BU_:  Airbag BAP_Tester ICAS1_Gateway ICAS1_KommunikationsServer LE1 LE2 Motor_BEV Schaltbetaetigung

BU_:  Airbag BAP_Tester ICAS1_Gateway ICAS1_KommunikationsServer LE1 LE2 Motor_BEV Schaltbetaetigung

BO_ 190 Motor_56: 48 Motor_BEV
 SG_ Motor_56_CRC  : 0|8@1+ (1.000000,0.000000) [0.000000|255.000000] "" ICAS1_Gateway LE1 LE2
 SG_ Motor_56_BZ  : 8|4@1+ (1.000000,0.000000) [0.000000|15.000000] "" ICAS1_Gateway LE1 LE2
 SG_ MO_EM1_MinDrehzahl  : 12|14@1+ (2.000000,-10000.000000) [-10000.000000|22764.000000] "Unit_MinutInver" ICAS1_Gateway LE1
 SG_ MO_EM1_MaxDrehzahl  : 26|14@1+ (2.000000,-10000.000000) [-10000.000000|22764.000000] "Unit_MinutInver" ICAS1_Gateway LE1
 SG_ MO_EM1_DynLimit_AR  : 40|8@1+ (1.000000,0.000000) [0.000000|254.000000] "Unit_NewtoMeter" ICAS1_Gateway LE1
 SG_ MO_EM1_Periode_AR  : 48|8@1+ (0.001953,0.000000) [0.000000|0.496094] "Unit_Secon" ICAS1_Gateway LE1
 SG_ MO_EM1_SollMoment  : 56|12@1+ (0.500000,-1023.000000) [-1023.000000|1023.500000] "Unit_NewtoMeter" ICAS1_Gateway LE1
 SG_ MO_EM1_Sollmodus  : 68|4@1+ (1.000000,0.000000) [0.000000|15.000000] "" ICAS1_Gateway LE1
 SG_ MO_EM1_Min_Leistung  : 72|14@1+ (100.000000,-819000.000000) [-819000.000000|819100.000000] "Unit_Watt" ICAS1_Gateway LE1
 SG_ MO_EM1_Max_Leistung  : 86|14@1+ (100.000000,-819000.000000) [-819000.000000|819100.000000] "Unit_Watt" ICAS1_Gateway LE1
 SG_ MO_EM1_Min_Strom_Lim  : 100|13@1+ (0.500000,-2047.000000) [-2047.000000|2047.500000] "Unit_Amper" ICAS1_Gateway LE1
 SG_ MO_EM1_Max_Strom_Lim  : 113|13@1+ (0.500000,-2047.000000) [-2047.000000|2047.500000] "Unit_Amper" ICAS1_Gateway LE1
 SG_ MO_EM1_AR_Anf  : 126|3@1+ (1.000000,0.000000) [0.000000|7.000000] "" ICAS1_Gateway LE1
 SG_ MO_EM1_Kp_AR  : 129|9@1+ (0.003906,0.000000) [0.000000|1.992188] "Unit_NewtoMeterPerRPM" ICAS1_Gateway LE1
 SG_ MO_EM1_SollSpannung  : 138|12@1+ (0.500000,0.000000) [0.000000|2047.000000] "Unit_Volt" ICAS1_Gateway LE1
 SG_ MO_EM2_MinDrehzahl  : 156|14@1+ (2.000000,-10000.000000) [-10000.000000|22764.000000] "Unit_MinutInver" ICAS1_Gateway LE2
 SG_ MO_EM2_MaxDrehzahl  : 170|14@1+ (2.000000,-10000.000000) [-10000.000000|22764.000000] "Unit_MinutInver" ICAS1_Gateway LE2
 SG_ MO_EM2_DynLimit_AR  : 184|8@1+ (1.000000,0.000000) [0.000000|254.000000] "Unit_NewtoMeter" ICAS1_Gateway LE2
 SG_ MO_EM2_Periode_AR  : 192|8@1+ (0.001953,0.000000) [0.000000|0.496094] "Unit_Secon" ICAS1_Gateway LE2
 SG_ MO_EM2_SollMoment  : 200|12@1+ (0.500000,-1023.000000) [-1023.000000|1023.500000] "Unit_NewtoMeter" ICAS1_Gateway LE2
 SG_ MO_EM2_Sollmodus  : 212|4@1+ (1.000000,0.000000) [0.000000|15.000000] "" ICAS1_Gateway LE2
 SG_ MO_EM2_Min_Leistung  : 216|14@1+ (100.000000,-819000.000000) [-819000.000000|819100.000000] "Unit_Watt" ICAS1_Gateway LE2
 SG_ MO_EM2_Max_Leistung  : 230|14@1+ (100.000000,-819000.000000) [-819000.000000|819100.000000] "Unit_Watt" ICAS1_Gateway LE2
 SG_ MO_EM2_Min_Strom_Lim  : 244|13@1+ (0.500000,-2047.000000) [-2047.000000|2047.500000] "Unit_Amper" ICAS1_Gateway LE2
 SG_ MO_EM2_Max_Strom_Lim  : 257|13@1+ (0.500000,-2047.000000) [-2047.000000|2047.500000] "Unit_Amper" ICAS1_Gateway LE2
 SG_ MO_EM2_AR_Anf  : 270|3@1+ (1.000000,0.000000) [0.000000|7.000000] "" ICAS1_Gateway LE2
 SG_ MO_EM2_SollSpannung  : 282|12@1+ (0.500000,0.000000) [0.000000|2047.000000] "Unit_Volt" ICAS1_Gateway LE2
 SG_ MO_DC_Max_Strom_HV  : 296|8@1+ (0.200000,0.000000) [0.000000|50.800000] "Unit_Amper" ICAS1_Gateway
 SG_ MO_DC_SollSpannung_HV  : 304|8@1+ (2.000000,0.000000) [0.000000|508.000000] "Unit_Volt" ICAS1_Gateway
 SG_ MO_EM1_Max_Moment  : 312|12@1+ (0.500000,-1023.000000) [-1023.000000|1023.500000] "Unit_NewtoMeter" ICAS1_Gateway LE1
 SG_ MO_EM1_Min_Moment  : 324|12@1+ (0.500000,-1023.000000) [-1023.000000|1023.500000] "Unit_NewtoMeter" ICAS1_Gateway LE1
 SG_ MO_EM2_Max_Moment  : 336|12@1+ (0.500000,-1023.000000) [-1023.000000|1023.500000] "Unit_NewtoMeter" ICAS1_Gateway LE2
 SG_ MO_EM2_Min_Moment  : 348|12@1+ (0.500000,-1023.000000) [-1023.000000|1023.500000] "Unit_NewtoMeter" ICAS1_Gateway LE2

BO_ 2463978666 Motor_57: 32 Motor_BEV
 SG_ MO_EM1_Min_Spannung_Lim  : 12|10@1+ (1.000000,0.000000) [0.000000|1021.000000] "Unit_Volt" ICAS1_Gateway LE1
 SG_ MO_EM1_Max_Spannung_Lim  : 22|10@1+ (1.000000,0.000000) [0.000000|1021.000000] "Unit_Volt" ICAS1_Gateway LE1
 SG_ MO_EM1_Min_Leistung_Gesamt  : 32|13@1+ (200.000000,-819000.000000) [-819000.000000|818800.000000] "Unit_Watt" ICAS1_Gateway LE1
 SG_ MO_EM1_Max_Leistung_Gesamt  : 45|13@1+ (200.000000,-819000.000000) [-819000.000000|818800.000000] "Unit_Watt" ICAS1_Gateway LE1
 SG_ MO_EM2_Min_Leistung_Gesamt  : 58|13@1+ (200.000000,-819000.000000) [-819000.000000|818800.000000] "Unit_Watt" ICAS1_Gateway LE2
 SG_ MO_EM2_Max_Leistung_Gesamt  : 71|13@1+ (200.000000,-819000.000000) [-819000.000000|818800.000000] "Unit_Watt" ICAS1_Gateway LE2
 SG_ MO_EM2_Min_Spannung_Lim  : 84|10@1+ (1.000000,0.000000) [0.000000|1021.000000] "Unit_Volt" ICAS1_Gateway LE2
 SG_ MO_EM2_Max_Spannung_Lim  : 94|10@1+ (1.000000,0.000000) [0.000000|1021.000000] "Unit_Volt" ICAS1_Gateway LE2
 SG_ MO_EM1_Generator_Leistung  : 104|8@1+ (100.000000,0.000000) [0.000000|25300.000000] "Unit_Watt" ICAS1_Gateway LE1
 SG_ MO_Verbrauch_EM_Ges  : 120|15@1+ (10.000000,0.000000) [0.000000|327670.000000] "Unit_WattSecond" ICAS1_Gateway ICAS1_KommunikationsServer
 SG_ MO_Verbrauch_EM_Ges_Ueberlauf  : 135|1@1+ (1.000000,0.000000) [0.000000|1.000000] "" ICAS1_Gateway ICAS1_KommunikationsServer
 SG_ MO_Rekuperation_Ges_EM  : 136|15@1+ (10.000000,0.000000) [0.000000|327670.000000] "Unit_WattSecond" ICAS1_Gateway ICAS1_KommunikationsServer
 SG_ MO_Rekuperation_EM_Ges_Ueberlauf  : 151|1@1+ (1.000000,0.000000) [0.000000|1.000000] "" ICAS1_Gateway ICAS1_KommunikationsServer
 SG_ MO_Drehzahl_EM  : 152|13@1+ (8.000000,-32768.000000) [-32768.000000|32744.000000] "Unit_RevPerMinute" ICAS1_Gateway
 SG_ MO_Uebersetzung_EM  : 165|10@1+ (0.031250,0.000000) [0.031250|31.906250] "" ICAS1_Gateway
 SG_ MO_Drehzahl_EM_sek  : 175|13@1+ (8.000000,-32768.000000) [-32768.000000|32744.000000] "Unit_RevPerMinute" ICAS1_Gateway
 SG_ MO_Uebersetzung_EM_sek  : 188|10@1+ (0.031250,0.000000) [0.031250|31.906250] "" ICAS1_Gateway

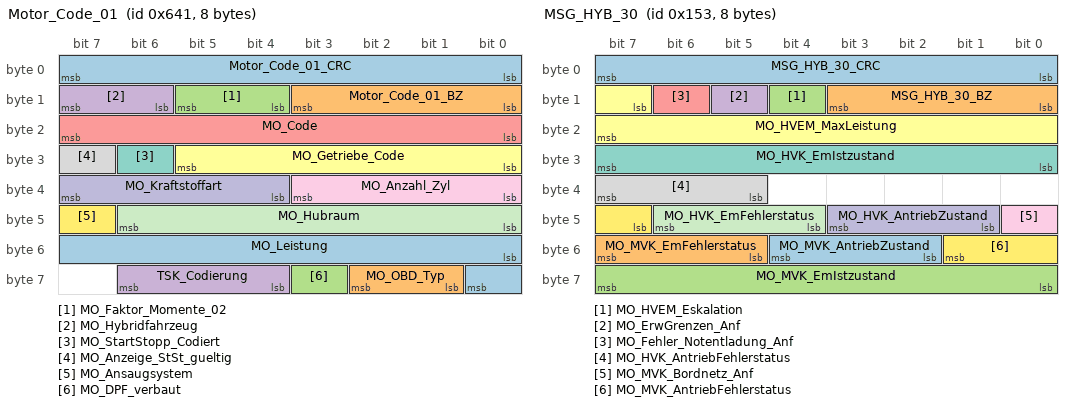
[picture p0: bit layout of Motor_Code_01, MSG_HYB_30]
BO_ 1601 Motor_Code_01: 8 Motor_BEV
 SG_ Motor_Code_01_CRC  : 0|8@1+ (1.000000,0.000000) [0.000000|255.000000] "" ICAS1_Gateway
 SG_ Motor_Code_01_BZ  : 8|4@1+ (1.000000,0.000000) [0.000000|15.000000] "" ICAS1_Gateway
 SG_ MO_Faktor_Momente_02  : 12|2@1+ (1.000000,0.000000) [1.000000|3.000000] "Unit_NewtoMeter" ICAS1_Gateway
 SG_ MO_Hybridfahrzeug  : 14|2@1+ (1.000000,0.000000) [0.000000|3.000000] "" ICAS1_Gateway
 SG_ MO_Code  : 16|8@1+ (1.000000,0.000000) [0.000000|255.000000] "" ICAS1_Gateway
 SG_ MO_Getriebe_Code  : 24|6@1+ (1.000000,0.000000) [0.000000|63.000000] "" ICAS1_Gateway
 SG_ MO_StartStopp_Codiert  : 30|1@1+ (1.000000,0.000000) [0.000000|1.000000] "" ICAS1_Gateway
 SG_ MO_Anzeige_StSt_gueltig  : 31|1@1+ (1.000000,0.000000) [0.000000|1.000000] "" ICAS1_Gateway
 SG_ MO_Anzahl_Zyl  : 32|4@1+ (1.000000,0.000000) [0.000000|15.000000] "" ICAS1_Gateway
 SG_ MO_Kraftstoffart  : 36|4@1+ (1.000000,0.000000) [0.000000|15.000000] "" ICAS1_Gateway ICAS1_KommunikationsServer
 SG_ MO_Hubraum  : 40|7@1+ (0.100000,0.000000) [0.000000|12.700000] "Unit_Liter" ICAS1_Gateway
 SG_ MO_Ansaugsystem  : 47|1@1+ (1.000000,0.000000) [0.000000|1.000000] "" ICAS1_Gateway
 SG_ MO_Leistung  : 48|9@1+ (1.000000,0.000000) [0.000000|511.000000] "Unit_KiloWatt" ICAS1_Gateway
 SG_ MO_OBD_Typ  : 57|2@1+ (1.000000,0.000000) [0.000000|3.000000] "" ICAS1_Gateway
 SG_ MO_DPF_verbaut  : 59|1@1+ (1.000000,0.000000) [0.000000|1.000000] "" ICAS1_Gateway
 SG_ TSK_Codierung  : 60|3@1+ (1.000000,0.000000) [0.000000|7.000000] "" ICAS1_Gateway

BO_ 1155 Motor_Hybrid_06: 8 Motor_BEV
 SG_ Mo_Powermeter_Grenze  : 0|12@1+ (1.000000,0.000000) [0.000000|4092.000000] "" ICAS1_KommunikationsServer
 SG_ MO_Text_Aktivierung_Antrieb  : 12|4@1+ (1.000000,0.000000) [0.000000|15.000000] "" ICAS1_KommunikationsServer
 SG_ MO_Powermeter_Inszenierung_aktiv  : 17|1@1+ (1.000000,0.000000) [0.000000|1.000000] "" Vector__XXX
 SG_ MO_Powermeter_Charge_Grenze  : 18|10@1+ (1.000000,0.000000) [0.000000|1021.000000] "Unit_None" ICAS1_KommunikationsServer
 SG_ MO_Powermeter_Grenze_strategisch  : 28|12@1+ (1.000000,0.000000) [0.000000|4093.000000] "Unit_None" ICAS1_KommunikationsServer
 SG_ MO_Powermeter_untere_E_Grenze  : 40|12@1+ (1.000000,0.000000) [0.000000|4093.000000] "Unit_None" Vector__XXX
 SG_ MO_Powermeter_obere_E_Grenze  : 52|12@1+ (1.000000,0.000000) [0.000000|4093.000000] "Unit_None" Vector__XXX

BO_ 2527679686 MRR_ASM_01: 8 ICAS1_Gateway
 SG_ MRR_HR_ASM_Ereignis  : 0|8@1+ (1.000000,0.000000) [1.000000|254.000000] "" Airbag
 SG_ MRR_HR_ASM_Zeitstempel  : 8|8@1+ (0.080000,0.000000) [0.000000|20.320000] "Unit_Secon" Airbag
 SG_ MRR_HR_ASM_Data_1  : 16|8@1+ (1.000000,0.000000) [0.000000|255.000000] "" Airbag
 SG_ MRR_HR_ASM_Data_2  : 24|8@1+ (1.000000,0.000000) [0.000000|255.000000] "" Airbag
 SG_ MRR_HR_ASM_Data_3  : 32|8@1+ (1.000000,0.000000) [0.000000|255.000000] "" Airbag
 SG_ MRR_HR_ASM_Data_4  : 40|8@1+ (1.000000,0.000000) [0.000000|255.000000] "" Airbag
 SG_ MRR_HR_ASM_Data_5  : 48|8@1+ (1.000000,0.000000) [0.000000|255.000000] "" Airbag
 SG_ MRR_HR_ASM_Data_6  : 56|8@1+ (1.000000,0.000000) [0.000000|255.000000] "" Airbag

BO_ 22 MSG3_WFS_Anfrage: 8 LE2
 SG_ WFS_MSG3_RND  : 0|32@1+ (1.000000,0.000000) [0.000000|4294967295.000000] "" ICAS1_Gateway
 SG_ WFS_MSG3_CRC  : 32|32@1+ (1.000000,0.000000) [0.000000|4294967295.000000] "" ICAS1_Gateway

BO_ 24 MSG4_WFS_Anfrage: 8 LE1
 SG_ WFS_MSG4_RND  : 0|32@1+ (1.000000,0.000000) [0.000000|4294967295.000000] "" ICAS1_Gateway
 SG_ WFS_MSG4_CRC  : 32|32@1+ (1.000000,0.000000) [0.000000|4294967295.000000] "" ICAS1_Gateway

BO_ 339 MSG_HYB_30: 8 Motor_BEV
 SG_ MSG_HYB_30_CRC  : 0|8@1+ (1.000000,0.000000) [0.000000|255.000000] "" Vector__XXX
 SG_ MSG_HYB_30_BZ  : 8|4@1+ (1.000000,0.000000) [0.000000|15.000000] "" Vector__XXX
 SG_ MO_HVEM_Eskalation  : 12|1@1+ (1.000000,0.000000) [0.000000|1.000000] "" ICAS1_Gateway
 SG_ MO_ErwGrenzen_Anf  : 13|1@1+ (1.000000,0.000000) [0.000000|1.000000] "" LE1 LE2
 SG_ MO_Fehler_Notentladung_Anf  : 14|1@1+ (1.000000,0.000000) [0.000000|1.000000] "" Vector__XXX
 SG_ MO_HVEM_MaxLeistung  : 15|9@1+ (50.000000,0.000000) [0.000000|25450.000000] "Unit_Watt" ICAS1_Gateway
 SG_ MO_HVK_EmIstzustand  : 24|8@1+ (1.000000,0.000000) [0.000000|255.000000] "" Vector__XXX
 SG_ MO_HVK_AntriebFehlerstatus  : 37|3@1+ (1.000000,0.000000) [0.000000|7.000000] "" Vector__XXX
 SG_ MO_MVK_Bordnetz_Anf  : 40|1@1+ (1.000000,0.000000) [0.000000|1.000000] "" Vector__XXX
 SG_ MO_HVK_AntriebZustand  : 41|3@1+ (1.000000,0.000000) [0.000000|7.000000] "" Vector__XXX
 SG_ MO_HVK_EmFehlerstatus  : 44|3@1+ (1.000000,0.000000) [0.000000|7.000000] "" Vector__XXX
 SG_ MO_MVK_AntriebFehlerstatus  : 47|3@1+ (1.000000,0.000000) [0.000000|7.000000] "" Vector__XXX
 SG_ MO_MVK_AntriebZustand  : 50|3@1+ (1.000000,0.000000) [0.000000|7.000000] "" Vector__XXX
 SG_ MO_MVK_EmFehlerstatus  : 53|3@1+ (1.000000,0.000000) [0.000000|7.000000] "" Vector__XXX
 SG_ MO_MVK_EmIstzustand  : 56|8@1+ (1.000000,0.000000) [0.000000|255.000000] "" Vector__XXX

BO_ 2600468501 NMH_Airbag_01: 8 Airbag
 SG_ NM_Airbag_01_CBV_AWB  : 12|1@1+ (1.000000,0.000000) [0.000000|1.000000] "" ICAS1_Gateway
 SG_ NM_Airbag_01_CBV_CRI  : 14|1@1+ (1.000000,0.000000) [0.000000|1.000000] "" ICAS1_Gateway
 SG_ NM_Airbag_01_NM_State  : 16|6@1+ (1.000000,0.000000) [0.000000|63.000000] "" LE1 LE2 Motor_BEV Schaltbetaetigung
 SG_ NM_Airbag_01_Car_Wakeup  : 22|1@1+ (1.000000,0.000000) [0.000000|1.000000] "" ICAS1_Gateway
 SG_ NM_Airbag_01_UDS_CC  : 23|1@1+ (1.000000,0.000000) [0.000000|1.000000] "" Vector__XXX
 SG_ NM_Airbag_01_NM_aktiv_KL15  : 24|1@1+ (1.000000,0.000000) [0.000000|1.000000] "" Vector__XXX
 SG_ NM_Airbag_01_NM_aktiv_Diagnose  : 25|1@1+ (1.000000,0.000000) [0.000000|1.000000] "" Vector__XXX
 SG_ NM_Airbag_01_NM_aktiv_Tmin  : 26|1@1+ (1.000000,0.000000) [0.000000|1.000000] "" Vector__XXX
 SG_ NM_Airbag_01_CAB_V10  : 40|24@1+ (1.000000,0.000000) [0.000000|16777215.000000] "" ICAS1_Gateway

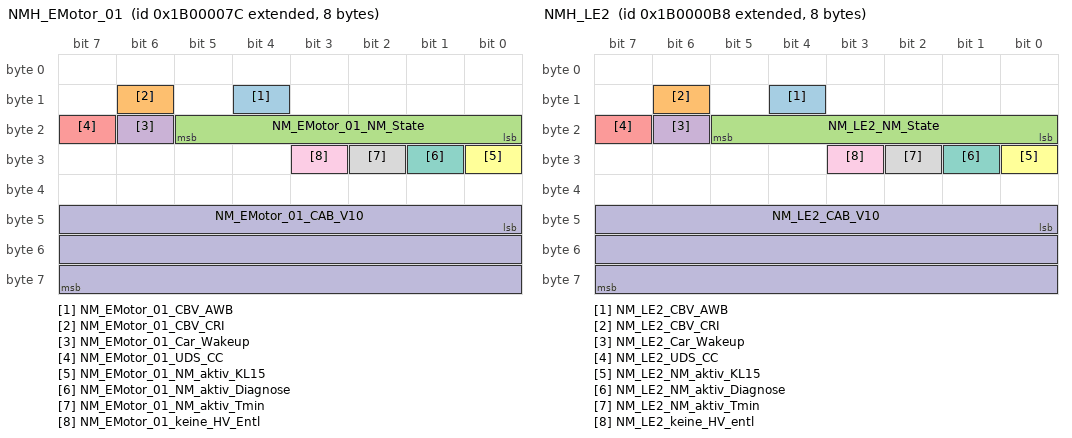
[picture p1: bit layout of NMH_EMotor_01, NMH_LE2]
BO_ 2600468604 NMH_EMotor_01: 8 LE1
 SG_ NM_EMotor_01_CBV_AWB  : 12|1@1+ (1.000000,0.000000) [0.000000|1.000000] "" ICAS1_Gateway
 SG_ NM_EMotor_01_CBV_CRI  : 14|1@1+ (1.000000,0.000000) [0.000000|1.000000] "" ICAS1_Gateway
 SG_ NM_EMotor_01_NM_State  : 16|6@1+ (1.000000,0.000000) [0.000000|63.000000] "" Airbag LE2 Motor_BEV Schaltbetaetigung
 SG_ NM_EMotor_01_Car_Wakeup  : 22|1@1+ (1.000000,0.000000) [0.000000|1.000000] "" ICAS1_Gateway
 SG_ NM_EMotor_01_UDS_CC  : 23|1@1+ (1.000000,0.000000) [0.000000|1.000000] "" Vector__XXX
 SG_ NM_EMotor_01_NM_aktiv_KL15  : 24|1@1+ (1.000000,0.000000) [0.000000|1.000000] "" Vector__XXX
 SG_ NM_EMotor_01_NM_aktiv_Diagnose  : 25|1@1+ (1.000000,0.000000) [0.000000|1.000000] "" Vector__XXX
 SG_ NM_EMotor_01_NM_aktiv_Tmin  : 26|1@1+ (1.000000,0.000000) [0.000000|1.000000] "" Vector__XXX
 SG_ NM_EMotor_01_keine_HV_Entl  : 27|1@1+ (1.000000,0.000000) [0.000000|1.000000] "" Vector__XXX
 SG_ NM_EMotor_01_CAB_V10  : 40|24@1+ (1.000000,0.000000) [0.000000|16777215.000000] "" ICAS1_Gateway

BO_ 2600468496 NMH_Gateway: 8 ICAS1_Gateway
 SG_ NM_Gateway_CBV_AWB  : 12|1@1+ (1.000000,0.000000) [0.000000|1.000000] "" Vector__XXX
 SG_ NM_Gateway_CBV_CRI  : 14|1@1+ (1.000000,0.000000) [0.000000|1.000000] "" Vector__XXX
 SG_ NM_Gateway_NM_State  : 16|6@1+ (1.000000,0.000000) [0.000000|63.000000] "" Airbag LE1 LE2 Motor_BEV Schaltbetaetigung
 SG_ NM_Gateway_Car_Wakeup  : 22|1@1+ (1.000000,0.000000) [0.000000|1.000000] "" Vector__XXX
 SG_ NM_Gateway_UDS_CC  : 23|1@1+ (1.000000,0.000000) [0.000000|1.000000] "" Vector__XXX
 SG_ NM_Gateway_NM_aktiv_KL15  : 24|1@1+ (1.000000,0.000000) [0.000000|1.000000] "" Vector__XXX
 SG_ NM_Gateway_NM_aktiv_Diagnose  : 25|1@1+ (1.000000,0.000000) [0.000000|1.000000] "" Vector__XXX
 SG_ NM_Gateway_NM_aktiv_Tmin  : 26|1@1+ (1.000000,0.000000) [0.000000|1.000000] "" Vector__XXX
 SG_ NM_Gateway_CAB_V10  : 40|24@1+ (1.000000,0.000000) [0.000000|16777215.000000] "" Vector__XXX

BO_ 2600468664 NMH_LE2: 8 LE2
 SG_ NM_LE2_CBV_AWB  : 12|1@1+ (1.000000,0.000000) [0.000000|1.000000] "" ICAS1_Gateway
 SG_ NM_LE2_CBV_CRI  : 14|1@1+ (1.000000,0.000000) [0.000000|1.000000] "" ICAS1_Gateway
 SG_ NM_LE2_NM_State  : 16|6@1+ (1.000000,0.000000) [0.000000|63.000000] "" Airbag LE1 Motor_BEV Schaltbetaetigung
 SG_ NM_LE2_Car_Wakeup  : 22|1@1+ (1.000000,0.000000) [0.000000|1.000000] "" ICAS1_Gateway
 SG_ NM_LE2_UDS_CC  : 23|1@1+ (1.000000,0.000000) [0.000000|1.000000] "" Vector__XXX
 SG_ NM_LE2_NM_aktiv_KL15  : 24|1@1+ (1.000000,0.000000) [0.000000|1.000000] "" Vector__XXX
 SG_ NM_LE2_NM_aktiv_Diagnose  : 25|1@1+ (1.000000,0.000000) [0.000000|1.000000] "" Vector__XXX
 SG_ NM_LE2_NM_aktiv_Tmin  : 26|1@1+ (1.000000,0.000000) [0.000000|1.000000] "" Vector__XXX
 SG_ NM_LE2_keine_HV_entl  : 27|1@1+ (1.000000,0.000000) [0.000000|1.000000] "" Vector__XXX
 SG_ NM_LE2_CAB_V10  : 40|24@1+ (1.000000,0.000000) [0.000000|16777215.000000] "" ICAS1_Gateway

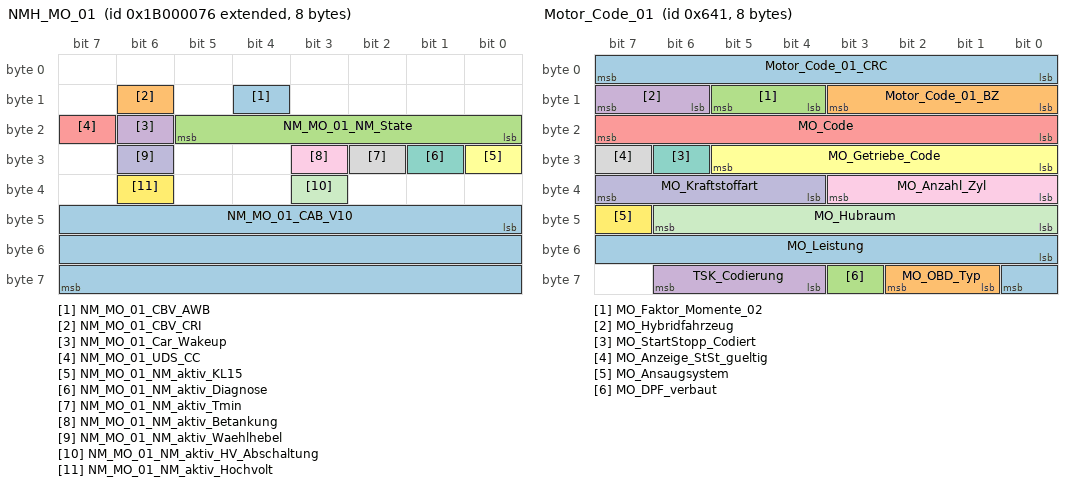
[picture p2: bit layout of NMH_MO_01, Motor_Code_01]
BO_ 2600468598 NMH_MO_01: 8 Motor_BEV
 SG_ NM_MO_01_CBV_AWB  : 12|1@1+ (1.000000,0.000000) [0.000000|1.000000] "" ICAS1_Gateway
 SG_ NM_MO_01_CBV_CRI  : 14|1@1+ (1.000000,0.000000) [0.000000|1.000000] "" ICAS1_Gateway
 SG_ NM_MO_01_NM_State  : 16|6@1+ (1.000000,0.000000) [0.000000|63.000000] "" Airbag LE1 LE2 Schaltbetaetigung
 SG_ NM_MO_01_Car_Wakeup  : 22|1@1+ (1.000000,0.000000) [0.000000|1.000000] "" ICAS1_Gateway
 SG_ NM_MO_01_UDS_CC  : 23|1@1+ (1.000000,0.000000) [0.000000|1.000000] "" Vector__XXX
 SG_ NM_MO_01_NM_aktiv_KL15  : 24|1@1+ (1.000000,0.000000) [0.000000|1.000000] "" Vector__XXX
 SG_ NM_MO_01_NM_aktiv_Diagnose  : 25|1@1+ (1.000000,0.000000) [0.000000|1.000000] "" Vector__XXX
 SG_ NM_MO_01_NM_aktiv_Tmin  : 26|1@1+ (1.000000,0.000000) [0.000000|1.000000] "" Vector__XXX
 SG_ NM_MO_01_NM_aktiv_Betankung  : 27|1@1+ (1.000000,0.000000) [0.000000|1.000000] "" Vector__XXX
 SG_ NM_MO_01_NM_aktiv_Waehlhebel  : 30|1@1+ (1.000000,0.000000) [0.000000|1.000000] "" Vector__XXX
 SG_ NM_MO_01_NM_aktiv_HV_Abschaltung  : 35|1@1+ (1.000000,0.000000) [0.000000|1.000000] "" Vector__XXX
 SG_ NM_MO_01_NM_aktiv_Hochvolt  : 38|1@1+ (1.000000,0.000000) [0.000000|1.000000] "" Vector__XXX
 SG_ NM_MO_01_CAB_V10  : 40|24@1+ (1.000000,0.000000) [0.000000|16777215.000000] "" ICAS1_Gateway

BO_ 2600468733 NMH_Waehlhebel: 8 Schaltbetaetigung
 SG_ NM_Waehlhebel_CBV_AWB  : 12|1@1+ (1.000000,0.000000) [0.000000|1.000000] "" ICAS1_Gateway
 SG_ NM_Waehlhebel_CBV_CRI  : 14|1@1+ (1.000000,0.000000) [0.000000|1.000000] "" ICAS1_Gateway
 SG_ NM_Waehlhebel_NM_State  : 16|6@1+ (1.000000,0.000000) [0.000000|63.000000] "" Airbag LE1 LE2 Motor_BEV
 SG_ NM_Waehlhebel_Car_Wakeup  : 22|1@1+ (1.000000,0.000000) [0.000000|1.000000] "" ICAS1_Gateway
 SG_ NM_Waehlhebel_UDS_CC  : 23|1@1+ (1.000000,0.000000) [0.000000|1.000000] "" Vector__XXX
 SG_ NM_Waehlhebel_NM_aktiv_KL15  : 24|1@1+ (1.000000,0.000000) [0.000000|1.000000] "" Vector__XXX
 SG_ NM_Waehlhebel_NM_aktiv_Diagnose  : 25|1@1+ (1.000000,0.000000) [0.000000|1.000000] "" Vector__XXX
 SG_ NM_Waehlhebel_NM_aktiv_Tmin  : 26|1@1+ (1.000000,0.000000) [0.000000|1.000000] "" Vector__XXX
 SG_ NM_Waehlhebel_CAB_V10  : 40|24@1+ (1.000000,0.000000) [0.000000|16777215.000000] "" ICAS1_Gateway

BO_ 2621440533 OBDC_Airbag_01_Req_FD: 64 ICAS1_Gateway
 SG_ OBDC_Airbag_01_Req_FD_Data  : 0|512@1+ (1.000000,0.000000) [0.000000|13407807929942597099574024998205846127479365820592393377723561443721764030073546976801874298166903427690031858186486050853753882811946569946433649006084096.000000] "" Airbag

BO_ 2621571605 OBDC_Airbag_01_Resp_FD: 64 Airbag
 SG_ OBDC_Airbag_01_Resp_FD_Data  : 0|512@1+ (1.000000,0.000000) [0.000000|13407807929942597099574024998205846127479365820592393377723561443721764030073546976801874298166903427690031858186486050853753882811946569946433649006084096.000000] "" ICAS1_Gateway

BO_ 2621440636 OBDC_EMotor_01_Req_FD: 64 ICAS1_Gateway
 SG_ OBDC_EMotor_01_Req_FD_Data  : 0|512@1+ (1.000000,0.000000) [0.000000|13407807929942597099574024998205846127479365820592393377723561443721764030073546976801874298166903427690031858186486050853753882811946569946433649006084096.000000] "" LE1

BO_ 2621571708 OBDC_EMotor_01_Resp_FD: 64 LE1
 SG_ OBDC_EMotor_01_Resp_FD_Data  : 0|512@1+ (1.000000,0.000000) [0.000000|13407807929942597099574024998205846127479365820592393377723561443721764030073546976801874298166903427690031858186486050853753882811946569946433649006084096.000000] "" ICAS1_Gateway

BO_ 2621440696 OBDC_EMotor_02_Req_FD: 64 ICAS1_Gateway
 SG_ OBDC_EMotor_02_Req_FD_Data  : 0|512@1+ (1.000000,0.000000) [0.000000|13407807929942597099574024998205846127479365820592393377723561443721764030073546976801874298166903427690031858186486050853753882811946569946433649006084096.000000] "" LE2

BO_ 2621571768 OBDC_EMotor_02_Resp_FD: 64 LE2
 SG_ OBDC_EMotor_02_Resp_FD_Data  : 0|512@1+ (1.000000,0.000000) [0.000000|13407807929942597099574024998205846127479365820592393377723561443721764030073546976801874298166903427690031858186486050853753882811946569946433649006084096.000000] "" ICAS1_Gateway

BO_ 2621506048 OBDC_Funktionaler_Req_All_FD: 64 ICAS1_Gateway
 SG_ OBDC_Funktion_Req_All_FD_Data  : 0|512@1+ (1.000000,0.000000) [0.000000|13407807929942597099574024998205846127479365820592393377723561443721764030073546976801874298166903427690031858186486050853753882811946569946433649006084096.000000] "" Airbag LE1 LE2 Motor_BEV

BO_ 2621440630 OBDC_MO_01_Req_FD: 64 ICAS1_Gateway
 SG_ OBDC_MO_01_Req_FD_Data  : 0|512@1+ (1.000000,0.000000) [0.000000|13407807929942597099574024998205846127479365820592393377723561443721764030073546976801874298166903427690031858186486050853753882811946569946433649006084096.000000] "" Motor_BEV

BO_ 2621571702 OBDC_MO_01_Resp_FD: 64 Motor_BEV
 SG_ OBDC_MO_01_Resp_FD_Data  : 0|512@1+ (1.000000,0.000000) [0.000000|13407807929942597099574024998205846127479365820592393377723561443721764030073546976801874298166903427690031858186486050853753882811946569946433649006084096.000000] "" ICAS1_Gateway

BO_ 2564502513 OBDx_allOBD_Req: 8 ICAS1_Gateway
 SG_ OBDx_allOBD_Req_Data  : 0|64@1+ (1.000000,0.000000) [0.000000|18446744073709551616.000000] "" LE1 LE2 Motor_BEV

BO_ 2564425457 OBDx_LE1_Req: 8 ICAS1_Gateway
 SG_ OBDx_LE1_Req_Data  : 0|64@1+ (1.000000,0.000000) [0.000000|18446744073709551616.000000] "" LE1

BO_ 2564485382 OBDx_LE1_Resp: 8 LE1
 SG_ OBDx_LE1_Resp_Data  : 0|64@1+ (1.000000,0.000000) [0.000000|18446744073709551616.000000] "" ICAS1_Gateway

BO_ 2564425713 OBDx_LE2_Req: 8 ICAS1_Gateway
 SG_ OBDx_LE2_Req_Data  : 0|64@1+ (1.000000,0.000000) [0.000000|18446744073709551616.000000] "" LE2

BO_ 2564485383 OBDx_LE2_Resp: 8 LE2
 SG_ OBDx_LE2_Resp_Data  : 0|64@1+ (1.000000,0.000000) [0.000000|18446744073709551616.000000] "" ICAS1_Gateway

BO_ 2564424177 OBDx_MO_01_Req: 8 ICAS1_Gateway
 SG_ OBDx_MO_01_Req_Data  : 0|64@1+ (1.000000,0.000000) [0.000000|18446744073709551616.000000] "" Motor_BEV

BO_ 2564485377 OBDx_MO_01_Resp: 8 Motor_BEV
 SG_ OBDx_MO_01_Resp_Data  : 0|64@1+ (1.000000,0.000000) [0.000000|18446744073709551616.000000] "" ICAS1_Gateway

BO_ 627 OCC_01: 24 ICAS1_Gateway
 SG_ OCC_01_CRC  : 0|8@1+ (1.000000,0.000000) [0.000000|255.000000] "" Vector__XXX
 SG_ OCC_01_BZ  : 8|4@1+ (1.000000,0.000000) [0.000000|15.000000] "" Vector__XXX
 SG_ OCC_Stecker_Status  : 12|2@1+ (1.000000,0.000000) [0.000000|3.000000] "" Vector__XXX
 SG_ OCC_Status_Spgfreiheit  : 14|2@1+ (1.000000,0.000000) [0.000000|3.000000] "" Motor_BEV
 SG_ OCC_DC_IstStrom  : 16|11@1+ (0.100000,0.000000) [0.000000|204.500000] "Unit_Amper" Vector__XXX
 SG_ OCC_CC_Latchstatus_DC_GBT  : 27|3@1+ (1.000000,0.000000) [0.000000|7.000000] "" Vector__XXX
 SG_ OCC_Status_EoHVL  : 30|2@1+ (1.000000,0.000000) [0.000000|3.000000] "" Motor_BEV
 SG_ OCC_I_istAC_Netz_L1  : 32|9@1+ (0.100000,0.000000) [0.000000|50.800000] "Unit_Amper" Vector__XXX
 SG_ OCC_PP_Latchstatus_A  : 41|3@1+ (1.000000,0.000000) [0.000000|7.000000] "" Vector__XXX
 SG_ OCC_PP_Latchstatus_B  : 44|3@1+ (1.000000,0.000000) [0.000000|7.000000] "" Vector__XXX
 SG_ OCC_I_istAC_Netz_L2  : 47|9@1+ (0.100000,0.000000) [0.000000|50.800000] "Unit_Amper" Vector__XXX
 SG_ OCC_I_istAC_Netz_L3  : 56|9@1+ (0.100000,0.000000) [0.000000|50.800000] "Unit_Amper" Vector__XXX
 SG_ OCC_IstModus  : 65|3@1+ (1.000000,0.000000) [0.000000|7.000000] "" Motor_BEV
 SG_ OCC_CP_Status_A  : 68|2@1+ (1.000000,0.000000) [0.000000|3.000000] "" Vector__XXX
 SG_ OCC_CP_Status_B  : 70|2@1+ (1.000000,0.000000) [0.000000|3.000000] "" Vector__XXX
 SG_ OCC_IstSpannung_HV  : 72|10@1+ (1.000000,0.000000) [0.000000|1021.000000] "Unit_Volt" Vector__XXX
 SG_ OCC_PP_Status_A  : 82|2@1+ (1.000000,0.000000) [0.000000|3.000000] "" Vector__XXX
 SG_ OCC_PP_Status_B  : 84|2@1+ (1.000000,0.000000) [0.000000|3.000000] "" Vector__XXX
 SG_ OCC_CC_Status_DC_GBT  : 86|2@1+ (1.000000,0.000000) [0.000000|3.000000] "" Vector__XXX
 SG_ OCC_CC_Fehlerstatus_DC_GBT  : 88|4@1+ (1.000000,0.000000) [0.000000|15.000000] "" Vector__XXX
 SG_ OCC_Temp_Sensor_Fehlerstatus_DC  : 92|4@1+ (1.000000,0.000000) [0.000000|15.000000] "" Vector__XXX
 SG_ OCC_Temp_Sensor_Fehlerstatus_AC  : 96|3@1+ (1.000000,0.000000) [0.000000|7.000000] "" Vector__XXX
 SG_ OCC_Temp_Sensor_Status  : 99|3@1+ (1.000000,0.000000) [0.000000|7.000000] "" Vector__XXX

BU_:  Airbag BAP_Tester ICAS1_Gateway ICAS1_KommunikationsServer LE1 LE2 Motor_BEV Schaltbetaetigung

BO_ 190 Motor_56: 48 Motor_BEV
 SG_ Motor_56_CRC  : 0|8@1+ (1.000000,0.000000) [0.000000|255.000000] "" ICAS1_Gateway LE1 LE2
 SG_ Motor_56_BZ  : 8|4@1+ (1.000000,0.000000) [0.000000|15.000000] "" ICAS1_Gateway LE1 LE2
 SG_ MO_EM1_MinDrehzahl  : 12|14@1+ (2.000000,-10000.000000) [-10000.000000|22764.000000] "Unit_MinutInver" ICAS1_Gateway LE1
 SG_ MO_EM1_MaxDrehzahl  : 26|14@1+ (2.000000,-10000.000000) [-10000.000000|22764.000000] "Unit_MinutInver" ICAS1_Gateway LE1
 SG_ MO_EM1_DynLimit_AR  : 40|8@1+ (1.000000,0.000000) [0.000000|254.000000] "Unit_NewtoMeter" ICAS1_Gateway LE1
 SG_ MO_EM1_Periode_AR  : 48|8@1+ (0.001953,0.000000) [0.000000|0.496094] "Unit_Secon" ICAS1_Gateway LE1
 SG_ MO_EM1_SollMoment  : 56|12@1+ (0.500000,-1023.000000) [-1023.000000|1023.500000] "Unit_NewtoMeter" ICAS1_Gateway LE1
 SG_ MO_EM1_Sollmodus  : 68|4@1+ (1.000000,0.000000) [0.000000|15.000000] "" ICAS1_Gateway LE1
 SG_ MO_EM1_Min_Leistung  : 72|14@1+ (100.000000,-819000.000000) [-819000.000000|819100.000000] "Unit_Watt" ICAS1_Gateway LE1
 SG_ MO_EM1_Max_Leistung  : 86|14@1+ (100.000000,-819000.000000) [-819000.000000|819100.000000] "Unit_Watt" ICAS1_Gateway LE1
 SG_ MO_EM1_Min_Strom_Lim  : 100|13@1+ (0.500000,-2047.000000) [-2047.000000|2047.500000] "Unit_Amper" ICAS1_Gateway LE1
 SG_ MO_EM1_Max_Strom_Lim  : 113|13@1+ (0.500000,-2047.000000) [-2047.000000|2047.500000] "Unit_Amper" ICAS1_Gateway LE1
 SG_ MO_EM1_AR_Anf  : 126|3@1+ (1.000000,0.000000) [0.000000|7.000000] "" ICAS1_Gateway LE1
 SG_ MO_EM1_Kp_AR  : 129|9@1+ (0.003906,0.000000) [0.000000|1.992188] "Unit_NewtoMeterPerRPM" ICAS1_Gateway LE1
 SG_ MO_EM1_SollSpannung  : 138|12@1+ (0.500000,0.000000) [0.000000|2047.000000] "Unit_Volt" ICAS1_Gateway LE1
 SG_ MO_EM2_MinDrehzahl  : 156|14@1+ (2.000000,-10000.000000) [-10000.000000|22764.000000] "Unit_MinutInver" ICAS1_Gateway LE2
 SG_ MO_EM2_MaxDrehzahl  : 170|14@1+ (2.000000,-10000.000000) [-10000.000000|22764.000000] "Unit_MinutInver" ICAS1_Gateway LE2
 SG_ MO_EM2_DynLimit_AR  : 184|8@1+ (1.000000,0.000000) [0.000000|254.000000] "Unit_NewtoMeter" ICAS1_Gateway LE2
 SG_ MO_EM2_Periode_AR  : 192|8@1+ (0.001953,0.000000) [0.000000|0.496094] "Unit_Secon" ICAS1_Gateway LE2
 SG_ MO_EM2_SollMoment  : 200|12@1+ (0.500000,-1023.000000) [-1023.000000|1023.500000] "Unit_NewtoMeter" ICAS1_Gateway LE2
 SG_ MO_EM2_Sollmodus  : 212|4@1+ (1.000000,0.000000) [0.000000|15.000000] "" ICAS1_Gateway LE2
 SG_ MO_EM2_Min_Leistung  : 216|14@1+ (100.000000,-819000.000000) [-819000.000000|819100.000000] "Unit_Watt" ICAS1_Gateway LE2
 SG_ MO_EM2_Max_Leistung  : 230|14@1+ (100.000000,-819000.000000) [-819000.000000|819100.000000] "Unit_Watt" ICAS1_Gateway LE2
 SG_ MO_EM2_Min_Strom_Lim  : 244|13@1+ (0.500000,-2047.000000) [-2047.000000|2047.500000] "Unit_Amper" ICAS1_Gateway LE2
 SG_ MO_EM2_Max_Strom_Lim  : 257|13@1+ (0.500000,-2047.000000) [-2047.000000|2047.500000] "Unit_Amper" ICAS1_Gateway LE2
 SG_ MO_EM2_AR_Anf  : 270|3@1+ (1.000000,0.000000) [0.000000|7.000000] "" ICAS1_Gateway LE2
 SG_ MO_EM2_SollSpannung  : 282|12@1+ (0.500000,0.000000) [0.000000|2047.000000] "Unit_Volt" ICAS1_Gateway LE2
 SG_ MO_DC_Max_Strom_HV  : 296|8@1+ (0.200000,0.000000) [0.000000|50.800000] "Unit_Amper" ICAS1_Gateway
 SG_ MO_DC_SollSpannung_HV  : 304|8@1+ (2.000000,0.000000) [0.000000|508.000000] "Unit_Volt" ICAS1_Gateway
 SG_ MO_EM1_Max_Moment  : 312|12@1+ (0.500000,-1023.000000) [-1023.000000|1023.500000] "Unit_NewtoMeter" ICAS1_Gateway LE1
 SG_ MO_EM1_Min_Moment  : 324|12@1+ (0.500000,-1023.000000) [-1023.000000|1023.500000] "Unit_NewtoMeter" ICAS1_Gateway LE1
 SG_ MO_EM2_Max_Moment  : 336|12@1+ (0.500000,-1023.000000) [-1023.000000|1023.500000] "Unit_NewtoMeter" ICAS1_Gateway LE2
 SG_ MO_EM2_Min_Moment  : 348|12@1+ (0.500000,-1023.000000) [-1023.000000|1023.500000] "Unit_NewtoMeter" ICAS1_Gateway LE2

BO_ 2463978666 Motor_57: 32 Motor_BEV
 SG_ MO_EM1_Min_Spannung_Lim  : 12|10@1+ (1.000000,0.000000) [0.000000|1021.000000] "Unit_Volt" ICAS1_Gateway LE1
 SG_ MO_EM1_Max_Spannung_Lim  : 22|10@1+ (1.000000,0.000000) [0.000000|1021.000000] "Unit_Volt" ICAS1_Gateway LE1
 SG_ MO_EM1_Min_Leistung_Gesamt  : 32|13@1+ (200.000000,-819000.000000) [-819000.000000|818800.000000] "Unit_Watt" ICAS1_Gateway LE1
 SG_ MO_EM1_Max_Leistung_Gesamt  : 45|13@1+ (200.000000,-819000.000000) [-819000.000000|818800.000000] "Unit_Watt" ICAS1_Gateway LE1
 SG_ MO_EM2_Min_Leistung_Gesamt  : 58|13@1+ (200.000000,-819000.000000) [-819000.000000|818800.000000] "Unit_Watt" ICAS1_Gateway LE2
 SG_ MO_EM2_Max_Leistung_Gesamt  : 71|13@1+ (200.000000,-819000.000000) [-819000.000000|818800.000000] "Unit_Watt" ICAS1_Gateway LE2
 SG_ MO_EM2_Min_Spannung_Lim  : 84|10@1+ (1.000000,0.000000) [0.000000|1021.000000] "Unit_Volt" ICAS1_Gateway LE2
 SG_ MO_EM2_Max_Spannung_Lim  : 94|10@1+ (1.000000,0.000000) [0.000000|1021.000000] "Unit_Volt" ICAS1_Gateway LE2
 SG_ MO_EM1_Generator_Leistung  : 104|8@1+ (100.000000,0.000000) [0.000000|25300.000000] "Unit_Watt" ICAS1_Gateway LE1
 SG_ MO_Verbrauch_EM_Ges  : 120|15@1+ (10.000000,0.000000) [0.000000|327670.000000] "Unit_WattSecond" ICAS1_Gateway ICAS1_KommunikationsServer
 SG_ MO_Verbrauch_EM_Ges_Ueberlauf  : 135|1@1+ (1.000000,0.000000) [0.000000|1.000000] "" ICAS1_Gateway ICAS1_KommunikationsServer
 SG_ MO_Rekuperation_Ges_EM  : 136|15@1+ (10.000000,0.000000) [0.000000|327670.000000] "Unit_WattSecond" ICAS1_Gateway ICAS1_KommunikationsServer
 SG_ MO_Rekuperation_EM_Ges_Ueberlauf  : 151|1@1+ (1.000000,0.000000) [0.000000|1.000000] "" ICAS1_Gateway ICAS1_KommunikationsServer
 SG_ MO_Drehzahl_EM  : 152|13@1+ (8.000000,-32768.000000) [-32768.000000|32744.000000] "Unit_RevPerMinute" ICAS1_Gateway
 SG_ MO_Uebersetzung_EM  : 165|10@1+ (0.031250,0.000000) [0.031250|31.906250] "" ICAS1_Gateway
 SG_ MO_Drehzahl_EM_sek  : 175|13@1+ (8.000000,-32768.000000) [-32768.000000|32744.000000] "Unit_RevPerMinute" ICAS1_Gateway
 SG_ MO_Uebersetzung_EM_sek  : 188|10@1+ (0.031250,0.000000) [0.031250|31.906250] "" ICAS1_Gateway

BO_ 1601 Motor_Code_01: 8 Motor_BEV
 SG_ Motor_Code_01_CRC  : 0|8@1+ (1.000000,0.000000) [0.000000|255.000000] "" ICAS1_Gateway
 SG_ Motor_Code_01_BZ  : 8|4@1+ (1.000000,0.000000) [0.000000|15.000000] "" ICAS1_Gateway
 SG_ MO_Faktor_Momente_02  : 12|2@1+ (1.000000,0.000000) [1.000000|3.000000] "Unit_NewtoMeter" ICAS1_Gateway
 SG_ MO_Hybridfahrzeug  : 14|2@1+ (1.000000,0.000000) [0.000000|3.000000] "" ICAS1_Gateway
 SG_ MO_Code  : 16|8@1+ (1.000000,0.000000) [0.000000|255.000000] "" ICAS1_Gateway
 SG_ MO_Getriebe_Code  : 24|6@1+ (1.000000,0.000000) [0.000000|63.000000] "" ICAS1_Gateway
 SG_ MO_StartStopp_Codiert  : 30|1@1+ (1.000000,0.000000) [0.000000|1.000000] "" ICAS1_Gateway
 SG_ MO_Anzeige_StSt_gueltig  : 31|1@1+ (1.000000,0.000000) [0.000000|1.000000] "" ICAS1_Gateway
 SG_ MO_Anzahl_Zyl  : 32|4@1+ (1.000000,0.000000) [0.000000|15.000000] "" ICAS1_Gateway
 SG_ MO_Kraftstoffart  : 36|4@1+ (1.000000,0.000000) [0.000000|15.000000] "" ICAS1_Gateway ICAS1_KommunikationsServer
 SG_ MO_Hubraum  : 40|7@1+ (0.100000,0.000000) [0.000000|12.700000] "Unit_Liter" ICAS1_Gateway
 SG_ MO_Ansaugsystem  : 47|1@1+ (1.000000,0.000000) [0.000000|1.000000] "" ICAS1_Gateway
 SG_ MO_Leistung  : 48|9@1+ (1.000000,0.000000) [0.000000|511.000000] "Unit_KiloWatt" ICAS1_Gateway
 SG_ MO_OBD_Typ  : 57|2@1+ (1.000000,0.000000) [0.000000|3.000000] "" ICAS1_Gateway
 SG_ MO_DPF_verbaut  : 59|1@1+ (1.000000,0.000000) [0.000000|1.000000] "" ICAS1_Gateway
 SG_ TSK_Codierung  : 60|3@1+ (1.000000,0.000000) [0.000000|7.000000] "" ICAS1_Gateway

BO_ 1155 Motor_Hybrid_06: 8 Motor_BEV
 SG_ Mo_Powermeter_Grenze  : 0|12@1+ (1.000000,0.000000) [0.000000|4092.000000] "" ICAS1_KommunikationsServer
 SG_ MO_Text_Aktivierung_Antrieb  : 12|4@1+ (1.000000,0.000000) [0.000000|15.000000] "" ICAS1_KommunikationsServer
 SG_ MO_Powermeter_Inszenierung_aktiv  : 17|1@1+ (1.000000,0.000000) [0.000000|1.000000] "" Vector__XXX
 SG_ MO_Powermeter_Charge_Grenze  : 18|10@1+ (1.000000,0.000000) [0.000000|1021.000000] "Unit_None" ICAS1_KommunikationsServer
 SG_ MO_Powermeter_Grenze_strategisch  : 28|12@1+ (1.000000,0.000000) [0.000000|4093.000000] "Unit_None" ICAS1_KommunikationsServer
 SG_ MO_Powermeter_untere_E_Grenze  : 40|12@1+ (1.000000,0.000000) [0.000000|4093.000000] "Unit_None" Vector__XXX
 SG_ MO_Powermeter_obere_E_Grenze  : 52|12@1+ (1.000000,0.000000) [0.000000|4093.000000] "Unit_None" Vector__XXX

BO_ 2527679686 MRR_ASM_01: 8 ICAS1_Gateway
 SG_ MRR_HR_ASM_Ereignis  : 0|8@1+ (1.000000,0.000000) [1.000000|254.000000] "" Airbag
 SG_ MRR_HR_ASM_Zeitstempel  : 8|8@1+ (0.080000,0.000000) [0.000000|20.320000] "Unit_Secon" Airbag
 SG_ MRR_HR_ASM_Data_1  : 16|8@1+ (1.000000,0.000000) [0.000000|255.000000] "" Airbag
 SG_ MRR_HR_ASM_Data_2  : 24|8@1+ (1.000000,0.000000) [0.000000|255.000000] "" Airbag
 SG_ MRR_HR_ASM_Data_3  : 32|8@1+ (1.000000,0.000000) [0.000000|255.000000] "" Airbag
 SG_ MRR_HR_ASM_Data_4  : 40|8@1+ (1.000000,0.000000) [0.000000|255.000000] "" Airbag
 SG_ MRR_HR_ASM_Data_5  : 48|8@1+ (1.000000,0.000000) [0.000000|255.000000] "" Airbag
 SG_ MRR_HR_ASM_Data_6  : 56|8@1+ (1.000000,0.000000) [0.000000|255.000000] "" Airbag

BO_ 22 MSG3_WFS_Anfrage: 8 LE2
 SG_ WFS_MSG3_RND  : 0|32@1+ (1.000000,0.000000) [0.000000|4294967295.000000] "" ICAS1_Gateway
 SG_ WFS_MSG3_CRC  : 32|32@1+ (1.000000,0.000000) [0.000000|4294967295.000000] "" ICAS1_Gateway

BO_ 24 MSG4_WFS_Anfrage: 8 LE1
 SG_ WFS_MSG4_RND  : 0|32@1+ (1.000000,0.000000) [0.000000|4294967295.000000] "" ICAS1_Gateway
 SG_ WFS_MSG4_CRC  : 32|32@1+ (1.000000,0.000000) [0.000000|4294967295.000000] "" ICAS1_Gateway

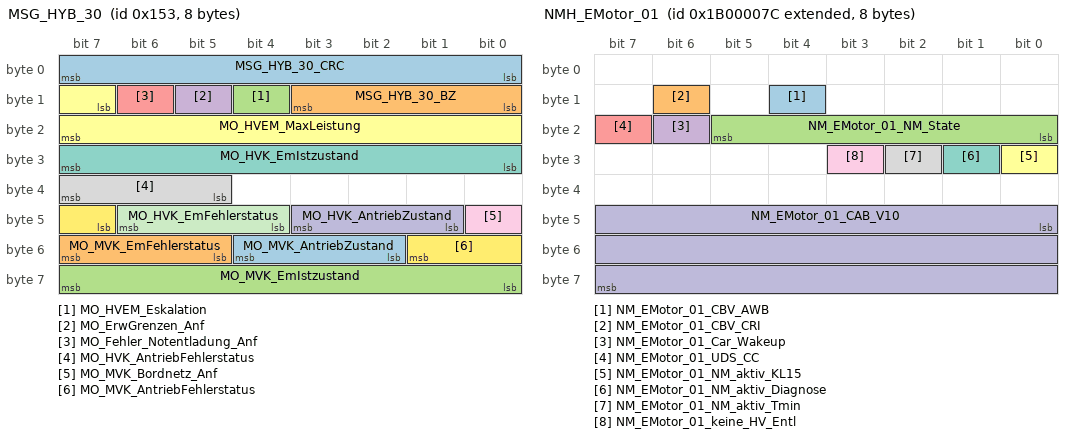
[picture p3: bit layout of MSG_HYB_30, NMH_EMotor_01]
BO_ 339 MSG_HYB_30: 8 Motor_BEV
 SG_ MSG_HYB_30_CRC  : 0|8@1+ (1.000000,0.000000) [0.000000|255.000000] "" Vector__XXX
 SG_ MSG_HYB_30_BZ  : 8|4@1+ (1.000000,0.000000) [0.000000|15.000000] "" Vector__XXX
 SG_ MO_HVEM_Eskalation  : 12|1@1+ (1.000000,0.000000) [0.000000|1.000000] "" ICAS1_Gateway
 SG_ MO_ErwGrenzen_Anf  : 13|1@1+ (1.000000,0.000000) [0.000000|1.000000] "" LE1 LE2
 SG_ MO_Fehler_Notentladung_Anf  : 14|1@1+ (1.000000,0.000000) [0.000000|1.000000] "" Vector__XXX
 SG_ MO_HVEM_MaxLeistung  : 15|9@1+ (50.000000,0.000000) [0.000000|25450.000000] "Unit_Watt" ICAS1_Gateway
 SG_ MO_HVK_EmIstzustand  : 24|8@1+ (1.000000,0.000000) [0.000000|255.000000] "" Vector__XXX
 SG_ MO_HVK_AntriebFehlerstatus  : 37|3@1+ (1.000000,0.000000) [0.000000|7.000000] "" Vector__XXX
 SG_ MO_MVK_Bordnetz_Anf  : 40|1@1+ (1.000000,0.000000) [0.000000|1.000000] "" Vector__XXX
 SG_ MO_HVK_AntriebZustand  : 41|3@1+ (1.000000,0.000000) [0.000000|7.000000] "" Vector__XXX
 SG_ MO_HVK_EmFehlerstatus  : 44|3@1+ (1.000000,0.000000) [0.000000|7.000000] "" Vector__XXX
 SG_ MO_MVK_AntriebFehlerstatus  : 47|3@1+ (1.000000,0.000000) [0.000000|7.000000] "" Vector__XXX
 SG_ MO_MVK_AntriebZustand  : 50|3@1+ (1.000000,0.000000) [0.000000|7.000000] "" Vector__XXX
 SG_ MO_MVK_EmFehlerstatus  : 53|3@1+ (1.000000,0.000000) [0.000000|7.000000] "" Vector__XXX
 SG_ MO_MVK_EmIstzustand  : 56|8@1+ (1.000000,0.000000) [0.000000|255.000000] "" Vector__XXX

BO_ 2600468501 NMH_Airbag_01: 8 Airbag
 SG_ NM_Airbag_01_CBV_AWB  : 12|1@1+ (1.000000,0.000000) [0.000000|1.000000] "" ICAS1_Gateway
 SG_ NM_Airbag_01_CBV_CRI  : 14|1@1+ (1.000000,0.000000) [0.000000|1.000000] "" ICAS1_Gateway
 SG_ NM_Airbag_01_NM_State  : 16|6@1+ (1.000000,0.000000) [0.000000|63.000000] "" LE1 LE2 Motor_BEV Schaltbetaetigung
 SG_ NM_Airbag_01_Car_Wakeup  : 22|1@1+ (1.000000,0.000000) [0.000000|1.000000] "" ICAS1_Gateway
 SG_ NM_Airbag_01_UDS_CC  : 23|1@1+ (1.000000,0.000000) [0.000000|1.000000] "" Vector__XXX
 SG_ NM_Airbag_01_NM_aktiv_KL15  : 24|1@1+ (1.000000,0.000000) [0.000000|1.000000] "" Vector__XXX
 SG_ NM_Airbag_01_NM_aktiv_Diagnose  : 25|1@1+ (1.000000,0.000000) [0.000000|1.000000] "" Vector__XXX
 SG_ NM_Airbag_01_NM_aktiv_Tmin  : 26|1@1+ (1.000000,0.000000) [0.000000|1.000000] "" Vector__XXX
 SG_ NM_Airbag_01_CAB_V10  : 40|24@1+ (1.000000,0.000000) [0.000000|16777215.000000] "" ICAS1_Gateway

BO_ 2600468604 NMH_EMotor_01: 8 LE1
 SG_ NM_EMotor_01_CBV_AWB  : 12|1@1+ (1.000000,0.000000) [0.000000|1.000000] "" ICAS1_Gateway
 SG_ NM_EMotor_01_CBV_CRI  : 14|1@1+ (1.000000,0.000000) [0.000000|1.000000] "" ICAS1_Gateway
 SG_ NM_EMotor_01_NM_State  : 16|6@1+ (1.000000,0.000000) [0.000000|63.000000] "" Airbag LE2 Motor_BEV Schaltbetaetigung
 SG_ NM_EMotor_01_Car_Wakeup  : 22|1@1+ (1.000000,0.000000) [0.000000|1.000000] "" ICAS1_Gateway
 SG_ NM_EMotor_01_UDS_CC  : 23|1@1+ (1.000000,0.000000) [0.000000|1.000000] "" Vector__XXX
 SG_ NM_EMotor_01_NM_aktiv_KL15  : 24|1@1+ (1.000000,0.000000) [0.000000|1.000000] "" Vector__XXX
 SG_ NM_EMotor_01_NM_aktiv_Diagnose  : 25|1@1+ (1.000000,0.000000) [0.000000|1.000000] "" Vector__XXX
 SG_ NM_EMotor_01_NM_aktiv_Tmin  : 26|1@1+ (1.000000,0.000000) [0.000000|1.000000] "" Vector__XXX
 SG_ NM_EMotor_01_keine_HV_Entl  : 27|1@1+ (1.000000,0.000000) [0.000000|1.000000] "" Vector__XXX
 SG_ NM_EMotor_01_CAB_V10  : 40|24@1+ (1.000000,0.000000) [0.000000|16777215.000000] "" ICAS1_Gateway

BO_ 2600468496 NMH_Gateway: 8 ICAS1_Gateway
 SG_ NM_Gateway_CBV_AWB  : 12|1@1+ (1.000000,0.000000) [0.000000|1.000000] "" Vector__XXX
 SG_ NM_Gateway_CBV_CRI  : 14|1@1+ (1.000000,0.000000) [0.000000|1.000000] "" Vector__XXX
 SG_ NM_Gateway_NM_State  : 16|6@1+ (1.000000,0.000000) [0.000000|63.000000] "" Airbag LE1 LE2 Motor_BEV Schaltbetaetigung
 SG_ NM_Gateway_Car_Wakeup  : 22|1@1+ (1.000000,0.000000) [0.000000|1.000000] "" Vector__XXX
 SG_ NM_Gateway_UDS_CC  : 23|1@1+ (1.000000,0.000000) [0.000000|1.000000] "" Vector__XXX
 SG_ NM_Gateway_NM_aktiv_KL15  : 24|1@1+ (1.000000,0.000000) [0.000000|1.000000] "" Vector__XXX
 SG_ NM_Gateway_NM_aktiv_Diagnose  : 25|1@1+ (1.000000,0.000000) [0.000000|1.000000] "" Vector__XXX
 SG_ NM_Gateway_NM_aktiv_Tmin  : 26|1@1+ (1.000000,0.000000) [0.000000|1.000000] "" Vector__XXX
 SG_ NM_Gateway_CAB_V10  : 40|24@1+ (1.000000,0.000000) [0.000000|16777215.000000] "" Vector__XXX

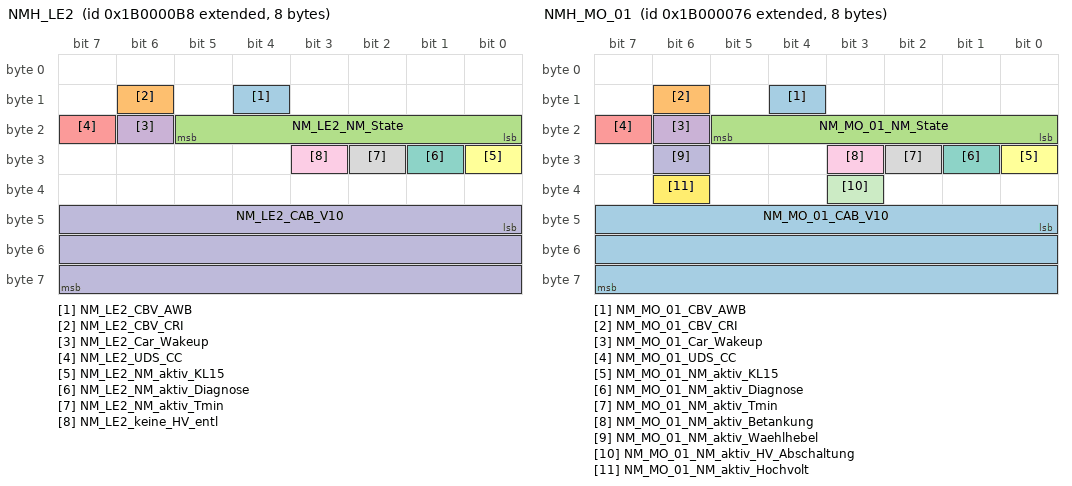
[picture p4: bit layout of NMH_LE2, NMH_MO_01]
BO_ 2600468664 NMH_LE2: 8 LE2
 SG_ NM_LE2_CBV_AWB  : 12|1@1+ (1.000000,0.000000) [0.000000|1.000000] "" ICAS1_Gateway
 SG_ NM_LE2_CBV_CRI  : 14|1@1+ (1.000000,0.000000) [0.000000|1.000000] "" ICAS1_Gateway
 SG_ NM_LE2_NM_State  : 16|6@1+ (1.000000,0.000000) [0.000000|63.000000] "" Airbag LE1 Motor_BEV Schaltbetaetigung
 SG_ NM_LE2_Car_Wakeup  : 22|1@1+ (1.000000,0.000000) [0.000000|1.000000] "" ICAS1_Gateway
 SG_ NM_LE2_UDS_CC  : 23|1@1+ (1.000000,0.000000) [0.000000|1.000000] "" Vector__XXX
 SG_ NM_LE2_NM_aktiv_KL15  : 24|1@1+ (1.000000,0.000000) [0.000000|1.000000] "" Vector__XXX
 SG_ NM_LE2_NM_aktiv_Diagnose  : 25|1@1+ (1.000000,0.000000) [0.000000|1.000000] "" Vector__XXX
 SG_ NM_LE2_NM_aktiv_Tmin  : 26|1@1+ (1.000000,0.000000) [0.000000|1.000000] "" Vector__XXX
 SG_ NM_LE2_keine_HV_entl  : 27|1@1+ (1.000000,0.000000) [0.000000|1.000000] "" Vector__XXX
 SG_ NM_LE2_CAB_V10  : 40|24@1+ (1.000000,0.000000) [0.000000|16777215.000000] "" ICAS1_Gateway

BO_ 2600468598 NMH_MO_01: 8 Motor_BEV
 SG_ NM_MO_01_CBV_AWB  : 12|1@1+ (1.000000,0.000000) [0.000000|1.000000] "" ICAS1_Gateway
 SG_ NM_MO_01_CBV_CRI  : 14|1@1+ (1.000000,0.000000) [0.000000|1.000000] "" ICAS1_Gateway
 SG_ NM_MO_01_NM_State  : 16|6@1+ (1.000000,0.000000) [0.000000|63.000000] "" Airbag LE1 LE2 Schaltbetaetigung
 SG_ NM_MO_01_Car_Wakeup  : 22|1@1+ (1.000000,0.000000) [0.000000|1.000000] "" ICAS1_Gateway
 SG_ NM_MO_01_UDS_CC  : 23|1@1+ (1.000000,0.000000) [0.000000|1.000000] "" Vector__XXX
 SG_ NM_MO_01_NM_aktiv_KL15  : 24|1@1+ (1.000000,0.000000) [0.000000|1.000000] "" Vector__XXX
 SG_ NM_MO_01_NM_aktiv_Diagnose  : 25|1@1+ (1.000000,0.000000) [0.000000|1.000000] "" Vector__XXX
 SG_ NM_MO_01_NM_aktiv_Tmin  : 26|1@1+ (1.000000,0.000000) [0.000000|1.000000] "" Vector__XXX
 SG_ NM_MO_01_NM_aktiv_Betankung  : 27|1@1+ (1.000000,0.000000) [0.000000|1.000000] "" Vector__XXX
 SG_ NM_MO_01_NM_aktiv_Waehlhebel  : 30|1@1+ (1.000000,0.000000) [0.000000|1.000000] "" Vector__XXX
 SG_ NM_MO_01_NM_aktiv_HV_Abschaltung  : 35|1@1+ (1.000000,0.000000) [0.000000|1.000000] "" Vector__XXX
 SG_ NM_MO_01_NM_aktiv_Hochvolt  : 38|1@1+ (1.000000,0.000000) [0.000000|1.000000] "" Vector__XXX
 SG_ NM_MO_01_CAB_V10  : 40|24@1+ (1.000000,0.000000) [0.000000|16777215.000000] "" ICAS1_Gateway

BO_ 2600468733 NMH_Waehlhebel: 8 Schaltbetaetigung
 SG_ NM_Waehlhebel_CBV_AWB  : 12|1@1+ (1.000000,0.000000) [0.000000|1.000000] "" ICAS1_Gateway
 SG_ NM_Waehlhebel_CBV_CRI  : 14|1@1+ (1.000000,0.000000) [0.000000|1.000000] "" ICAS1_Gateway
 SG_ NM_Waehlhebel_NM_State  : 16|6@1+ (1.000000,0.000000) [0.000000|63.000000] "" Airbag LE1 LE2 Motor_BEV
 SG_ NM_Waehlhebel_Car_Wakeup  : 22|1@1+ (1.000000,0.000000) [0.000000|1.000000] "" ICAS1_Gateway
 SG_ NM_Waehlhebel_UDS_CC  : 23|1@1+ (1.000000,0.000000) [0.000000|1.000000] "" Vector__XXX
 SG_ NM_Waehlhebel_NM_aktiv_KL15  : 24|1@1+ (1.000000,0.000000) [0.000000|1.000000] "" Vector__XXX
 SG_ NM_Waehlhebel_NM_aktiv_Diagnose  : 25|1@1+ (1.000000,0.000000) [0.000000|1.000000] "" Vector__XXX
 SG_ NM_Waehlhebel_NM_aktiv_Tmin  : 26|1@1+ (1.000000,0.000000) [0.000000|1.000000] "" Vector__XXX
 SG_ NM_Waehlhebel_CAB_V10  : 40|24@1+ (1.000000,0.000000) [0.000000|16777215.000000] "" ICAS1_Gateway

BO_ 2621440533 OBDC_Airbag_01_Req_FD: 64 ICAS1_Gateway
 SG_ OBDC_Airbag_01_Req_FD_Data  : 0|512@1+ (1.000000,0.000000) [0.000000|13407807929942597099574024998205846127479365820592393377723561443721764030073546976801874298166903427690031858186486050853753882811946569946433649006084096.000000] "" Airbag

BO_ 2621571605 OBDC_Airbag_01_Resp_FD: 64 Airbag
 SG_ OBDC_Airbag_01_Resp_FD_Data  : 0|512@1+ (1.000000,0.000000) [0.000000|13407807929942597099574024998205846127479365820592393377723561443721764030073546976801874298166903427690031858186486050853753882811946569946433649006084096.000000] "" ICAS1_Gateway

BO_ 2621440636 OBDC_EMotor_01_Req_FD: 64 ICAS1_Gateway
 SG_ OBDC_EMotor_01_Req_FD_Data  : 0|512@1+ (1.000000,0.000000) [0.000000|13407807929942597099574024998205846127479365820592393377723561443721764030073546976801874298166903427690031858186486050853753882811946569946433649006084096.000000] "" LE1

BO_ 2621571708 OBDC_EMotor_01_Resp_FD: 64 LE1
 SG_ OBDC_EMotor_01_Resp_FD_Data  : 0|512@1+ (1.000000,0.000000) [0.000000|13407807929942597099574024998205846127479365820592393377723561443721764030073546976801874298166903427690031858186486050853753882811946569946433649006084096.000000] "" ICAS1_Gateway

BO_ 2621440696 OBDC_EMotor_02_Req_FD: 64 ICAS1_Gateway
 SG_ OBDC_EMotor_02_Req_FD_Data  : 0|512@1+ (1.000000,0.000000) [0.000000|13407807929942597099574024998205846127479365820592393377723561443721764030073546976801874298166903427690031858186486050853753882811946569946433649006084096.000000] "" LE2

BO_ 2621571768 OBDC_EMotor_02_Resp_FD: 64 LE2
 SG_ OBDC_EMotor_02_Resp_FD_Data  : 0|512@1+ (1.000000,0.000000) [0.000000|13407807929942597099574024998205846127479365820592393377723561443721764030073546976801874298166903427690031858186486050853753882811946569946433649006084096.000000] "" ICAS1_Gateway

BO_ 2621506048 OBDC_Funktionaler_Req_All_FD: 64 ICAS1_Gateway
 SG_ OBDC_Funktion_Req_All_FD_Data  : 0|512@1+ (1.000000,0.000000) [0.000000|13407807929942597099574024998205846127479365820592393377723561443721764030073546976801874298166903427690031858186486050853753882811946569946433649006084096.000000] "" Airbag LE1 LE2 Motor_BEV

BO_ 2621440630 OBDC_MO_01_Req_FD: 64 ICAS1_Gateway
 SG_ OBDC_MO_01_Req_FD_Data  : 0|512@1+ (1.000000,0.000000) [0.000000|13407807929942597099574024998205846127479365820592393377723561443721764030073546976801874298166903427690031858186486050853753882811946569946433649006084096.000000] "" Motor_BEV

BO_ 2621571702 OBDC_MO_01_Resp_FD: 64 Motor_BEV
 SG_ OBDC_MO_01_Resp_FD_Data  : 0|512@1+ (1.000000,0.000000) [0.000000|13407807929942597099574024998205846127479365820592393377723561443721764030073546976801874298166903427690031858186486050853753882811946569946433649006084096.000000] "" ICAS1_Gateway

BO_ 2564502513 OBDx_allOBD_Req: 8 ICAS1_Gateway
 SG_ OBDx_allOBD_Req_Data  : 0|64@1+ (1.000000,0.000000) [0.000000|18446744073709551616.000000] "" LE1 LE2 Motor_BEV

BO_ 2564425457 OBDx_LE1_Req: 8 ICAS1_Gateway
 SG_ OBDx_LE1_Req_Data  : 0|64@1+ (1.000000,0.000000) [0.000000|18446744073709551616.000000] "" LE1

BO_ 2564485382 OBDx_LE1_Resp: 8 LE1
 SG_ OBDx_LE1_Resp_Data  : 0|64@1+ (1.000000,0.000000) [0.000000|18446744073709551616.000000] "" ICAS1_Gateway

BO_ 2564425713 OBDx_LE2_Req: 8 ICAS1_Gateway
 SG_ OBDx_LE2_Req_Data  : 0|64@1+ (1.000000,0.000000) [0.000000|18446744073709551616.000000] "" LE2

BO_ 2564485383 OBDx_LE2_Resp: 8 LE2
 SG_ OBDx_LE2_Resp_Data  : 0|64@1+ (1.000000,0.000000) [0.000000|18446744073709551616.000000] "" ICAS1_Gateway

BO_ 2564424177 OBDx_MO_01_Req: 8 ICAS1_Gateway
 SG_ OBDx_MO_01_Req_Data  : 0|64@1+ (1.000000,0.000000) [0.000000|18446744073709551616.000000] "" Motor_BEV

BO_ 2564485377 OBDx_MO_01_Resp: 8 Motor_BEV
 SG_ OBDx_MO_01_Resp_Data  : 0|64@1+ (1.000000,0.000000) [0.000000|18446744073709551616.000000] "" ICAS1_Gateway

BO_ 627 OCC_01: 24 ICAS1_Gateway
 SG_ OCC_01_CRC  : 0|8@1+ (1.000000,0.000000) [0.000000|255.000000] "" Vector__XXX
 SG_ OCC_01_BZ  : 8|4@1+ (1.000000,0.000000) [0.000000|15.000000] "" Vector__XXX
 SG_ OCC_Stecker_Status  : 12|2@1+ (1.000000,0.000000) [0.000000|3.000000] "" Vector__XXX
 SG_ OCC_Status_Spgfreiheit  : 14|2@1+ (1.000000,0.000000) [0.000000|3.000000] "" Motor_BEV
 SG_ OCC_DC_IstStrom  : 16|11@1+ (0.100000,0.000000) [0.000000|204.500000] "Unit_Amper" Vector__XXX
 SG_ OCC_CC_Latchstatus_DC_GBT  : 27|3@1+ (1.000000,0.000000) [0.000000|7.000000] "" Vector__XXX
 SG_ OCC_Status_EoHVL  : 30|2@1+ (1.000000,0.000000) [0.000000|3.000000] "" Motor_BEV
 SG_ OCC_I_istAC_Netz_L1  : 32|9@1+ (0.100000,0.000000) [0.000000|50.800000] "Unit_Amper" Vector__XXX
 SG_ OCC_PP_Latchstatus_A  : 41|3@1+ (1.000000,0.000000) [0.000000|7.000000] "" Vector__XXX
 SG_ OCC_PP_Latchstatus_B  : 44|3@1+ (1.000000,0.000000) [0.000000|7.000000] "" Vector__XXX
 SG_ OCC_I_istAC_Netz_L2  : 47|9@1+ (0.100000,0.000000) [0.000000|50.800000] "Unit_Amper" Vector__XXX
 SG_ OCC_I_istAC_Netz_L3  : 56|9@1+ (0.100000,0.000000) [0.000000|50.800000] "Unit_Amper" Vector__XXX
 SG_ OCC_IstModus  : 65|3@1+ (1.000000,0.000000) [0.000000|7.000000] "" Motor_BEV
 SG_ OCC_CP_Status_A  : 68|2@1+ (1.000000,0.000000) [0.000000|3.000000] "" Vector__XXX
 SG_ OCC_CP_Status_B  : 70|2@1+ (1.000000,0.000000) [0.000000|3.000000] "" Vector__XXX
 SG_ OCC_IstSpannung_HV  : 72|10@1+ (1.000000,0.000000) [0.000000|1021.000000] "Unit_Volt" Vector__XXX
 SG_ OCC_PP_Status_A  : 82|2@1+ (1.000000,0.000000) [0.000000|3.000000] "" Vector__XXX
 SG_ OCC_PP_Status_B  : 84|2@1+ (1.000000,0.000000) [0.000000|3.000000] "" Vector__XXX
 SG_ OCC_CC_Status_DC_GBT  : 86|2@1+ (1.000000,0.000000) [0.000000|3.000000] "" Vector__XXX
 SG_ OCC_CC_Fehlerstatus_DC_GBT  : 88|4@1+ (1.000000,0.000000) [0.000000|15.000000] "" Vector__XXX
 SG_ OCC_Temp_Sensor_Fehlerstatus_DC  : 92|4@1+ (1.000000,0.000000) [0.000000|15.000000] "" Vector__XXX
 SG_ OCC_Temp_Sensor_Fehlerstatus_AC  : 96|3@1+ (1.000000,0.000000) [0.000000|7.000000] "" Vector__XXX
 SG_ OCC_Temp_Sensor_Status  : 99|3@1+ (1.000000,0.000000) [0.000000|7.000000] "" Vector__XXX

BU_:  Airbag BAP_Tester ICAS1_Gateway ICAS1_KommunikationsServer LE1 LE2 Motor_BEV Schaltbetaetigung

BO_ 190 Motor_56: 48 Motor_BEV
 SG_ Motor_56_CRC  : 0|8@1+ (1.000000,0.000000) [0.000000|255.000000] "" ICAS1_Gateway LE1 LE2
 SG_ Motor_56_BZ  : 8|4@1+ (1.000000,0.000000) [0.000000|15.000000] "" ICAS1_Gateway LE1 LE2
 SG_ MO_EM1_MinDrehzahl  : 12|14@1+ (2.000000,-10000.000000) [-10000.000000|22764.000000] "Unit_MinutInver" ICAS1_Gateway LE1
 SG_ MO_EM1_MaxDrehzahl  : 26|14@1+ (2.000000,-10000.000000) [-10000.000000|22764.000000] "Unit_MinutInver" ICAS1_Gateway LE1
 SG_ MO_EM1_DynLimit_AR  : 40|8@1+ (1.000000,0.000000) [0.000000|254.000000] "Unit_NewtoMeter" ICAS1_Gateway LE1
 SG_ MO_EM1_Periode_AR  : 48|8@1+ (0.001953,0.000000) [0.000000|0.496094] "Unit_Secon" ICAS1_Gateway LE1
 SG_ MO_EM1_SollMoment  : 56|12@1+ (0.500000,-1023.000000) [-1023.000000|1023.500000] "Unit_NewtoMeter" ICAS1_Gateway LE1
 SG_ MO_EM1_Sollmodus  : 68|4@1+ (1.000000,0.000000) [0.000000|15.000000] "" ICAS1_Gateway LE1
 SG_ MO_EM1_Min_Leistung  : 72|14@1+ (100.000000,-819000.000000) [-819000.000000|819100.000000] "Unit_Watt" ICAS1_Gateway LE1
 SG_ MO_EM1_Max_Leistung  : 86|14@1+ (100.000000,-819000.000000) [-819000.000000|819100.000000] "Unit_Watt" ICAS1_Gateway LE1
 SG_ MO_EM1_Min_Strom_Lim  : 100|13@1+ (0.500000,-2047.000000) [-2047.000000|2047.500000] "Unit_Amper" ICAS1_Gateway LE1
 SG_ MO_EM1_Max_Strom_Lim  : 113|13@1+ (0.500000,-2047.000000) [-2047.000000|2047.500000] "Unit_Amper" ICAS1_Gateway LE1
 SG_ MO_EM1_AR_Anf  : 126|3@1+ (1.000000,0.000000) [0.000000|7.000000] "" ICAS1_Gateway LE1
 SG_ MO_EM1_Kp_AR  : 129|9@1+ (0.003906,0.000000) [0.000000|1.992188] "Unit_NewtoMeterPerRPM" ICAS1_Gateway LE1
 SG_ MO_EM1_SollSpannung  : 138|12@1+ (0.500000,0.000000) [0.000000|2047.000000] "Unit_Volt" ICAS1_Gateway LE1
 SG_ MO_EM2_MinDrehzahl  : 156|14@1+ (2.000000,-10000.000000) [-10000.000000|22764.000000] "Unit_MinutInver" ICAS1_Gateway LE2
 SG_ MO_EM2_MaxDrehzahl  : 170|14@1+ (2.000000,-10000.000000) [-10000.000000|22764.000000] "Unit_MinutInver" ICAS1_Gateway LE2
 SG_ MO_EM2_DynLimit_AR  : 184|8@1+ (1.000000,0.000000) [0.000000|254.000000] "Unit_NewtoMeter" ICAS1_Gateway LE2
 SG_ MO_EM2_Periode_AR  : 192|8@1+ (0.001953,0.000000) [0.000000|0.496094] "Unit_Secon" ICAS1_Gateway LE2
 SG_ MO_EM2_SollMoment  : 200|12@1+ (0.500000,-1023.000000) [-1023.000000|1023.500000] "Unit_NewtoMeter" ICAS1_Gateway LE2
 SG_ MO_EM2_Sollmodus  : 212|4@1+ (1.000000,0.000000) [0.000000|15.000000] "" ICAS1_Gateway LE2
 SG_ MO_EM2_Min_Leistung  : 216|14@1+ (100.000000,-819000.000000) [-819000.000000|819100.000000] "Unit_Watt" ICAS1_Gateway LE2
 SG_ MO_EM2_Max_Leistung  : 230|14@1+ (100.000000,-819000.000000) [-819000.000000|819100.000000] "Unit_Watt" ICAS1_Gateway LE2
 SG_ MO_EM2_Min_Strom_Lim  : 244|13@1+ (0.500000,-2047.000000) [-2047.000000|2047.500000] "Unit_Amper" ICAS1_Gateway LE2
 SG_ MO_EM2_Max_Strom_Lim  : 257|13@1+ (0.500000,-2047.000000) [-2047.000000|2047.500000] "Unit_Amper" ICAS1_Gateway LE2
 SG_ MO_EM2_AR_Anf  : 270|3@1+ (1.000000,0.000000) [0.000000|7.000000] "" ICAS1_Gateway LE2
 SG_ MO_EM2_SollSpannung  : 282|12@1+ (0.500000,0.000000) [0.000000|2047.000000] "Unit_Volt" ICAS1_Gateway LE2
 SG_ MO_DC_Max_Strom_HV  : 296|8@1+ (0.200000,0.000000) [0.000000|50.800000] "Unit_Amper" ICAS1_Gateway
 SG_ MO_DC_SollSpannung_HV  : 304|8@1+ (2.000000,0.000000) [0.000000|508.000000] "Unit_Volt" ICAS1_Gateway
 SG_ MO_EM1_Max_Moment  : 312|12@1+ (0.500000,-1023.000000) [-1023.000000|1023.500000] "Unit_NewtoMeter" ICAS1_Gateway LE1
 SG_ MO_EM1_Min_Moment  : 324|12@1+ (0.500000,-1023.000000) [-1023.000000|1023.500000] "Unit_NewtoMeter" ICAS1_Gateway LE1
 SG_ MO_EM2_Max_Moment  : 336|12@1+ (0.500000,-1023.000000) [-1023.000000|1023.500000] "Unit_NewtoMeter" ICAS1_Gateway LE2
 SG_ MO_EM2_Min_Moment  : 348|12@1+ (0.500000,-1023.000000) [-1023.000000|1023.500000] "Unit_NewtoMeter" ICAS1_Gateway LE2

BO_ 2463978666 Motor_57: 32 Motor_BEV
 SG_ MO_EM1_Min_Spannung_Lim  : 12|10@1+ (1.000000,0.000000) [0.000000|1021.000000] "Unit_Volt" ICAS1_Gateway LE1
 SG_ MO_EM1_Max_Spannung_Lim  : 22|10@1+ (1.000000,0.000000) [0.000000|1021.000000] "Unit_Volt" ICAS1_Gateway LE1
 SG_ MO_EM1_Min_Leistung_Gesamt  : 32|13@1+ (200.000000,-819000.000000) [-819000.000000|818800.000000] "Unit_Watt" ICAS1_Gateway LE1
 SG_ MO_EM1_Max_Leistung_Gesamt  : 45|13@1+ (200.000000,-819000.000000) [-819000.000000|818800.000000] "Unit_Watt" ICAS1_Gateway LE1
 SG_ MO_EM2_Min_Leistung_Gesamt  : 58|13@1+ (200.000000,-819000.000000) [-819000.000000|818800.000000] "Unit_Watt" ICAS1_Gateway LE2
 SG_ MO_EM2_Max_Leistung_Gesamt  : 71|13@1+ (200.000000,-819000.000000) [-819000.000000|818800.000000] "Unit_Watt" ICAS1_Gateway LE2
 SG_ MO_EM2_Min_Spannung_Lim  : 84|10@1+ (1.000000,0.000000) [0.000000|1021.000000] "Unit_Volt" ICAS1_Gateway LE2
 SG_ MO_EM2_Max_Spannung_Lim  : 94|10@1+ (1.000000,0.000000) [0.000000|1021.000000] "Unit_Volt" ICAS1_Gateway LE2
 SG_ MO_EM1_Generator_Leistung  : 104|8@1+ (100.000000,0.000000) [0.000000|25300.000000] "Unit_Watt" ICAS1_Gateway LE1
 SG_ MO_Verbrauch_EM_Ges  : 120|15@1+ (10.000000,0.000000) [0.000000|327670.000000] "Unit_WattSecond" ICAS1_Gateway ICAS1_KommunikationsServer
 SG_ MO_Verbrauch_EM_Ges_Ueberlauf  : 135|1@1+ (1.000000,0.000000) [0.000000|1.000000] "" ICAS1_Gateway ICAS1_KommunikationsServer
 SG_ MO_Rekuperation_Ges_EM  : 136|15@1+ (10.000000,0.000000) [0.000000|327670.000000] "Unit_WattSecond" ICAS1_Gateway ICAS1_KommunikationsServer
 SG_ MO_Rekuperation_EM_Ges_Ueberlauf  : 151|1@1+ (1.000000,0.000000) [0.000000|1.000000] "" ICAS1_Gateway ICAS1_KommunikationsServer
 SG_ MO_Drehzahl_EM  : 152|13@1+ (8.000000,-32768.000000) [-32768.000000|32744.000000] "Unit_RevPerMinute" ICAS1_Gateway
 SG_ MO_Uebersetzung_EM  : 165|10@1+ (0.031250,0.000000) [0.031250|31.906250] "" ICAS1_Gateway
 SG_ MO_Drehzahl_EM_sek  : 175|13@1+ (8.000000,-32768.000000) [-32768.000000|32744.000000] "Unit_RevPerMinute" ICAS1_Gateway
 SG_ MO_Uebersetzung_EM_sek  : 188|10@1+ (0.031250,0.000000) [0.031250|31.906250] "" ICAS1_Gateway

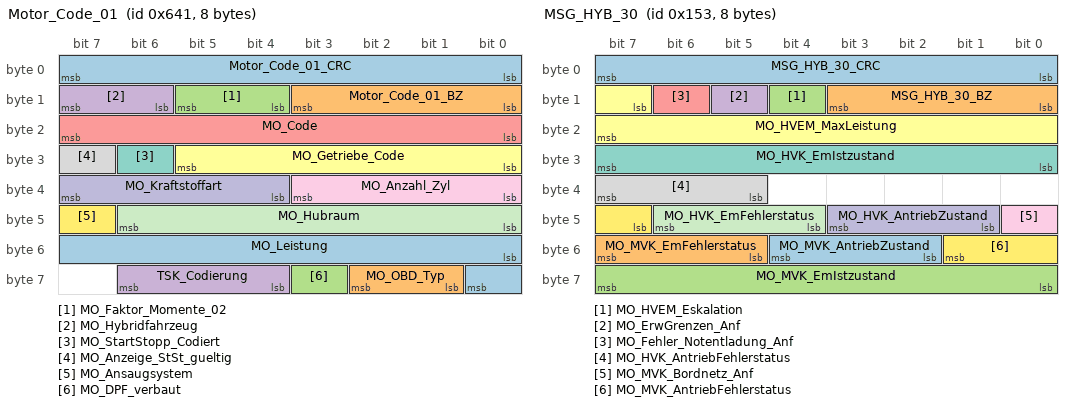
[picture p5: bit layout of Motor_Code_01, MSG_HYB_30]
BO_ 1601 Motor_Code_01: 8 Motor_BEV
 SG_ Motor_Code_01_CRC  : 0|8@1+ (1.000000,0.000000) [0.000000|255.000000] "" ICAS1_Gateway
 SG_ Motor_Code_01_BZ  : 8|4@1+ (1.000000,0.000000) [0.000000|15.000000] "" ICAS1_Gateway
 SG_ MO_Faktor_Momente_02  : 12|2@1+ (1.000000,0.000000) [1.000000|3.000000] "Unit_NewtoMeter" ICAS1_Gateway
 SG_ MO_Hybridfahrzeug  : 14|2@1+ (1.000000,0.000000) [0.000000|3.000000] "" ICAS1_Gateway
 SG_ MO_Code  : 16|8@1+ (1.000000,0.000000) [0.000000|255.000000] "" ICAS1_Gateway
 SG_ MO_Getriebe_Code  : 24|6@1+ (1.000000,0.000000) [0.000000|63.000000] "" ICAS1_Gateway
 SG_ MO_StartStopp_Codiert  : 30|1@1+ (1.000000,0.000000) [0.000000|1.000000] "" ICAS1_Gateway
 SG_ MO_Anzeige_StSt_gueltig  : 31|1@1+ (1.000000,0.000000) [0.000000|1.000000] "" ICAS1_Gateway
 SG_ MO_Anzahl_Zyl  : 32|4@1+ (1.000000,0.000000) [0.000000|15.000000] "" ICAS1_Gateway
 SG_ MO_Kraftstoffart  : 36|4@1+ (1.000000,0.000000) [0.000000|15.000000] "" ICAS1_Gateway ICAS1_KommunikationsServer
 SG_ MO_Hubraum  : 40|7@1+ (0.100000,0.000000) [0.000000|12.700000] "Unit_Liter" ICAS1_Gateway
 SG_ MO_Ansaugsystem  : 47|1@1+ (1.000000,0.000000) [0.000000|1.000000] "" ICAS1_Gateway
 SG_ MO_Leistung  : 48|9@1+ (1.000000,0.000000) [0.000000|511.000000] "Unit_KiloWatt" ICAS1_Gateway
 SG_ MO_OBD_Typ  : 57|2@1+ (1.000000,0.000000) [0.000000|3.000000] "" ICAS1_Gateway
 SG_ MO_DPF_verbaut  : 59|1@1+ (1.000000,0.000000) [0.000000|1.000000] "" ICAS1_Gateway
 SG_ TSK_Codierung  : 60|3@1+ (1.000000,0.000000) [0.000000|7.000000] "" ICAS1_Gateway

BO_ 1155 Motor_Hybrid_06: 8 Motor_BEV
 SG_ Mo_Powermeter_Grenze  : 0|12@1+ (1.000000,0.000000) [0.000000|4092.000000] "" ICAS1_KommunikationsServer
 SG_ MO_Text_Aktivierung_Antrieb  : 12|4@1+ (1.000000,0.000000) [0.000000|15.000000] "" ICAS1_KommunikationsServer
 SG_ MO_Powermeter_Inszenierung_aktiv  : 17|1@1+ (1.000000,0.000000) [0.000000|1.000000] "" Vector__XXX
 SG_ MO_Powermeter_Charge_Grenze  : 18|10@1+ (1.000000,0.000000) [0.000000|1021.000000] "Unit_None" ICAS1_KommunikationsServer
 SG_ MO_Powermeter_Grenze_strategisch  : 28|12@1+ (1.000000,0.000000) [0.000000|4093.000000] "Unit_None" ICAS1_KommunikationsServer
 SG_ MO_Powermeter_untere_E_Grenze  : 40|12@1+ (1.000000,0.000000) [0.000000|4093.000000] "Unit_None" Vector__XXX
 SG_ MO_Powermeter_obere_E_Grenze  : 52|12@1+ (1.000000,0.000000) [0.000000|4093.000000] "Unit_None" Vector__XXX

BO_ 2527679686 MRR_ASM_01: 8 ICAS1_Gateway
 SG_ MRR_HR_ASM_Ereignis  : 0|8@1+ (1.000000,0.000000) [1.000000|254.000000] "" Airbag
 SG_ MRR_HR_ASM_Zeitstempel  : 8|8@1+ (0.080000,0.000000) [0.000000|20.320000] "Unit_Secon" Airbag
 SG_ MRR_HR_ASM_Data_1  : 16|8@1+ (1.000000,0.000000) [0.000000|255.000000] "" Airbag
 SG_ MRR_HR_ASM_Data_2  : 24|8@1+ (1.000000,0.000000) [0.000000|255.000000] "" Airbag
 SG_ MRR_HR_ASM_Data_3  : 32|8@1+ (1.000000,0.000000) [0.000000|255.000000] "" Airbag
 SG_ MRR_HR_ASM_Data_4  : 40|8@1+ (1.000000,0.000000) [0.000000|255.000000] "" Airbag
 SG_ MRR_HR_ASM_Data_5  : 48|8@1+ (1.000000,0.000000) [0.000000|255.000000] "" Airbag
 SG_ MRR_HR_ASM_Data_6  : 56|8@1+ (1.000000,0.000000) [0.000000|255.000000] "" Airbag

BO_ 22 MSG3_WFS_Anfrage: 8 LE2
 SG_ WFS_MSG3_RND  : 0|32@1+ (1.000000,0.000000) [0.000000|4294967295.000000] "" ICAS1_Gateway
 SG_ WFS_MSG3_CRC  : 32|32@1+ (1.000000,0.000000) [0.000000|4294967295.000000] "" ICAS1_Gateway

BO_ 24 MSG4_WFS_Anfrage: 8 LE1
 SG_ WFS_MSG4_RND  : 0|32@1+ (1.000000,0.000000) [0.000000|4294967295.000000] "" ICAS1_Gateway
 SG_ WFS_MSG4_CRC  : 32|32@1+ (1.000000,0.000000) [0.000000|4294967295.000000] "" ICAS1_Gateway

BO_ 339 MSG_HYB_30: 8 Motor_BEV
 SG_ MSG_HYB_30_CRC  : 0|8@1+ (1.000000,0.000000) [0.000000|255.000000] "" Vector__XXX
 SG_ MSG_HYB_30_BZ  : 8|4@1+ (1.000000,0.000000) [0.000000|15.000000] "" Vector__XXX
 SG_ MO_HVEM_Eskalation  : 12|1@1+ (1.000000,0.000000) [0.000000|1.000000] "" ICAS1_Gateway
 SG_ MO_ErwGrenzen_Anf  : 13|1@1+ (1.000000,0.000000) [0.000000|1.000000] "" LE1 LE2
 SG_ MO_Fehler_Notentladung_Anf  : 14|1@1+ (1.000000,0.000000) [0.000000|1.000000] "" Vector__XXX
 SG_ MO_HVEM_MaxLeistung  : 15|9@1+ (50.000000,0.000000) [0.000000|25450.000000] "Unit_Watt" ICAS1_Gateway
 SG_ MO_HVK_EmIstzustand  : 24|8@1+ (1.000000,0.000000) [0.000000|255.000000] "" Vector__XXX
 SG_ MO_HVK_AntriebFehlerstatus  : 37|3@1+ (1.000000,0.000000) [0.000000|7.000000] "" Vector__XXX
 SG_ MO_MVK_Bordnetz_Anf  : 40|1@1+ (1.000000,0.000000) [0.000000|1.000000] "" Vector__XXX
 SG_ MO_HVK_AntriebZustand  : 41|3@1+ (1.000000,0.000000) [0.000000|7.000000] "" Vector__XXX
 SG_ MO_HVK_EmFehlerstatus  : 44|3@1+ (1.000000,0.000000) [0.000000|7.000000] "" Vector__XXX
 SG_ MO_MVK_AntriebFehlerstatus  : 47|3@1+ (1.000000,0.000000) [0.000000|7.000000] "" Vector__XXX
 SG_ MO_MVK_AntriebZustand  : 50|3@1+ (1.000000,0.000000) [0.000000|7.000000] "" Vector__XXX
 SG_ MO_MVK_EmFehlerstatus  : 53|3@1+ (1.000000,0.000000) [0.000000|7.000000] "" Vector__XXX
 SG_ MO_MVK_EmIstzustand  : 56|8@1+ (1.000000,0.000000) [0.000000|255.000000] "" Vector__XXX

BO_ 2600468501 NMH_Airbag_01: 8 Airbag
 SG_ NM_Airbag_01_CBV_AWB  : 12|1@1+ (1.000000,0.000000) [0.000000|1.000000] "" ICAS1_Gateway
 SG_ NM_Airbag_01_CBV_CRI  : 14|1@1+ (1.000000,0.000000) [0.000000|1.000000] "" ICAS1_Gateway
 SG_ NM_Airbag_01_NM_State  : 16|6@1+ (1.000000,0.000000) [0.000000|63.000000] "" LE1 LE2 Motor_BEV Schaltbetaetigung
 SG_ NM_Airbag_01_Car_Wakeup  : 22|1@1+ (1.000000,0.000000) [0.000000|1.000000] "" ICAS1_Gateway
 SG_ NM_Airbag_01_UDS_CC  : 23|1@1+ (1.000000,0.000000) [0.000000|1.000000] "" Vector__XXX
 SG_ NM_Airbag_01_NM_aktiv_KL15  : 24|1@1+ (1.000000,0.000000) [0.000000|1.000000] "" Vector__XXX
 SG_ NM_Airbag_01_NM_aktiv_Diagnose  : 25|1@1+ (1.000000,0.000000) [0.000000|1.000000] "" Vector__XXX
 SG_ NM_Airbag_01_NM_aktiv_Tmin  : 26|1@1+ (1.000000,0.000000) [0.000000|1.000000] "" Vector__XXX
 SG_ NM_Airbag_01_CAB_V10  : 40|24@1+ (1.000000,0.000000) [0.000000|16777215.000000] "" ICAS1_Gateway

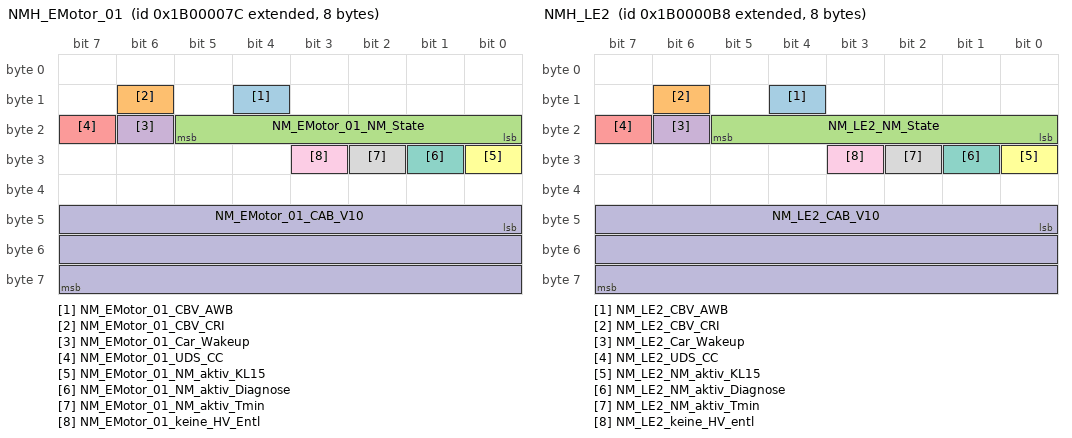
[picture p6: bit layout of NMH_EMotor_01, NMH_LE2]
BO_ 2600468604 NMH_EMotor_01: 8 LE1
 SG_ NM_EMotor_01_CBV_AWB  : 12|1@1+ (1.000000,0.000000) [0.000000|1.000000] "" ICAS1_Gateway
 SG_ NM_EMotor_01_CBV_CRI  : 14|1@1+ (1.000000,0.000000) [0.000000|1.000000] "" ICAS1_Gateway
 SG_ NM_EMotor_01_NM_State  : 16|6@1+ (1.000000,0.000000) [0.000000|63.000000] "" Airbag LE2 Motor_BEV Schaltbetaetigung
 SG_ NM_EMotor_01_Car_Wakeup  : 22|1@1+ (1.000000,0.000000) [0.000000|1.000000] "" ICAS1_Gateway
 SG_ NM_EMotor_01_UDS_CC  : 23|1@1+ (1.000000,0.000000) [0.000000|1.000000] "" Vector__XXX
 SG_ NM_EMotor_01_NM_aktiv_KL15  : 24|1@1+ (1.000000,0.000000) [0.000000|1.000000] "" Vector__XXX
 SG_ NM_EMotor_01_NM_aktiv_Diagnose  : 25|1@1+ (1.000000,0.000000) [0.000000|1.000000] "" Vector__XXX
 SG_ NM_EMotor_01_NM_aktiv_Tmin  : 26|1@1+ (1.000000,0.000000) [0.000000|1.000000] "" Vector__XXX
 SG_ NM_EMotor_01_keine_HV_Entl  : 27|1@1+ (1.000000,0.000000) [0.000000|1.000000] "" Vector__XXX
 SG_ NM_EMotor_01_CAB_V10  : 40|24@1+ (1.000000,0.000000) [0.000000|16777215.000000] "" ICAS1_Gateway

BO_ 2600468496 NMH_Gateway: 8 ICAS1_Gateway
 SG_ NM_Gateway_CBV_AWB  : 12|1@1+ (1.000000,0.000000) [0.000000|1.000000] "" Vector__XXX
 SG_ NM_Gateway_CBV_CRI  : 14|1@1+ (1.000000,0.000000) [0.000000|1.000000] "" Vector__XXX
 SG_ NM_Gateway_NM_State  : 16|6@1+ (1.000000,0.000000) [0.000000|63.000000] "" Airbag LE1 LE2 Motor_BEV Schaltbetaetigung
 SG_ NM_Gateway_Car_Wakeup  : 22|1@1+ (1.000000,0.000000) [0.000000|1.000000] "" Vector__XXX
 SG_ NM_Gateway_UDS_CC  : 23|1@1+ (1.000000,0.000000) [0.000000|1.000000] "" Vector__XXX
 SG_ NM_Gateway_NM_aktiv_KL15  : 24|1@1+ (1.000000,0.000000) [0.000000|1.000000] "" Vector__XXX
 SG_ NM_Gateway_NM_aktiv_Diagnose  : 25|1@1+ (1.000000,0.000000) [0.000000|1.000000] "" Vector__XXX
 SG_ NM_Gateway_NM_aktiv_Tmin  : 26|1@1+ (1.000000,0.000000) [0.000000|1.000000] "" Vector__XXX
 SG_ NM_Gateway_CAB_V10  : 40|24@1+ (1.000000,0.000000) [0.000000|16777215.000000] "" Vector__XXX

BO_ 2600468664 NMH_LE2: 8 LE2
 SG_ NM_LE2_CBV_AWB  : 12|1@1+ (1.000000,0.000000) [0.000000|1.000000] "" ICAS1_Gateway
 SG_ NM_LE2_CBV_CRI  : 14|1@1+ (1.000000,0.000000) [0.000000|1.000000] "" ICAS1_Gateway
 SG_ NM_LE2_NM_State  : 16|6@1+ (1.000000,0.000000) [0.000000|63.000000] "" Airbag LE1 Motor_BEV Schaltbetaetigung
 SG_ NM_LE2_Car_Wakeup  : 22|1@1+ (1.000000,0.000000) [0.000000|1.000000] "" ICAS1_Gateway
 SG_ NM_LE2_UDS_CC  : 23|1@1+ (1.000000,0.000000) [0.000000|1.000000] "" Vector__XXX
 SG_ NM_LE2_NM_aktiv_KL15  : 24|1@1+ (1.000000,0.000000) [0.000000|1.000000] "" Vector__XXX
 SG_ NM_LE2_NM_aktiv_Diagnose  : 25|1@1+ (1.000000,0.000000) [0.000000|1.000000] "" Vector__XXX
 SG_ NM_LE2_NM_aktiv_Tmin  : 26|1@1+ (1.000000,0.000000) [0.000000|1.000000] "" Vector__XXX
 SG_ NM_LE2_keine_HV_entl  : 27|1@1+ (1.000000,0.000000) [0.000000|1.000000] "" Vector__XXX
 SG_ NM_LE2_CAB_V10  : 40|24@1+ (1.000000,0.000000) [0.000000|16777215.000000] "" ICAS1_Gateway

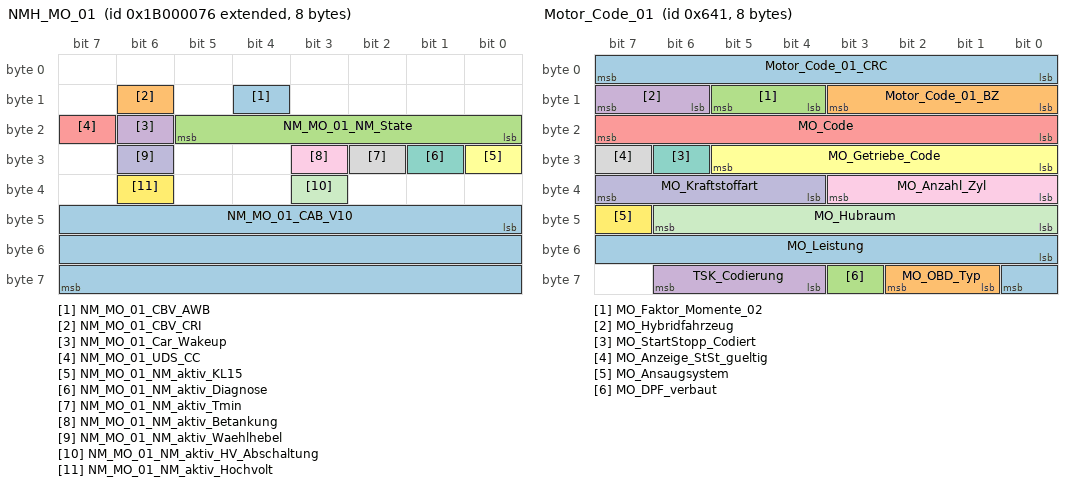
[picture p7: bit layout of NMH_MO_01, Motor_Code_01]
BO_ 2600468598 NMH_MO_01: 8 Motor_BEV
 SG_ NM_MO_01_CBV_AWB  : 12|1@1+ (1.000000,0.000000) [0.000000|1.000000] "" ICAS1_Gateway
 SG_ NM_MO_01_CBV_CRI  : 14|1@1+ (1.000000,0.000000) [0.000000|1.000000] "" ICAS1_Gateway
 SG_ NM_MO_01_NM_State  : 16|6@1+ (1.000000,0.000000) [0.000000|63.000000] "" Airbag LE1 LE2 Schaltbetaetigung
 SG_ NM_MO_01_Car_Wakeup  : 22|1@1+ (1.000000,0.000000) [0.000000|1.000000] "" ICAS1_Gateway
 SG_ NM_MO_01_UDS_CC  : 23|1@1+ (1.000000,0.000000) [0.000000|1.000000] "" Vector__XXX
 SG_ NM_MO_01_NM_aktiv_KL15  : 24|1@1+ (1.000000,0.000000) [0.000000|1.000000] "" Vector__XXX
 SG_ NM_MO_01_NM_aktiv_Diagnose  : 25|1@1+ (1.000000,0.000000) [0.000000|1.000000] "" Vector__XXX
 SG_ NM_MO_01_NM_aktiv_Tmin  : 26|1@1+ (1.000000,0.000000) [0.000000|1.000000] "" Vector__XXX
 SG_ NM_MO_01_NM_aktiv_Betankung  : 27|1@1+ (1.000000,0.000000) [0.000000|1.000000] "" Vector__XXX
 SG_ NM_MO_01_NM_aktiv_Waehlhebel  : 30|1@1+ (1.000000,0.000000) [0.000000|1.000000] "" Vector__XXX
 SG_ NM_MO_01_NM_aktiv_HV_Abschaltung  : 35|1@1+ (1.000000,0.000000) [0.000000|1.000000] "" Vector__XXX
 SG_ NM_MO_01_NM_aktiv_Hochvolt  : 38|1@1+ (1.000000,0.000000) [0.000000|1.000000] "" Vector__XXX
 SG_ NM_MO_01_CAB_V10  : 40|24@1+ (1.000000,0.000000) [0.000000|16777215.000000] "" ICAS1_Gateway

BO_ 2600468733 NMH_Waehlhebel: 8 Schaltbetaetigung
 SG_ NM_Waehlhebel_CBV_AWB  : 12|1@1+ (1.000000,0.000000) [0.000000|1.000000] "" ICAS1_Gateway
 SG_ NM_Waehlhebel_CBV_CRI  : 14|1@1+ (1.000000,0.000000) [0.000000|1.000000] "" ICAS1_Gateway
 SG_ NM_Waehlhebel_NM_State  : 16|6@1+ (1.000000,0.000000) [0.000000|63.000000] "" Airbag LE1 LE2 Motor_BEV
 SG_ NM_Waehlhebel_Car_Wakeup  : 22|1@1+ (1.000000,0.000000) [0.000000|1.000000] "" ICAS1_Gateway
 SG_ NM_Waehlhebel_UDS_CC  : 23|1@1+ (1.000000,0.000000) [0.000000|1.000000] "" Vector__XXX
 SG_ NM_Waehlhebel_NM_aktiv_KL15  : 24|1@1+ (1.000000,0.000000) [0.000000|1.000000] "" Vector__XXX
 SG_ NM_Waehlhebel_NM_aktiv_Diagnose  : 25|1@1+ (1.000000,0.000000) [0.000000|1.000000] "" Vector__XXX
 SG_ NM_Waehlhebel_NM_aktiv_Tmin  : 26|1@1+ (1.000000,0.000000) [0.000000|1.000000] "" Vector__XXX
 SG_ NM_Waehlhebel_CAB_V10  : 40|24@1+ (1.000000,0.000000) [0.000000|16777215.000000] "" ICAS1_Gateway

BO_ 2621440533 OBDC_Airbag_01_Req_FD: 64 ICAS1_Gateway
 SG_ OBDC_Airbag_01_Req_FD_Data  : 0|512@1+ (1.000000,0.000000) [0.000000|13407807929942597099574024998205846127479365820592393377723561443721764030073546976801874298166903427690031858186486050853753882811946569946433649006084096.000000] "" Airbag

BO_ 2621571605 OBDC_Airbag_01_Resp_FD: 64 Airbag
 SG_ OBDC_Airbag_01_Resp_FD_Data  : 0|512@1+ (1.000000,0.000000) [0.000000|13407807929942597099574024998205846127479365820592393377723561443721764030073546976801874298166903427690031858186486050853753882811946569946433649006084096.000000] "" ICAS1_Gateway

BO_ 2621440636 OBDC_EMotor_01_Req_FD: 64 ICAS1_Gateway
 SG_ OBDC_EMotor_01_Req_FD_Data  : 0|512@1+ (1.000000,0.000000) [0.000000|13407807929942597099574024998205846127479365820592393377723561443721764030073546976801874298166903427690031858186486050853753882811946569946433649006084096.000000] "" LE1

BO_ 2621571708 OBDC_EMotor_01_Resp_FD: 64 LE1
 SG_ OBDC_EMotor_01_Resp_FD_Data  : 0|512@1+ (1.000000,0.000000) [0.000000|13407807929942597099574024998205846127479365820592393377723561443721764030073546976801874298166903427690031858186486050853753882811946569946433649006084096.000000] "" ICAS1_Gateway

BO_ 2621440696 OBDC_EMotor_02_Req_FD: 64 ICAS1_Gateway
 SG_ OBDC_EMotor_02_Req_FD_Data  : 0|512@1+ (1.000000,0.000000) [0.000000|13407807929942597099574024998205846127479365820592393377723561443721764030073546976801874298166903427690031858186486050853753882811946569946433649006084096.000000] "" LE2

BO_ 2621571768 OBDC_EMotor_02_Resp_FD: 64 LE2
 SG_ OBDC_EMotor_02_Resp_FD_Data  : 0|512@1+ (1.000000,0.000000) [0.000000|13407807929942597099574024998205846127479365820592393377723561443721764030073546976801874298166903427690031858186486050853753882811946569946433649006084096.000000] "" ICAS1_Gateway

BO_ 2621506048 OBDC_Funktionaler_Req_All_FD: 64 ICAS1_Gateway
 SG_ OBDC_Funktion_Req_All_FD_Data  : 0|512@1+ (1.000000,0.000000) [0.000000|13407807929942597099574024998205846127479365820592393377723561443721764030073546976801874298166903427690031858186486050853753882811946569946433649006084096.000000] "" Airbag LE1 LE2 Motor_BEV

BO_ 2621440630 OBDC_MO_01_Req_FD: 64 ICAS1_Gateway
 SG_ OBDC_MO_01_Req_FD_Data  : 0|512@1+ (1.000000,0.000000) [0.000000|13407807929942597099574024998205846127479365820592393377723561443721764030073546976801874298166903427690031858186486050853753882811946569946433649006084096.000000] "" Motor_BEV

BO_ 2621571702 OBDC_MO_01_Resp_FD: 64 Motor_BEV
 SG_ OBDC_MO_01_Resp_FD_Data  : 0|512@1+ (1.000000,0.000000) [0.000000|13407807929942597099574024998205846127479365820592393377723561443721764030073546976801874298166903427690031858186486050853753882811946569946433649006084096.000000] "" ICAS1_Gateway

BO_ 2564502513 OBDx_allOBD_Req: 8 ICAS1_Gateway
 SG_ OBDx_allOBD_Req_Data  : 0|64@1+ (1.000000,0.000000) [0.000000|18446744073709551616.000000] "" LE1 LE2 Motor_BEV

BO_ 2564425457 OBDx_LE1_Req: 8 ICAS1_Gateway
 SG_ OBDx_LE1_Req_Data  : 0|64@1+ (1.000000,0.000000) [0.000000|18446744073709551616.000000] "" LE1

BO_ 2564485382 OBDx_LE1_Resp: 8 LE1
 SG_ OBDx_LE1_Resp_Data  : 0|64@1+ (1.000000,0.000000) [0.000000|18446744073709551616.000000] "" ICAS1_Gateway

BO_ 2564425713 OBDx_LE2_Req: 8 ICAS1_Gateway
 SG_ OBDx_LE2_Req_Data  : 0|64@1+ (1.000000,0.000000) [0.000000|18446744073709551616.000000] "" LE2

BO_ 2564485383 OBDx_LE2_Resp: 8 LE2
 SG_ OBDx_LE2_Resp_Data  : 0|64@1+ (1.000000,0.000000) [0.000000|18446744073709551616.000000] "" ICAS1_Gateway

BO_ 2564424177 OBDx_MO_01_Req: 8 ICAS1_Gateway
 SG_ OBDx_MO_01_Req_Data  : 0|64@1+ (1.000000,0.000000) [0.000000|18446744073709551616.000000] "" Motor_BEV

BO_ 2564485377 OBDx_MO_01_Resp: 8 Motor_BEV
 SG_ OBDx_MO_01_Resp_Data  : 0|64@1+ (1.000000,0.000000) [0.000000|18446744073709551616.000000] "" ICAS1_Gateway

BO_ 627 OCC_01: 24 ICAS1_Gateway
 SG_ OCC_01_CRC  : 0|8@1+ (1.000000,0.000000) [0.000000|255.000000] "" Vector__XXX
 SG_ OCC_01_BZ  : 8|4@1+ (1.000000,0.000000) [0.000000|15.000000] "" Vector__XXX
 SG_ OCC_Stecker_Status  : 12|2@1+ (1.000000,0.000000) [0.000000|3.000000] "" Vector__XXX
 SG_ OCC_Status_Spgfreiheit  : 14|2@1+ (1.000000,0.000000) [0.000000|3.000000] "" Motor_BEV
 SG_ OCC_DC_IstStrom  : 16|11@1+ (0.100000,0.000000) [0.000000|204.500000] "Unit_Amper" Vector__XXX
 SG_ OCC_CC_Latchstatus_DC_GBT  : 27|3@1+ (1.000000,0.000000) [0.000000|7.000000] "" Vector__XXX
 SG_ OCC_Status_EoHVL  : 30|2@1+ (1.000000,0.000000) [0.000000|3.000000] "" Motor_BEV
 SG_ OCC_I_istAC_Netz_L1  : 32|9@1+ (0.100000,0.000000) [0.000000|50.800000] "Unit_Amper" Vector__XXX
 SG_ OCC_PP_Latchstatus_A  : 41|3@1+ (1.000000,0.000000) [0.000000|7.000000] "" Vector__XXX
 SG_ OCC_PP_Latchstatus_B  : 44|3@1+ (1.000000,0.000000) [0.000000|7.000000] "" Vector__XXX
 SG_ OCC_I_istAC_Netz_L2  : 47|9@1+ (0.100000,0.000000) [0.000000|50.800000] "Unit_Amper" Vector__XXX
 SG_ OCC_I_istAC_Netz_L3  : 56|9@1+ (0.100000,0.000000) [0.000000|50.800000] "Unit_Amper" Vector__XXX
 SG_ OCC_IstModus  : 65|3@1+ (1.000000,0.000000) [0.000000|7.000000] "" Motor_BEV
 SG_ OCC_CP_Status_A  : 68|2@1+ (1.000000,0.000000) [0.000000|3.000000] "" Vector__XXX
 SG_ OCC_CP_Status_B  : 70|2@1+ (1.000000,0.000000) [0.000000|3.000000] "" Vector__XXX
 SG_ OCC_IstSpannung_HV  : 72|10@1+ (1.000000,0.000000) [0.000000|1021.000000] "Unit_Volt" Vector__XXX
 SG_ OCC_PP_Status_A  : 82|2@1+ (1.000000,0.000000) [0.000000|3.000000] "" Vector__XXX
 SG_ OCC_PP_Status_B  : 84|2@1+ (1.000000,0.000000) [0.000000|3.000000] "" Vector__XXX
 SG_ OCC_CC_Status_DC_GBT  : 86|2@1+ (1.000000,0.000000) [0.000000|3.000000] "" Vector__XXX
 SG_ OCC_CC_Fehlerstatus_DC_GBT  : 88|4@1+ (1.000000,0.000000) [0.000000|15.000000] "" Vector__XXX
 SG_ OCC_Temp_Sensor_Fehlerstatus_DC  : 92|4@1+ (1.000000,0.000000) [0.000000|15.000000] "" Vector__XXX
 SG_ OCC_Temp_Sensor_Fehlerstatus_AC  : 96|3@1+ (1.000000,0.000000) [0.000000|7.000000] "" Vector__XXX
 SG_ OCC_Temp_Sensor_Status  : 99|3@1+ (1.000000,0.000000) [0.000000|7.000000] "" Vector__XXX

BU_:  Airbag BAP_Tester ICAS1_Gateway ICAS1_KommunikationsServer LE1 LE2 Motor_BEV Schaltbetaetigung

BO_ 190 Motor_56: 48 Motor_BEV
 SG_ Motor_56_CRC  : 0|8@1+ (1.000000,0.000000) [0.000000|255.000000] "" ICAS1_Gateway LE1 LE2
 SG_ Motor_56_BZ  : 8|4@1+ (1.000000,0.000000) [0.000000|15.000000] "" ICAS1_Gateway LE1 LE2
 SG_ MO_EM1_MinDrehzahl  : 12|14@1+ (2.000000,-10000.000000) [-10000.000000|22764.000000] "Unit_MinutInver" ICAS1_Gateway LE1
 SG_ MO_EM1_MaxDrehzahl  : 26|14@1+ (2.000000,-10000.000000) [-10000.000000|22764.000000] "Unit_MinutInver" ICAS1_Gateway LE1
 SG_ MO_EM1_DynLimit_AR  : 40|8@1+ (1.000000,0.000000) [0.000000|254.000000] "Unit_NewtoMeter" ICAS1_Gateway LE1
 SG_ MO_EM1_Periode_AR  : 48|8@1+ (0.001953,0.000000) [0.000000|0.496094] "Unit_Secon" ICAS1_Gateway LE1
 SG_ MO_EM1_SollMoment  : 56|12@1+ (0.500000,-1023.000000) [-1023.000000|1023.500000] "Unit_NewtoMeter" ICAS1_Gateway LE1
 SG_ MO_EM1_Sollmodus  : 68|4@1+ (1.000000,0.000000) [0.000000|15.000000] "" ICAS1_Gateway LE1
 SG_ MO_EM1_Min_Leistung  : 72|14@1+ (100.000000,-819000.000000) [-819000.000000|819100.000000] "Unit_Watt" ICAS1_Gateway LE1
 SG_ MO_EM1_Max_Leistung  : 86|14@1+ (100.000000,-819000.000000) [-819000.000000|819100.000000] "Unit_Watt" ICAS1_Gateway LE1
 SG_ MO_EM1_Min_Strom_Lim  : 100|13@1+ (0.500000,-2047.000000) [-2047.000000|2047.500000] "Unit_Amper" ICAS1_Gateway LE1
 SG_ MO_EM1_Max_Strom_Lim  : 113|13@1+ (0.500000,-2047.000000) [-2047.000000|2047.500000] "Unit_Amper" ICAS1_Gateway LE1
 SG_ MO_EM1_AR_Anf  : 126|3@1+ (1.000000,0.000000) [0.000000|7.000000] "" ICAS1_Gateway LE1
 SG_ MO_EM1_Kp_AR  : 129|9@1+ (0.003906,0.000000) [0.000000|1.992188] "Unit_NewtoMeterPerRPM" ICAS1_Gateway LE1
 SG_ MO_EM1_SollSpannung  : 138|12@1+ (0.500000,0.000000) [0.000000|2047.000000] "Unit_Volt" ICAS1_Gateway LE1
 SG_ MO_EM2_MinDrehzahl  : 156|14@1+ (2.000000,-10000.000000) [-10000.000000|22764.000000] "Unit_MinutInver" ICAS1_Gateway LE2
 SG_ MO_EM2_MaxDrehzahl  : 170|14@1+ (2.000000,-10000.000000) [-10000.000000|22764.000000] "Unit_MinutInver" ICAS1_Gateway LE2
 SG_ MO_EM2_DynLimit_AR  : 184|8@1+ (1.000000,0.000000) [0.000000|254.000000] "Unit_NewtoMeter" ICAS1_Gateway LE2
 SG_ MO_EM2_Periode_AR  : 192|8@1+ (0.001953,0.000000) [0.000000|0.496094] "Unit_Secon" ICAS1_Gateway LE2
 SG_ MO_EM2_SollMoment  : 200|12@1+ (0.500000,-1023.000000) [-1023.000000|1023.500000] "Unit_NewtoMeter" ICAS1_Gateway LE2
 SG_ MO_EM2_Sollmodus  : 212|4@1+ (1.000000,0.000000) [0.000000|15.000000] "" ICAS1_Gateway LE2
 SG_ MO_EM2_Min_Leistung  : 216|14@1+ (100.000000,-819000.000000) [-819000.000000|819100.000000] "Unit_Watt" ICAS1_Gateway LE2
 SG_ MO_EM2_Max_Leistung  : 230|14@1+ (100.000000,-819000.000000) [-819000.000000|819100.000000] "Unit_Watt" ICAS1_Gateway LE2
 SG_ MO_EM2_Min_Strom_Lim  : 244|13@1+ (0.500000,-2047.000000) [-2047.000000|2047.500000] "Unit_Amper" ICAS1_Gateway LE2
 SG_ MO_EM2_Max_Strom_Lim  : 257|13@1+ (0.500000,-2047.000000) [-2047.000000|2047.500000] "Unit_Amper" ICAS1_Gateway LE2
 SG_ MO_EM2_AR_Anf  : 270|3@1+ (1.000000,0.000000) [0.000000|7.000000] "" ICAS1_Gateway LE2
 SG_ MO_EM2_SollSpannung  : 282|12@1+ (0.500000,0.000000) [0.000000|2047.000000] "Unit_Volt" ICAS1_Gateway LE2
 SG_ MO_DC_Max_Strom_HV  : 296|8@1+ (0.200000,0.000000) [0.000000|50.800000] "Unit_Amper" ICAS1_Gateway
 SG_ MO_DC_SollSpannung_HV  : 304|8@1+ (2.000000,0.000000) [0.000000|508.000000] "Unit_Volt" ICAS1_Gateway
 SG_ MO_EM1_Max_Moment  : 312|12@1+ (0.500000,-1023.000000) [-1023.000000|1023.500000] "Unit_NewtoMeter" ICAS1_Gateway LE1
 SG_ MO_EM1_Min_Moment  : 324|12@1+ (0.500000,-1023.000000) [-1023.000000|1023.500000] "Unit_NewtoMeter" ICAS1_Gateway LE1
 SG_ MO_EM2_Max_Moment  : 336|12@1+ (0.500000,-1023.000000) [-1023.000000|1023.500000] "Unit_NewtoMeter" ICAS1_Gateway LE2
 SG_ MO_EM2_Min_Moment  : 348|12@1+ (0.500000,-1023.000000) [-1023.000000|1023.500000] "Unit_NewtoMeter" ICAS1_Gateway LE2

BO_ 2463978666 Motor_57: 32 Motor_BEV
 SG_ MO_EM1_Min_Spannung_Lim  : 12|10@1+ (1.000000,0.000000) [0.000000|1021.000000] "Unit_Volt" ICAS1_Gateway LE1
 SG_ MO_EM1_Max_Spannung_Lim  : 22|10@1+ (1.000000,0.000000) [0.000000|1021.000000] "Unit_Volt" ICAS1_Gateway LE1
 SG_ MO_EM1_Min_Leistung_Gesamt  : 32|13@1+ (200.000000,-819000.000000) [-819000.000000|818800.000000] "Unit_Watt" ICAS1_Gateway LE1
 SG_ MO_EM1_Max_Leistung_Gesamt  : 45|13@1+ (200.000000,-819000.000000) [-819000.000000|818800.000000] "Unit_Watt" ICAS1_Gateway LE1
 SG_ MO_EM2_Min_Leistung_Gesamt  : 58|13@1+ (200.000000,-819000.000000) [-819000.000000|818800.000000] "Unit_Watt" ICAS1_Gateway LE2
 SG_ MO_EM2_Max_Leistung_Gesamt  : 71|13@1+ (200.000000,-819000.000000) [-819000.000000|818800.000000] "Unit_Watt" ICAS1_Gateway LE2
 SG_ MO_EM2_Min_Spannung_Lim  : 84|10@1+ (1.000000,0.000000) [0.000000|1021.000000] "Unit_Volt" ICAS1_Gateway LE2
 SG_ MO_EM2_Max_Spannung_Lim  : 94|10@1+ (1.000000,0.000000) [0.000000|1021.000000] "Unit_Volt" ICAS1_Gateway LE2
 SG_ MO_EM1_Generator_Leistung  : 104|8@1+ (100.000000,0.000000) [0.000000|25300.000000] "Unit_Watt" ICAS1_Gateway LE1
 SG_ MO_Verbrauch_EM_Ges  : 120|15@1+ (10.000000,0.000000) [0.000000|327670.000000] "Unit_WattSecond" ICAS1_Gateway ICAS1_KommunikationsServer
 SG_ MO_Verbrauch_EM_Ges_Ueberlauf  : 135|1@1+ (1.000000,0.000000) [0.000000|1.000000] "" ICAS1_Gateway ICAS1_KommunikationsServer
 SG_ MO_Rekuperation_Ges_EM  : 136|15@1+ (10.000000,0.000000) [0.000000|327670.000000] "Unit_WattSecond" ICAS1_Gateway ICAS1_KommunikationsServer
 SG_ MO_Rekuperation_EM_Ges_Ueberlauf  : 151|1@1+ (1.000000,0.000000) [0.000000|1.000000] "" ICAS1_Gateway ICAS1_KommunikationsServer
 SG_ MO_Drehzahl_EM  : 152|13@1+ (8.000000,-32768.000000) [-32768.000000|32744.000000] "Unit_RevPerMinute" ICAS1_Gateway
 SG_ MO_Uebersetzung_EM  : 165|10@1+ (0.031250,0.000000) [0.031250|31.906250] "" ICAS1_Gateway
 SG_ MO_Drehzahl_EM_sek  : 175|13@1+ (8.000000,-32768.000000) [-32768.000000|32744.000000] "Unit_RevPerMinute" ICAS1_Gateway
 SG_ MO_Uebersetzung_EM_sek  : 188|10@1+ (0.031250,0.000000) [0.031250|31.906250] "" ICAS1_Gateway

BO_ 1601 Motor_Code_01: 8 Motor_BEV
 SG_ Motor_Code_01_CRC  : 0|8@1+ (1.000000,0.000000) [0.000000|255.000000] "" ICAS1_Gateway
 SG_ Motor_Code_01_BZ  : 8|4@1+ (1.000000,0.000000) [0.000000|15.000000] "" ICAS1_Gateway
 SG_ MO_Faktor_Momente_02  : 12|2@1+ (1.000000,0.000000) [1.000000|3.000000] "Unit_NewtoMeter" ICAS1_Gateway
 SG_ MO_Hybridfahrzeug  : 14|2@1+ (1.000000,0.000000) [0.000000|3.000000] "" ICAS1_Gateway
 SG_ MO_Code  : 16|8@1+ (1.000000,0.000000) [0.000000|255.000000] "" ICAS1_Gateway
 SG_ MO_Getriebe_Code  : 24|6@1+ (1.000000,0.000000) [0.000000|63.000000] "" ICAS1_Gateway
 SG_ MO_StartStopp_Codiert  : 30|1@1+ (1.000000,0.000000) [0.000000|1.000000] "" ICAS1_Gateway
 SG_ MO_Anzeige_StSt_gueltig  : 31|1@1+ (1.000000,0.000000) [0.000000|1.000000] "" ICAS1_Gateway
 SG_ MO_Anzahl_Zyl  : 32|4@1+ (1.000000,0.000000) [0.000000|15.000000] "" ICAS1_Gateway
 SG_ MO_Kraftstoffart  : 36|4@1+ (1.000000,0.000000) [0.000000|15.000000] "" ICAS1_Gateway ICAS1_KommunikationsServer
 SG_ MO_Hubraum  : 40|7@1+ (0.100000,0.000000) [0.000000|12.700000] "Unit_Liter" ICAS1_Gateway
 SG_ MO_Ansaugsystem  : 47|1@1+ (1.000000,0.000000) [0.000000|1.000000] "" ICAS1_Gateway
 SG_ MO_Leistung  : 48|9@1+ (1.000000,0.000000) [0.000000|511.000000] "Unit_KiloWatt" ICAS1_Gateway
 SG_ MO_OBD_Typ  : 57|2@1+ (1.000000,0.000000) [0.000000|3.000000] "" ICAS1_Gateway
 SG_ MO_DPF_verbaut  : 59|1@1+ (1.000000,0.000000) [0.000000|1.000000] "" ICAS1_Gateway
 SG_ TSK_Codierung  : 60|3@1+ (1.000000,0.000000) [0.000000|7.000000] "" ICAS1_Gateway

BO_ 1155 Motor_Hybrid_06: 8 Motor_BEV
 SG_ Mo_Powermeter_Grenze  : 0|12@1+ (1.000000,0.000000) [0.000000|4092.000000] "" ICAS1_KommunikationsServer
 SG_ MO_Text_Aktivierung_Antrieb  : 12|4@1+ (1.000000,0.000000) [0.000000|15.000000] "" ICAS1_KommunikationsServer
 SG_ MO_Powermeter_Inszenierung_aktiv  : 17|1@1+ (1.000000,0.000000) [0.000000|1.000000] "" Vector__XXX
 SG_ MO_Powermeter_Charge_Grenze  : 18|10@1+ (1.000000,0.000000) [0.000000|1021.000000] "Unit_None" ICAS1_KommunikationsServer
 SG_ MO_Powermeter_Grenze_strategisch  : 28|12@1+ (1.000000,0.000000) [0.000000|4093.000000] "Unit_None" ICAS1_KommunikationsServer
 SG_ MO_Powermeter_untere_E_Grenze  : 40|12@1+ (1.000000,0.000000) [0.000000|4093.000000] "Unit_None" Vector__XXX
 SG_ MO_Powermeter_obere_E_Grenze  : 52|12@1+ (1.000000,0.000000) [0.000000|4093.000000] "Unit_None" Vector__XXX

BO_ 2527679686 MRR_ASM_01: 8 ICAS1_Gateway
 SG_ MRR_HR_ASM_Ereignis  : 0|8@1+ (1.000000,0.000000) [1.000000|254.000000] "" Airbag
 SG_ MRR_HR_ASM_Zeitstempel  : 8|8@1+ (0.080000,0.000000) [0.000000|20.320000] "Unit_Secon" Airbag
 SG_ MRR_HR_ASM_Data_1  : 16|8@1+ (1.000000,0.000000) [0.000000|255.000000] "" Airbag
 SG_ MRR_HR_ASM_Data_2  : 24|8@1+ (1.000000,0.000000) [0.000000|255.000000] "" Airbag
 SG_ MRR_HR_ASM_Data_3  : 32|8@1+ (1.000000,0.000000) [0.000000|255.000000] "" Airbag
 SG_ MRR_HR_ASM_Data_4  : 40|8@1+ (1.000000,0.000000) [0.000000|255.000000] "" Airbag
 SG_ MRR_HR_ASM_Data_5  : 48|8@1+ (1.000000,0.000000) [0.000000|255.000000] "" Airbag
 SG_ MRR_HR_ASM_Data_6  : 56|8@1+ (1.000000,0.000000) [0.000000|255.000000] "" Airbag

BO_ 22 MSG3_WFS_Anfrage: 8 LE2
 SG_ WFS_MSG3_RND  : 0|32@1+ (1.000000,0.000000) [0.000000|4294967295.000000] "" ICAS1_Gateway
 SG_ WFS_MSG3_CRC  : 32|32@1+ (1.000000,0.000000) [0.000000|4294967295.000000] "" ICAS1_Gateway

BO_ 24 MSG4_WFS_Anfrage: 8 LE1
 SG_ WFS_MSG4_RND  : 0|32@1+ (1.000000,0.000000) [0.000000|4294967295.000000] "" ICAS1_Gateway
 SG_ WFS_MSG4_CRC  : 32|32@1+ (1.000000,0.000000) [0.000000|4294967295.000000] "" ICAS1_Gateway

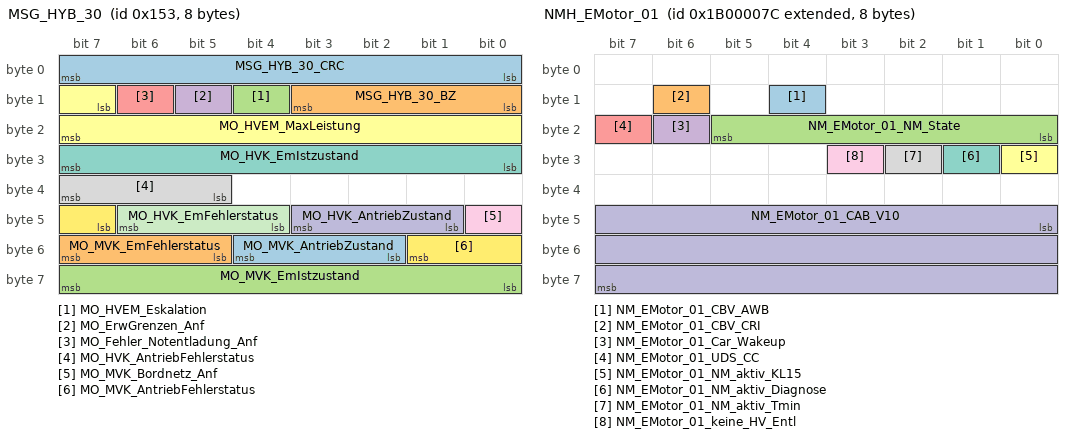
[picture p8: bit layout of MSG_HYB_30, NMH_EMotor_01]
BO_ 339 MSG_HYB_30: 8 Motor_BEV
 SG_ MSG_HYB_30_CRC  : 0|8@1+ (1.000000,0.000000) [0.000000|255.000000] "" Vector__XXX
 SG_ MSG_HYB_30_BZ  : 8|4@1+ (1.000000,0.000000) [0.000000|15.000000] "" Vector__XXX
 SG_ MO_HVEM_Eskalation  : 12|1@1+ (1.000000,0.000000) [0.000000|1.000000] "" ICAS1_Gateway
 SG_ MO_ErwGrenzen_Anf  : 13|1@1+ (1.000000,0.000000) [0.000000|1.000000] "" LE1 LE2
 SG_ MO_Fehler_Notentladung_Anf  : 14|1@1+ (1.000000,0.000000) [0.000000|1.000000] "" Vector__XXX
 SG_ MO_HVEM_MaxLeistung  : 15|9@1+ (50.000000,0.000000) [0.000000|25450.000000] "Unit_Watt" ICAS1_Gateway
 SG_ MO_HVK_EmIstzustand  : 24|8@1+ (1.000000,0.000000) [0.000000|255.000000] "" Vector__XXX
 SG_ MO_HVK_AntriebFehlerstatus  : 37|3@1+ (1.000000,0.000000) [0.000000|7.000000] "" Vector__XXX
 SG_ MO_MVK_Bordnetz_Anf  : 40|1@1+ (1.000000,0.000000) [0.000000|1.000000] "" Vector__XXX
 SG_ MO_HVK_AntriebZustand  : 41|3@1+ (1.000000,0.000000) [0.000000|7.000000] "" Vector__XXX
 SG_ MO_HVK_EmFehlerstatus  : 44|3@1+ (1.000000,0.000000) [0.000000|7.000000] "" Vector__XXX
 SG_ MO_MVK_AntriebFehlerstatus  : 47|3@1+ (1.000000,0.000000) [0.000000|7.000000] "" Vector__XXX
 SG_ MO_MVK_AntriebZustand  : 50|3@1+ (1.000000,0.000000) [0.000000|7.000000] "" Vector__XXX
 SG_ MO_MVK_EmFehlerstatus  : 53|3@1+ (1.000000,0.000000) [0.000000|7.000000] "" Vector__XXX
 SG_ MO_MVK_EmIstzustand  : 56|8@1+ (1.000000,0.000000) [0.000000|255.000000] "" Vector__XXX

BO_ 2600468501 NMH_Airbag_01: 8 Airbag
 SG_ NM_Airbag_01_CBV_AWB  : 12|1@1+ (1.000000,0.000000) [0.000000|1.000000] "" ICAS1_Gateway
 SG_ NM_Airbag_01_CBV_CRI  : 14|1@1+ (1.000000,0.000000) [0.000000|1.000000] "" ICAS1_Gateway
 SG_ NM_Airbag_01_NM_State  : 16|6@1+ (1.000000,0.000000) [0.000000|63.000000] "" LE1 LE2 Motor_BEV Schaltbetaetigung
 SG_ NM_Airbag_01_Car_Wakeup  : 22|1@1+ (1.000000,0.000000) [0.000000|1.000000] "" ICAS1_Gateway
 SG_ NM_Airbag_01_UDS_CC  : 23|1@1+ (1.000000,0.000000) [0.000000|1.000000] "" Vector__XXX
 SG_ NM_Airbag_01_NM_aktiv_KL15  : 24|1@1+ (1.000000,0.000000) [0.000000|1.000000] "" Vector__XXX
 SG_ NM_Airbag_01_NM_aktiv_Diagnose  : 25|1@1+ (1.000000,0.000000) [0.000000|1.000000] "" Vector__XXX
 SG_ NM_Airbag_01_NM_aktiv_Tmin  : 26|1@1+ (1.000000,0.000000) [0.000000|1.000000] "" Vector__XXX
 SG_ NM_Airbag_01_CAB_V10  : 40|24@1+ (1.000000,0.000000) [0.000000|16777215.000000] "" ICAS1_Gateway

BO_ 2600468604 NMH_EMotor_01: 8 LE1
 SG_ NM_EMotor_01_CBV_AWB  : 12|1@1+ (1.000000,0.000000) [0.000000|1.000000] "" ICAS1_Gateway
 SG_ NM_EMotor_01_CBV_CRI  : 14|1@1+ (1.000000,0.000000) [0.000000|1.000000] "" ICAS1_Gateway
 SG_ NM_EMotor_01_NM_State  : 16|6@1+ (1.000000,0.000000) [0.000000|63.000000] "" Airbag LE2 Motor_BEV Schaltbetaetigung
 SG_ NM_EMotor_01_Car_Wakeup  : 22|1@1+ (1.000000,0.000000) [0.000000|1.000000] "" ICAS1_Gateway
 SG_ NM_EMotor_01_UDS_CC  : 23|1@1+ (1.000000,0.000000) [0.000000|1.000000] "" Vector__XXX
 SG_ NM_EMotor_01_NM_aktiv_KL15  : 24|1@1+ (1.000000,0.000000) [0.000000|1.000000] "" Vector__XXX
 SG_ NM_EMotor_01_NM_aktiv_Diagnose  : 25|1@1+ (1.000000,0.000000) [0.000000|1.000000] "" Vector__XXX
 SG_ NM_EMotor_01_NM_aktiv_Tmin  : 26|1@1+ (1.000000,0.000000) [0.000000|1.000000] "" Vector__XXX
 SG_ NM_EMotor_01_keine_HV_Entl  : 27|1@1+ (1.000000,0.000000) [0.000000|1.000000] "" Vector__XXX
 SG_ NM_EMotor_01_CAB_V10  : 40|24@1+ (1.000000,0.000000) [0.000000|16777215.000000] "" ICAS1_Gateway

BO_ 2600468496 NMH_Gateway: 8 ICAS1_Gateway
 SG_ NM_Gateway_CBV_AWB  : 12|1@1+ (1.000000,0.000000) [0.000000|1.000000] "" Vector__XXX
 SG_ NM_Gateway_CBV_CRI  : 14|1@1+ (1.000000,0.000000) [0.000000|1.000000] "" Vector__XXX
 SG_ NM_Gateway_NM_State  : 16|6@1+ (1.000000,0.000000) [0.000000|63.000000] "" Airbag LE1 LE2 Motor_BEV Schaltbetaetigung
 SG_ NM_Gateway_Car_Wakeup  : 22|1@1+ (1.000000,0.000000) [0.000000|1.000000] "" Vector__XXX
 SG_ NM_Gateway_UDS_CC  : 23|1@1+ (1.000000,0.000000) [0.000000|1.000000] "" Vector__XXX
 SG_ NM_Gateway_NM_aktiv_KL15  : 24|1@1+ (1.000000,0.000000) [0.000000|1.000000] "" Vector__XXX
 SG_ NM_Gateway_NM_aktiv_Diagnose  : 25|1@1+ (1.000000,0.000000) [0.000000|1.000000] "" Vector__XXX
 SG_ NM_Gateway_NM_aktiv_Tmin  : 26|1@1+ (1.000000,0.000000) [0.000000|1.000000] "" Vector__XXX
 SG_ NM_Gateway_CAB_V10  : 40|24@1+ (1.000000,0.000000) [0.000000|16777215.000000] "" Vector__XXX

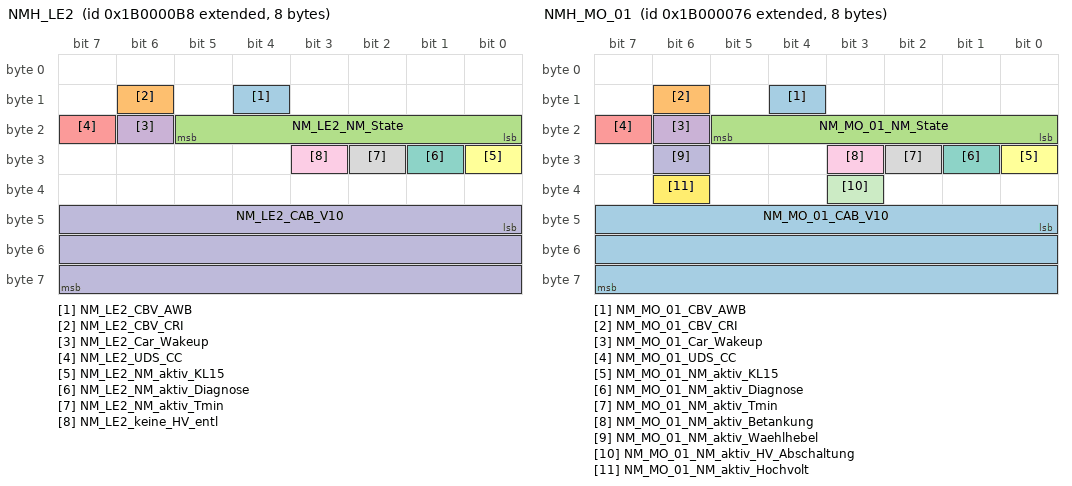
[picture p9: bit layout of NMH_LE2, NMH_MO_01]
BO_ 2600468664 NMH_LE2: 8 LE2
 SG_ NM_LE2_CBV_AWB  : 12|1@1+ (1.000000,0.000000) [0.000000|1.000000] "" ICAS1_Gateway
 SG_ NM_LE2_CBV_CRI  : 14|1@1+ (1.000000,0.000000) [0.000000|1.000000] "" ICAS1_Gateway
 SG_ NM_LE2_NM_State  : 16|6@1+ (1.000000,0.000000) [0.000000|63.000000] "" Airbag LE1 Motor_BEV Schaltbetaetigung
 SG_ NM_LE2_Car_Wakeup  : 22|1@1+ (1.000000,0.000000) [0.000000|1.000000] "" ICAS1_Gateway
 SG_ NM_LE2_UDS_CC  : 23|1@1+ (1.000000,0.000000) [0.000000|1.000000] "" Vector__XXX
 SG_ NM_LE2_NM_aktiv_KL15  : 24|1@1+ (1.000000,0.000000) [0.000000|1.000000] "" Vector__XXX
 SG_ NM_LE2_NM_aktiv_Diagnose  : 25|1@1+ (1.000000,0.000000) [0.000000|1.000000] "" Vector__XXX
 SG_ NM_LE2_NM_aktiv_Tmin  : 26|1@1+ (1.000000,0.000000) [0.000000|1.000000] "" Vector__XXX
 SG_ NM_LE2_keine_HV_entl  : 27|1@1+ (1.000000,0.000000) [0.000000|1.000000] "" Vector__XXX
 SG_ NM_LE2_CAB_V10  : 40|24@1+ (1.000000,0.000000) [0.000000|16777215.000000] "" ICAS1_Gateway

BO_ 2600468598 NMH_MO_01: 8 Motor_BEV
 SG_ NM_MO_01_CBV_AWB  : 12|1@1+ (1.000000,0.000000) [0.000000|1.000000] "" ICAS1_Gateway
 SG_ NM_MO_01_CBV_CRI  : 14|1@1+ (1.000000,0.000000) [0.000000|1.000000] "" ICAS1_Gateway
 SG_ NM_MO_01_NM_State  : 16|6@1+ (1.000000,0.000000) [0.000000|63.000000] "" Airbag LE1 LE2 Schaltbetaetigung
 SG_ NM_MO_01_Car_Wakeup  : 22|1@1+ (1.000000,0.000000) [0.000000|1.000000] "" ICAS1_Gateway
 SG_ NM_MO_01_UDS_CC  : 23|1@1+ (1.000000,0.000000) [0.000000|1.000000] "" Vector__XXX
 SG_ NM_MO_01_NM_aktiv_KL15  : 24|1@1+ (1.000000,0.000000) [0.000000|1.000000] "" Vector__XXX
 SG_ NM_MO_01_NM_aktiv_Diagnose  : 25|1@1+ (1.000000,0.000000) [0.000000|1.000000] "" Vector__XXX
 SG_ NM_MO_01_NM_aktiv_Tmin  : 26|1@1+ (1.000000,0.000000) [0.000000|1.000000] "" Vector__XXX
 SG_ NM_MO_01_NM_aktiv_Betankung  : 27|1@1+ (1.000000,0.000000) [0.000000|1.000000] "" Vector__XXX
 SG_ NM_MO_01_NM_aktiv_Waehlhebel  : 30|1@1+ (1.000000,0.000000) [0.000000|1.000000] "" Vector__XXX
 SG_ NM_MO_01_NM_aktiv_HV_Abschaltung  : 35|1@1+ (1.000000,0.000000) [0.000000|1.000000] "" Vector__XXX
 SG_ NM_MO_01_NM_aktiv_Hochvolt  : 38|1@1+ (1.000000,0.000000) [0.000000|1.000000] "" Vector__XXX
 SG_ NM_MO_01_CAB_V10  : 40|24@1+ (1.000000,0.000000) [0.000000|16777215.000000] "" ICAS1_Gateway

BO_ 2600468733 NMH_Waehlhebel: 8 Schaltbetaetigung
 SG_ NM_Waehlhebel_CBV_AWB  : 12|1@1+ (1.000000,0.000000) [0.000000|1.000000] "" ICAS1_Gateway
 SG_ NM_Waehlhebel_CBV_CRI  : 14|1@1+ (1.000000,0.000000) [0.000000|1.000000] "" ICAS1_Gateway
 SG_ NM_Waehlhebel_NM_State  : 16|6@1+ (1.000000,0.000000) [0.000000|63.000000] "" Airbag LE1 LE2 Motor_BEV
 SG_ NM_Waehlhebel_Car_Wakeup  : 22|1@1+ (1.000000,0.000000) [0.000000|1.000000] "" ICAS1_Gateway
 SG_ NM_Waehlhebel_UDS_CC  : 23|1@1+ (1.000000,0.000000) [0.000000|1.000000] "" Vector__XXX
 SG_ NM_Waehlhebel_NM_aktiv_KL15  : 24|1@1+ (1.000000,0.000000) [0.000000|1.000000] "" Vector__XXX
 SG_ NM_Waehlhebel_NM_aktiv_Diagnose  : 25|1@1+ (1.000000,0.000000) [0.000000|1.000000] "" Vector__XXX
 SG_ NM_Waehlhebel_NM_aktiv_Tmin  : 26|1@1+ (1.000000,0.000000) [0.000000|1.000000] "" Vector__XXX
 SG_ NM_Waehlhebel_CAB_V10  : 40|24@1+ (1.000000,0.000000) [0.000000|16777215.000000] "" ICAS1_Gateway

BO_ 2621440533 OBDC_Airbag_01_Req_FD: 64 ICAS1_Gateway
 SG_ OBDC_Airbag_01_Req_FD_Data  : 0|512@1+ (1.000000,0.000000) [0.000000|13407807929942597099574024998205846127479365820592393377723561443721764030073546976801874298166903427690031858186486050853753882811946569946433649006084096.000000] "" Airbag

BO_ 2621571605 OBDC_Airbag_01_Resp_FD: 64 Airbag
 SG_ OBDC_Airbag_01_Resp_FD_Data  : 0|512@1+ (1.000000,0.000000) [0.000000|13407807929942597099574024998205846127479365820592393377723561443721764030073546976801874298166903427690031858186486050853753882811946569946433649006084096.000000] "" ICAS1_Gateway

BO_ 2621440636 OBDC_EMotor_01_Req_FD: 64 ICAS1_Gateway
 SG_ OBDC_EMotor_01_Req_FD_Data  : 0|512@1+ (1.000000,0.000000) [0.000000|13407807929942597099574024998205846127479365820592393377723561443721764030073546976801874298166903427690031858186486050853753882811946569946433649006084096.000000] "" LE1

BO_ 2621571708 OBDC_EMotor_01_Resp_FD: 64 LE1
 SG_ OBDC_EMotor_01_Resp_FD_Data  : 0|512@1+ (1.000000,0.000000) [0.000000|13407807929942597099574024998205846127479365820592393377723561443721764030073546976801874298166903427690031858186486050853753882811946569946433649006084096.000000] "" ICAS1_Gateway

BO_ 2621440696 OBDC_EMotor_02_Req_FD: 64 ICAS1_Gateway
 SG_ OBDC_EMotor_02_Req_FD_Data  : 0|512@1+ (1.000000,0.000000) [0.000000|13407807929942597099574024998205846127479365820592393377723561443721764030073546976801874298166903427690031858186486050853753882811946569946433649006084096.000000] "" LE2

BO_ 2621571768 OBDC_EMotor_02_Resp_FD: 64 LE2
 SG_ OBDC_EMotor_02_Resp_FD_Data  : 0|512@1+ (1.000000,0.000000) [0.000000|13407807929942597099574024998205846127479365820592393377723561443721764030073546976801874298166903427690031858186486050853753882811946569946433649006084096.000000] "" ICAS1_Gateway

BO_ 2621506048 OBDC_Funktionaler_Req_All_FD: 64 ICAS1_Gateway
 SG_ OBDC_Funktion_Req_All_FD_Data  : 0|512@1+ (1.000000,0.000000) [0.000000|13407807929942597099574024998205846127479365820592393377723561443721764030073546976801874298166903427690031858186486050853753882811946569946433649006084096.000000] "" Airbag LE1 LE2 Motor_BEV

BO_ 2621440630 OBDC_MO_01_Req_FD: 64 ICAS1_Gateway
 SG_ OBDC_MO_01_Req_FD_Data  : 0|512@1+ (1.000000,0.000000) [0.000000|13407807929942597099574024998205846127479365820592393377723561443721764030073546976801874298166903427690031858186486050853753882811946569946433649006084096.000000] "" Motor_BEV

BO_ 2621571702 OBDC_MO_01_Resp_FD: 64 Motor_BEV
 SG_ OBDC_MO_01_Resp_FD_Data  : 0|512@1+ (1.000000,0.000000) [0.000000|13407807929942597099574024998205846127479365820592393377723561443721764030073546976801874298166903427690031858186486050853753882811946569946433649006084096.000000] "" ICAS1_Gateway

BO_ 2564502513 OBDx_allOBD_Req: 8 ICAS1_Gateway
 SG_ OBDx_allOBD_Req_Data  : 0|64@1+ (1.000000,0.000000) [0.000000|18446744073709551616.000000] "" LE1 LE2 Motor_BEV

BO_ 2564425457 OBDx_LE1_Req: 8 ICAS1_Gateway
 SG_ OBDx_LE1_Req_Data  : 0|64@1+ (1.000000,0.000000) [0.000000|18446744073709551616.000000] "" LE1

BO_ 2564485382 OBDx_LE1_Resp: 8 LE1
 SG_ OBDx_LE1_Resp_Data  : 0|64@1+ (1.000000,0.000000) [0.000000|18446744073709551616.000000] "" ICAS1_Gateway

BO_ 2564425713 OBDx_LE2_Req: 8 ICAS1_Gateway
 SG_ OBDx_LE2_Req_Data  : 0|64@1+ (1.000000,0.000000) [0.000000|18446744073709551616.000000] "" LE2

BO_ 2564485383 OBDx_LE2_Resp: 8 LE2
 SG_ OBDx_LE2_Resp_Data  : 0|64@1+ (1.000000,0.000000) [0.000000|18446744073709551616.000000] "" ICAS1_Gateway

BO_ 2564424177 OBDx_MO_01_Req: 8 ICAS1_Gateway
 SG_ OBDx_MO_01_Req_Data  : 0|64@1+ (1.000000,0.000000) [0.000000|18446744073709551616.000000] "" Motor_BEV

BO_ 2564485377 OBDx_MO_01_Resp: 8 Motor_BEV
 SG_ OBDx_MO_01_Resp_Data  : 0|64@1+ (1.000000,0.000000) [0.000000|18446744073709551616.000000] "" ICAS1_Gateway

BO_ 627 OCC_01: 24 ICAS1_Gateway
 SG_ OCC_01_CRC  : 0|8@1+ (1.000000,0.000000) [0.000000|255.000000] "" Vector__XXX
 SG_ OCC_01_BZ  : 8|4@1+ (1.000000,0.000000) [0.000000|15.000000] "" Vector__XXX
 SG_ OCC_Stecker_Status  : 12|2@1+ (1.000000,0.000000) [0.000000|3.000000] "" Vector__XXX
 SG_ OCC_Status_Spgfreiheit  : 14|2@1+ (1.000000,0.000000) [0.000000|3.000000] "" Motor_BEV
 SG_ OCC_DC_IstStrom  : 16|11@1+ (0.100000,0.000000) [0.000000|204.500000] "Unit_Amper" Vector__XXX
 SG_ OCC_CC_Latchstatus_DC_GBT  : 27|3@1+ (1.000000,0.000000) [0.000000|7.000000] "" Vector__XXX
 SG_ OCC_Status_EoHVL  : 30|2@1+ (1.000000,0.000000) [0.000000|3.000000] "" Motor_BEV
 SG_ OCC_I_istAC_Netz_L1  : 32|9@1+ (0.100000,0.000000) [0.000000|50.800000] "Unit_Amper" Vector__XXX
 SG_ OCC_PP_Latchstatus_A  : 41|3@1+ (1.000000,0.000000) [0.000000|7.000000] "" Vector__XXX
 SG_ OCC_PP_Latchstatus_B  : 44|3@1+ (1.000000,0.000000) [0.000000|7.000000] "" Vector__XXX
 SG_ OCC_I_istAC_Netz_L2  : 47|9@1+ (0.100000,0.000000) [0.000000|50.800000] "Unit_Amper" Vector__XXX
 SG_ OCC_I_istAC_Netz_L3  : 56|9@1+ (0.100000,0.000000) [0.000000|50.800000] "Unit_Amper" Vector__XXX
 SG_ OCC_IstModus  : 65|3@1+ (1.000000,0.000000) [0.000000|7.000000] "" Motor_BEV
 SG_ OCC_CP_Status_A  : 68|2@1+ (1.000000,0.000000) [0.000000|3.000000] "" Vector__XXX
 SG_ OCC_CP_Status_B  : 70|2@1+ (1.000000,0.000000) [0.000000|3.000000] "" Vector__XXX
 SG_ OCC_IstSpannung_HV  : 72|10@1+ (1.000000,0.000000) [0.000000|1021.000000] "Unit_Volt" Vector__XXX
 SG_ OCC_PP_Status_A  : 82|2@1+ (1.000000,0.000000) [0.000000|3.000000] "" Vector__XXX
 SG_ OCC_PP_Status_B  : 84|2@1+ (1.000000,0.000000) [0.000000|3.000000] "" Vector__XXX
 SG_ OCC_CC_Status_DC_GBT  : 86|2@1+ (1.000000,0.000000) [0.000000|3.000000] "" Vector__XXX
 SG_ OCC_CC_Fehlerstatus_DC_GBT  : 88|4@1+ (1.000000,0.000000) [0.000000|15.000000] "" Vector__XXX
 SG_ OCC_Temp_Sensor_Fehlerstatus_DC  : 92|4@1+ (1.000000,0.000000) [0.000000|15.000000] "" Vector__XXX
 SG_ OCC_Temp_Sensor_Fehlerstatus_AC  : 96|3@1+ (1.000000,0.000000) [0.000000|7.000000] "" Vector__XXX
 SG_ OCC_Temp_Sensor_Status  : 99|3@1+ (1.000000,0.000000) [0.000000|7.000000] "" Vector__XXX

BU_:  Airbag BAP_Tester ICAS1_Gateway ICAS1_KommunikationsServer LE1 LE2 Motor_BEV Schaltbetaetigung

BO_ 190 Motor_56: 48 Motor_BEV
 SG_ Motor_56_CRC  : 0|8@1+ (1.000000,0.000000) [0.000000|255.000000] "" ICAS1_Gateway LE1 LE2
 SG_ Motor_56_BZ  : 8|4@1+ (1.000000,0.000000) [0.000000|15.000000] "" ICAS1_Gateway LE1 LE2
 SG_ MO_EM1_MinDrehzahl  : 12|14@1+ (2.000000,-10000.000000) [-10000.000000|22764.000000] "Unit_MinutInver" ICAS1_Gateway LE1
 SG_ MO_EM1_MaxDrehzahl  : 26|14@1+ (2.000000,-10000.000000) [-10000.000000|22764.000000] "Unit_MinutInver" ICAS1_Gateway LE1
 SG_ MO_EM1_DynLimit_AR  : 40|8@1+ (1.000000,0.000000) [0.000000|254.000000] "Unit_NewtoMeter" ICAS1_Gateway LE1
 SG_ MO_EM1_Periode_AR  : 48|8@1+ (0.001953,0.000000) [0.000000|0.496094] "Unit_Secon" ICAS1_Gateway LE1
 SG_ MO_EM1_SollMoment  : 56|12@1+ (0.500000,-1023.000000) [-1023.000000|1023.500000] "Unit_NewtoMeter" ICAS1_Gateway LE1
 SG_ MO_EM1_Sollmodus  : 68|4@1+ (1.000000,0.000000) [0.000000|15.000000] "" ICAS1_Gateway LE1
 SG_ MO_EM1_Min_Leistung  : 72|14@1+ (100.000000,-819000.000000) [-819000.000000|819100.000000] "Unit_Watt" ICAS1_Gateway LE1
 SG_ MO_EM1_Max_Leistung  : 86|14@1+ (100.000000,-819000.000000) [-819000.000000|819100.000000] "Unit_Watt" ICAS1_Gateway LE1
 SG_ MO_EM1_Min_Strom_Lim  : 100|13@1+ (0.500000,-2047.000000) [-2047.000000|2047.500000] "Unit_Amper" ICAS1_Gateway LE1
 SG_ MO_EM1_Max_Strom_Lim  : 113|13@1+ (0.500000,-2047.000000) [-2047.000000|2047.500000] "Unit_Amper" ICAS1_Gateway LE1
 SG_ MO_EM1_AR_Anf  : 126|3@1+ (1.000000,0.000000) [0.000000|7.000000] "" ICAS1_Gateway LE1
 SG_ MO_EM1_Kp_AR  : 129|9@1+ (0.003906,0.000000) [0.000000|1.992188] "Unit_NewtoMeterPerRPM" ICAS1_Gateway LE1
 SG_ MO_EM1_SollSpannung  : 138|12@1+ (0.500000,0.000000) [0.000000|2047.000000] "Unit_Volt" ICAS1_Gateway LE1
 SG_ MO_EM2_MinDrehzahl  : 156|14@1+ (2.000000,-10000.000000) [-10000.000000|22764.000000] "Unit_MinutInver" ICAS1_Gateway LE2
 SG_ MO_EM2_MaxDrehzahl  : 170|14@1+ (2.000000,-10000.000000) [-10000.000000|22764.000000] "Unit_MinutInver" ICAS1_Gateway LE2
 SG_ MO_EM2_DynLimit_AR  : 184|8@1+ (1.000000,0.000000) [0.000000|254.000000] "Unit_NewtoMeter" ICAS1_Gateway LE2
 SG_ MO_EM2_Periode_AR  : 192|8@1+ (0.001953,0.000000) [0.000000|0.496094] "Unit_Secon" ICAS1_Gateway LE2
 SG_ MO_EM2_SollMoment  : 200|12@1+ (0.500000,-1023.000000) [-1023.000000|1023.500000] "Unit_NewtoMeter" ICAS1_Gateway LE2
 SG_ MO_EM2_Sollmodus  : 212|4@1+ (1.000000,0.000000) [0.000000|15.000000] "" ICAS1_Gateway LE2
 SG_ MO_EM2_Min_Leistung  : 216|14@1+ (100.000000,-819000.000000) [-819000.000000|819100.000000] "Unit_Watt" ICAS1_Gateway LE2
 SG_ MO_EM2_Max_Leistung  : 230|14@1+ (100.000000,-819000.000000) [-819000.000000|819100.000000] "Unit_Watt" ICAS1_Gateway LE2
 SG_ MO_EM2_Min_Strom_Lim  : 244|13@1+ (0.500000,-2047.000000) [-2047.000000|2047.500000] "Unit_Amper" ICAS1_Gateway LE2
 SG_ MO_EM2_Max_Strom_Lim  : 257|13@1+ (0.500000,-2047.000000) [-2047.000000|2047.500000] "Unit_Amper" ICAS1_Gateway LE2
 SG_ MO_EM2_AR_Anf  : 270|3@1+ (1.000000,0.000000) [0.000000|7.000000] "" ICAS1_Gateway LE2
 SG_ MO_EM2_SollSpannung  : 282|12@1+ (0.500000,0.000000) [0.000000|2047.000000] "Unit_Volt" ICAS1_Gateway LE2
 SG_ MO_DC_Max_Strom_HV  : 296|8@1+ (0.200000,0.000000) [0.000000|50.800000] "Unit_Amper" ICAS1_Gateway
 SG_ MO_DC_SollSpannung_HV  : 304|8@1+ (2.000000,0.000000) [0.000000|508.000000] "Unit_Volt" ICAS1_Gateway
 SG_ MO_EM1_Max_Moment  : 312|12@1+ (0.500000,-1023.000000) [-1023.000000|1023.500000] "Unit_NewtoMeter" ICAS1_Gateway LE1
 SG_ MO_EM1_Min_Moment  : 324|12@1+ (0.500000,-1023.000000) [-1023.000000|1023.500000] "Unit_NewtoMeter" ICAS1_Gateway LE1
 SG_ MO_EM2_Max_Moment  : 336|12@1+ (0.500000,-1023.000000) [-1023.000000|1023.500000] "Unit_NewtoMeter" ICAS1_Gateway LE2
 SG_ MO_EM2_Min_Moment  : 348|12@1+ (0.500000,-1023.000000) [-1023.000000|1023.500000] "Unit_NewtoMeter" ICAS1_Gateway LE2

BO_ 2463978666 Motor_57: 32 Motor_BEV
 SG_ MO_EM1_Min_Spannung_Lim  : 12|10@1+ (1.000000,0.000000) [0.000000|1021.000000] "Unit_Volt" ICAS1_Gateway LE1
 SG_ MO_EM1_Max_Spannung_Lim  : 22|10@1+ (1.000000,0.000000) [0.000000|1021.000000] "Unit_Volt" ICAS1_Gateway LE1
 SG_ MO_EM1_Min_Leistung_Gesamt  : 32|13@1+ (200.000000,-819000.000000) [-819000.000000|818800.000000] "Unit_Watt" ICAS1_Gateway LE1
 SG_ MO_EM1_Max_Leistung_Gesamt  : 45|13@1+ (200.000000,-819000.000000) [-819000.000000|818800.000000] "Unit_Watt" ICAS1_Gateway LE1
 SG_ MO_EM2_Min_Leistung_Gesamt  : 58|13@1+ (200.000000,-819000.000000) [-819000.000000|818800.000000] "Unit_Watt" ICAS1_Gateway LE2
 SG_ MO_EM2_Max_Leistung_Gesamt  : 71|13@1+ (200.000000,-819000.000000) [-819000.000000|818800.000000] "Unit_Watt" ICAS1_Gateway LE2
 SG_ MO_EM2_Min_Spannung_Lim  : 84|10@1+ (1.000000,0.000000) [0.000000|1021.000000] "Unit_Volt" ICAS1_Gateway LE2
 SG_ MO_EM2_Max_Spannung_Lim  : 94|10@1+ (1.000000,0.000000) [0.000000|1021.000000] "Unit_Volt" ICAS1_Gateway LE2
 SG_ MO_EM1_Generator_Leistung  : 104|8@1+ (100.000000,0.000000) [0.000000|25300.000000] "Unit_Watt" ICAS1_Gateway LE1
 SG_ MO_Verbrauch_EM_Ges  : 120|15@1+ (10.000000,0.000000) [0.000000|327670.000000] "Unit_WattSecond" ICAS1_Gateway ICAS1_KommunikationsServer
 SG_ MO_Verbrauch_EM_Ges_Ueberlauf  : 135|1@1+ (1.000000,0.000000) [0.000000|1.000000] "" ICAS1_Gateway ICAS1_KommunikationsServer
 SG_ MO_Rekuperation_Ges_EM  : 136|15@1+ (10.000000,0.000000) [0.000000|327670.000000] "Unit_WattSecond" ICAS1_Gateway ICAS1_KommunikationsServer
 SG_ MO_Rekuperation_EM_Ges_Ueberlauf  : 151|1@1+ (1.000000,0.000000) [0.000000|1.000000] "" ICAS1_Gateway ICAS1_KommunikationsServer
 SG_ MO_Drehzahl_EM  : 152|13@1+ (8.000000,-32768.000000) [-32768.000000|32744.000000] "Unit_RevPerMinute" ICAS1_Gateway
 SG_ MO_Uebersetzung_EM  : 165|10@1+ (0.031250,0.000000) [0.031250|31.906250] "" ICAS1_Gateway
 SG_ MO_Drehzahl_EM_sek  : 175|13@1+ (8.000000,-32768.000000) [-32768.000000|32744.000000] "Unit_RevPerMinute" ICAS1_Gateway
 SG_ MO_Uebersetzung_EM_sek  : 188|10@1+ (0.031250,0.000000) [0.031250|31.906250] "" ICAS1_Gateway

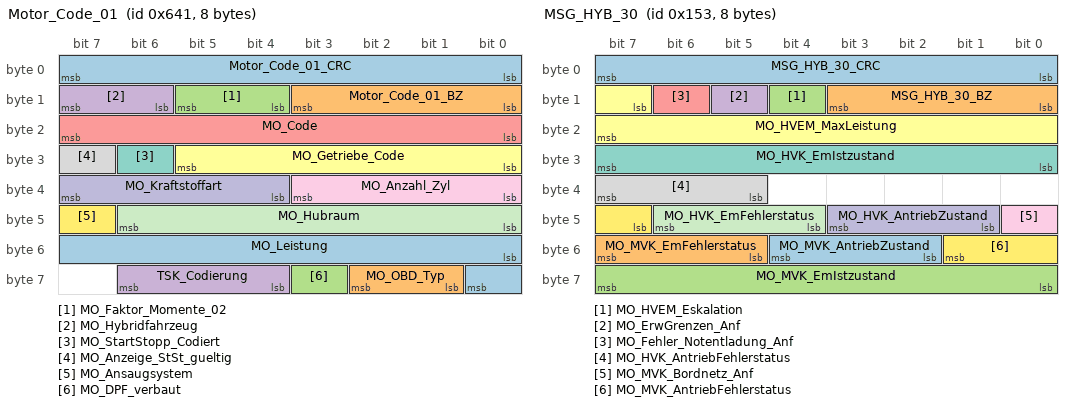
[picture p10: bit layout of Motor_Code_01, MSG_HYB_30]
BO_ 1601 Motor_Code_01: 8 Motor_BEV
 SG_ Motor_Code_01_CRC  : 0|8@1+ (1.000000,0.000000) [0.000000|255.000000] "" ICAS1_Gateway
 SG_ Motor_Code_01_BZ  : 8|4@1+ (1.000000,0.000000) [0.000000|15.000000] "" ICAS1_Gateway
 SG_ MO_Faktor_Momente_02  : 12|2@1+ (1.000000,0.000000) [1.000000|3.000000] "Unit_NewtoMeter" ICAS1_Gateway
 SG_ MO_Hybridfahrzeug  : 14|2@1+ (1.000000,0.000000) [0.000000|3.000000] "" ICAS1_Gateway
 SG_ MO_Code  : 16|8@1+ (1.000000,0.000000) [0.000000|255.000000] "" ICAS1_Gateway
 SG_ MO_Getriebe_Code  : 24|6@1+ (1.000000,0.000000) [0.000000|63.000000] "" ICAS1_Gateway
 SG_ MO_StartStopp_Codiert  : 30|1@1+ (1.000000,0.000000) [0.000000|1.000000] "" ICAS1_Gateway
 SG_ MO_Anzeige_StSt_gueltig  : 31|1@1+ (1.000000,0.000000) [0.000000|1.000000] "" ICAS1_Gateway
 SG_ MO_Anzahl_Zyl  : 32|4@1+ (1.000000,0.000000) [0.000000|15.000000] "" ICAS1_Gateway
 SG_ MO_Kraftstoffart  : 36|4@1+ (1.000000,0.000000) [0.000000|15.000000] "" ICAS1_Gateway ICAS1_KommunikationsServer
 SG_ MO_Hubraum  : 40|7@1+ (0.100000,0.000000) [0.000000|12.700000] "Unit_Liter" ICAS1_Gateway
 SG_ MO_Ansaugsystem  : 47|1@1+ (1.000000,0.000000) [0.000000|1.000000] "" ICAS1_Gateway
 SG_ MO_Leistung  : 48|9@1+ (1.000000,0.000000) [0.000000|511.000000] "Unit_KiloWatt" ICAS1_Gateway
 SG_ MO_OBD_Typ  : 57|2@1+ (1.000000,0.000000) [0.000000|3.000000] "" ICAS1_Gateway
 SG_ MO_DPF_verbaut  : 59|1@1+ (1.000000,0.000000) [0.000000|1.000000] "" ICAS1_Gateway
 SG_ TSK_Codierung  : 60|3@1+ (1.000000,0.000000) [0.000000|7.000000] "" ICAS1_Gateway

BO_ 1155 Motor_Hybrid_06: 8 Motor_BEV
 SG_ Mo_Powermeter_Grenze  : 0|12@1+ (1.000000,0.000000) [0.000000|4092.000000] "" ICAS1_KommunikationsServer
 SG_ MO_Text_Aktivierung_Antrieb  : 12|4@1+ (1.000000,0.000000) [0.000000|15.000000] "" ICAS1_KommunikationsServer
 SG_ MO_Powermeter_Inszenierung_aktiv  : 17|1@1+ (1.000000,0.000000) [0.000000|1.000000] "" Vector__XXX
 SG_ MO_Powermeter_Charge_Grenze  : 18|10@1+ (1.000000,0.000000) [0.000000|1021.000000] "Unit_None" ICAS1_KommunikationsServer
 SG_ MO_Powermeter_Grenze_strategisch  : 28|12@1+ (1.000000,0.000000) [0.000000|4093.000000] "Unit_None" ICAS1_KommunikationsServer
 SG_ MO_Powermeter_untere_E_Grenze  : 40|12@1+ (1.000000,0.000000) [0.000000|4093.000000] "Unit_None" Vector__XXX
 SG_ MO_Powermeter_obere_E_Grenze  : 52|12@1+ (1.000000,0.000000) [0.000000|4093.000000] "Unit_None" Vector__XXX

BO_ 2527679686 MRR_ASM_01: 8 ICAS1_Gateway
 SG_ MRR_HR_ASM_Ereignis  : 0|8@1+ (1.000000,0.000000) [1.000000|254.000000] "" Airbag
 SG_ MRR_HR_ASM_Zeitstempel  : 8|8@1+ (0.080000,0.000000) [0.000000|20.320000] "Unit_Secon" Airbag
 SG_ MRR_HR_ASM_Data_1  : 16|8@1+ (1.000000,0.000000) [0.000000|255.000000] "" Airbag
 SG_ MRR_HR_ASM_Data_2  : 24|8@1+ (1.000000,0.000000) [0.000000|255.000000] "" Airbag
 SG_ MRR_HR_ASM_Data_3  : 32|8@1+ (1.000000,0.000000) [0.000000|255.000000] "" Airbag
 SG_ MRR_HR_ASM_Data_4  : 40|8@1+ (1.000000,0.000000) [0.000000|255.000000] "" Airbag
 SG_ MRR_HR_ASM_Data_5  : 48|8@1+ (1.000000,0.000000) [0.000000|255.000000] "" Airbag
 SG_ MRR_HR_ASM_Data_6  : 56|8@1+ (1.000000,0.000000) [0.000000|255.000000] "" Airbag

BO_ 22 MSG3_WFS_Anfrage: 8 LE2
 SG_ WFS_MSG3_RND  : 0|32@1+ (1.000000,0.000000) [0.000000|4294967295.000000] "" ICAS1_Gateway
 SG_ WFS_MSG3_CRC  : 32|32@1+ (1.000000,0.000000) [0.000000|4294967295.000000] "" ICAS1_Gateway

BO_ 24 MSG4_WFS_Anfrage: 8 LE1
 SG_ WFS_MSG4_RND  : 0|32@1+ (1.000000,0.000000) [0.000000|4294967295.000000] "" ICAS1_Gateway
 SG_ WFS_MSG4_CRC  : 32|32@1+ (1.000000,0.000000) [0.000000|4294967295.000000] "" ICAS1_Gateway

BO_ 339 MSG_HYB_30: 8 Motor_BEV
 SG_ MSG_HYB_30_CRC  : 0|8@1+ (1.000000,0.000000) [0.000000|255.000000] "" Vector__XXX
 SG_ MSG_HYB_30_BZ  : 8|4@1+ (1.000000,0.000000) [0.000000|15.000000] "" Vector__XXX
 SG_ MO_HVEM_Eskalation  : 12|1@1+ (1.000000,0.000000) [0.000000|1.000000] "" ICAS1_Gateway
 SG_ MO_ErwGrenzen_Anf  : 13|1@1+ (1.000000,0.000000) [0.000000|1.000000] "" LE1 LE2
 SG_ MO_Fehler_Notentladung_Anf  : 14|1@1+ (1.000000,0.000000) [0.000000|1.000000] "" Vector__XXX
 SG_ MO_HVEM_MaxLeistung  : 15|9@1+ (50.000000,0.000000) [0.000000|25450.000000] "Unit_Watt" ICAS1_Gateway
 SG_ MO_HVK_EmIstzustand  : 24|8@1+ (1.000000,0.000000) [0.000000|255.000000] "" Vector__XXX
 SG_ MO_HVK_AntriebFehlerstatus  : 37|3@1+ (1.000000,0.000000) [0.000000|7.000000] "" Vector__XXX
 SG_ MO_MVK_Bordnetz_Anf  : 40|1@1+ (1.000000,0.000000) [0.000000|1.000000] "" Vector__XXX
 SG_ MO_HVK_AntriebZustand  : 41|3@1+ (1.000000,0.000000) [0.000000|7.000000] "" Vector__XXX
 SG_ MO_HVK_EmFehlerstatus  : 44|3@1+ (1.000000,0.000000) [0.000000|7.000000] "" Vector__XXX
 SG_ MO_MVK_AntriebFehlerstatus  : 47|3@1+ (1.000000,0.000000) [0.000000|7.000000] "" Vector__XXX
 SG_ MO_MVK_AntriebZustand  : 50|3@1+ (1.000000,0.000000) [0.000000|7.000000] "" Vector__XXX
 SG_ MO_MVK_EmFehlerstatus  : 53|3@1+ (1.000000,0.000000) [0.000000|7.000000] "" Vector__XXX
 SG_ MO_MVK_EmIstzustand  : 56|8@1+ (1.000000,0.000000) [0.000000|255.000000] "" Vector__XXX

BO_ 2600468501 NMH_Airbag_01: 8 Airbag
 SG_ NM_Airbag_01_CBV_AWB  : 12|1@1+ (1.000000,0.000000) [0.000000|1.000000] "" ICAS1_Gateway
 SG_ NM_Airbag_01_CBV_CRI  : 14|1@1+ (1.000000,0.000000) [0.000000|1.000000] "" ICAS1_Gateway
 SG_ NM_Airbag_01_NM_State  : 16|6@1+ (1.000000,0.000000) [0.000000|63.000000] "" LE1 LE2 Motor_BEV Schaltbetaetigung
 SG_ NM_Airbag_01_Car_Wakeup  : 22|1@1+ (1.000000,0.000000) [0.000000|1.000000] "" ICAS1_Gateway
 SG_ NM_Airbag_01_UDS_CC  : 23|1@1+ (1.000000,0.000000) [0.000000|1.000000] "" Vector__XXX
 SG_ NM_Airbag_01_NM_aktiv_KL15  : 24|1@1+ (1.000000,0.000000) [0.000000|1.000000] "" Vector__XXX
 SG_ NM_Airbag_01_NM_aktiv_Diagnose  : 25|1@1+ (1.000000,0.000000) [0.000000|1.000000] "" Vector__XXX
 SG_ NM_Airbag_01_NM_aktiv_Tmin  : 26|1@1+ (1.000000,0.000000) [0.000000|1.000000] "" Vector__XXX
 SG_ NM_Airbag_01_CAB_V10  : 40|24@1+ (1.000000,0.000000) [0.000000|16777215.000000] "" ICAS1_Gateway

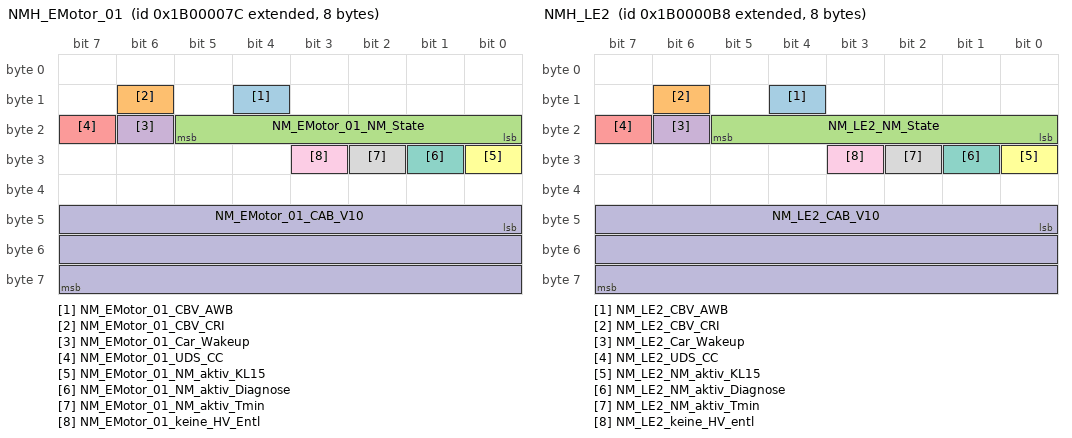
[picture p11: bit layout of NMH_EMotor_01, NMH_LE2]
BO_ 2600468604 NMH_EMotor_01: 8 LE1
 SG_ NM_EMotor_01_CBV_AWB  : 12|1@1+ (1.000000,0.000000) [0.000000|1.000000] "" ICAS1_Gateway
 SG_ NM_EMotor_01_CBV_CRI  : 14|1@1+ (1.000000,0.000000) [0.000000|1.000000] "" ICAS1_Gateway
 SG_ NM_EMotor_01_NM_State  : 16|6@1+ (1.000000,0.000000) [0.000000|63.000000] "" Airbag LE2 Motor_BEV Schaltbetaetigung
 SG_ NM_EMotor_01_Car_Wakeup  : 22|1@1+ (1.000000,0.000000) [0.000000|1.000000] "" ICAS1_Gateway
 SG_ NM_EMotor_01_UDS_CC  : 23|1@1+ (1.000000,0.000000) [0.000000|1.000000] "" Vector__XXX
 SG_ NM_EMotor_01_NM_aktiv_KL15  : 24|1@1+ (1.000000,0.000000) [0.000000|1.000000] "" Vector__XXX
 SG_ NM_EMotor_01_NM_aktiv_Diagnose  : 25|1@1+ (1.000000,0.000000) [0.000000|1.000000] "" Vector__XXX
 SG_ NM_EMotor_01_NM_aktiv_Tmin  : 26|1@1+ (1.000000,0.000000) [0.000000|1.000000] "" Vector__XXX
 SG_ NM_EMotor_01_keine_HV_Entl  : 27|1@1+ (1.000000,0.000000) [0.000000|1.000000] "" Vector__XXX
 SG_ NM_EMotor_01_CAB_V10  : 40|24@1+ (1.000000,0.000000) [0.000000|16777215.000000] "" ICAS1_Gateway

BO_ 2600468496 NMH_Gateway: 8 ICAS1_Gateway
 SG_ NM_Gateway_CBV_AWB  : 12|1@1+ (1.000000,0.000000) [0.000000|1.000000] "" Vector__XXX
 SG_ NM_Gateway_CBV_CRI  : 14|1@1+ (1.000000,0.000000) [0.000000|1.000000] "" Vector__XXX
 SG_ NM_Gateway_NM_State  : 16|6@1+ (1.000000,0.000000) [0.000000|63.000000] "" Airbag LE1 LE2 Motor_BEV Schaltbetaetigung
 SG_ NM_Gateway_Car_Wakeup  : 22|1@1+ (1.000000,0.000000) [0.000000|1.000000] "" Vector__XXX
 SG_ NM_Gateway_UDS_CC  : 23|1@1+ (1.000000,0.000000) [0.000000|1.000000] "" Vector__XXX
 SG_ NM_Gateway_NM_aktiv_KL15  : 24|1@1+ (1.000000,0.000000) [0.000000|1.000000] "" Vector__XXX
 SG_ NM_Gateway_NM_aktiv_Diagnose  : 25|1@1+ (1.000000,0.000000) [0.000000|1.000000] "" Vector__XXX
 SG_ NM_Gateway_NM_aktiv_Tmin  : 26|1@1+ (1.000000,0.000000) [0.000000|1.000000] "" Vector__XXX
 SG_ NM_Gateway_CAB_V10  : 40|24@1+ (1.000000,0.000000) [0.000000|16777215.000000] "" Vector__XXX

BO_ 2600468664 NMH_LE2: 8 LE2
 SG_ NM_LE2_CBV_AWB  : 12|1@1+ (1.000000,0.000000) [0.000000|1.000000] "" ICAS1_Gateway
 SG_ NM_LE2_CBV_CRI  : 14|1@1+ (1.000000,0.000000) [0.000000|1.000000] "" ICAS1_Gateway
 SG_ NM_LE2_NM_State  : 16|6@1+ (1.000000,0.000000) [0.000000|63.000000] "" Airbag LE1 Motor_BEV Schaltbetaetigung
 SG_ NM_LE2_Car_Wakeup  : 22|1@1+ (1.000000,0.000000) [0.000000|1.000000] "" ICAS1_Gateway
 SG_ NM_LE2_UDS_CC  : 23|1@1+ (1.000000,0.000000) [0.000000|1.000000] "" Vector__XXX
 SG_ NM_LE2_NM_aktiv_KL15  : 24|1@1+ (1.000000,0.000000) [0.000000|1.000000] "" Vector__XXX
 SG_ NM_LE2_NM_aktiv_Diagnose  : 25|1@1+ (1.000000,0.000000) [0.000000|1.000000] "" Vector__XXX
 SG_ NM_LE2_NM_aktiv_Tmin  : 26|1@1+ (1.000000,0.000000) [0.000000|1.000000] "" Vector__XXX
 SG_ NM_LE2_keine_HV_entl  : 27|1@1+ (1.000000,0.000000) [0.000000|1.000000] "" Vector__XXX
 SG_ NM_LE2_CAB_V10  : 40|24@1+ (1.000000,0.000000) [0.000000|16777215.000000] "" ICAS1_Gateway

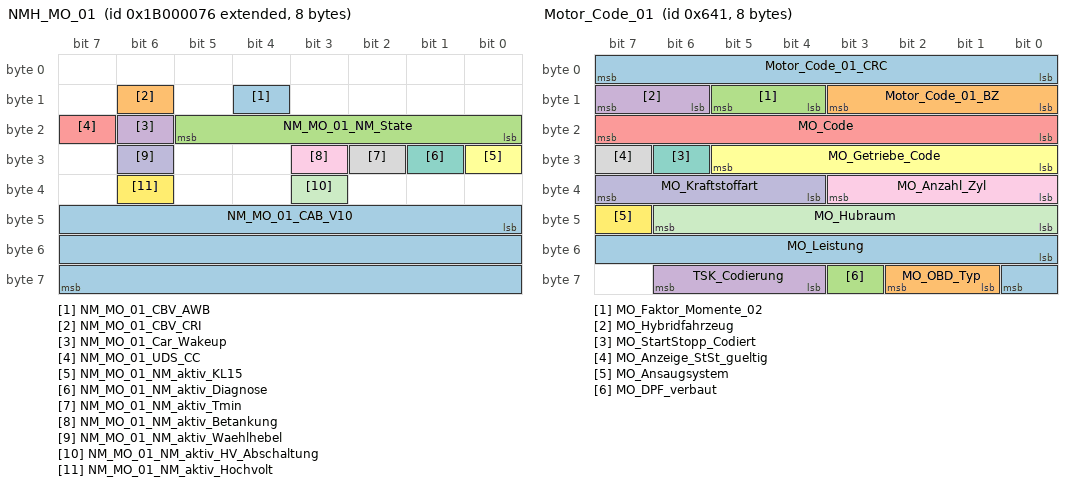
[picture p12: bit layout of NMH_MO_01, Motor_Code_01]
BO_ 2600468598 NMH_MO_01: 8 Motor_BEV
 SG_ NM_MO_01_CBV_AWB  : 12|1@1+ (1.000000,0.000000) [0.000000|1.000000] "" ICAS1_Gateway
 SG_ NM_MO_01_CBV_CRI  : 14|1@1+ (1.000000,0.000000) [0.000000|1.000000] "" ICAS1_Gateway
 SG_ NM_MO_01_NM_State  : 16|6@1+ (1.000000,0.000000) [0.000000|63.000000] "" Airbag LE1 LE2 Schaltbetaetigung
 SG_ NM_MO_01_Car_Wakeup  : 22|1@1+ (1.000000,0.000000) [0.000000|1.000000] "" ICAS1_Gateway
 SG_ NM_MO_01_UDS_CC  : 23|1@1+ (1.000000,0.000000) [0.000000|1.000000] "" Vector__XXX
 SG_ NM_MO_01_NM_aktiv_KL15  : 24|1@1+ (1.000000,0.000000) [0.000000|1.000000] "" Vector__XXX
 SG_ NM_MO_01_NM_aktiv_Diagnose  : 25|1@1+ (1.000000,0.000000) [0.000000|1.000000] "" Vector__XXX
 SG_ NM_MO_01_NM_aktiv_Tmin  : 26|1@1+ (1.000000,0.000000) [0.000000|1.000000] "" Vector__XXX
 SG_ NM_MO_01_NM_aktiv_Betankung  : 27|1@1+ (1.000000,0.000000) [0.000000|1.000000] "" Vector__XXX
 SG_ NM_MO_01_NM_aktiv_Waehlhebel  : 30|1@1+ (1.000000,0.000000) [0.000000|1.000000] "" Vector__XXX
 SG_ NM_MO_01_NM_aktiv_HV_Abschaltung  : 35|1@1+ (1.000000,0.000000) [0.000000|1.000000] "" Vector__XXX
 SG_ NM_MO_01_NM_aktiv_Hochvolt  : 38|1@1+ (1.000000,0.000000) [0.000000|1.000000] "" Vector__XXX
 SG_ NM_MO_01_CAB_V10  : 40|24@1+ (1.000000,0.000000) [0.000000|16777215.000000] "" ICAS1_Gateway

BO_ 2600468733 NMH_Waehlhebel: 8 Schaltbetaetigung
 SG_ NM_Waehlhebel_CBV_AWB  : 12|1@1+ (1.000000,0.000000) [0.000000|1.000000] "" ICAS1_Gateway
 SG_ NM_Waehlhebel_CBV_CRI  : 14|1@1+ (1.000000,0.000000) [0.000000|1.000000] "" ICAS1_Gateway
 SG_ NM_Waehlhebel_NM_State  : 16|6@1+ (1.000000,0.000000) [0.000000|63.000000] "" Airbag LE1 LE2 Motor_BEV
 SG_ NM_Waehlhebel_Car_Wakeup  : 22|1@1+ (1.000000,0.000000) [0.000000|1.000000] "" ICAS1_Gateway
 SG_ NM_Waehlhebel_UDS_CC  : 23|1@1+ (1.000000,0.000000) [0.000000|1.000000] "" Vector__XXX
 SG_ NM_Waehlhebel_NM_aktiv_KL15  : 24|1@1+ (1.000000,0.000000) [0.000000|1.000000] "" Vector__XXX
 SG_ NM_Waehlhebel_NM_aktiv_Diagnose  : 25|1@1+ (1.000000,0.000000) [0.000000|1.000000] "" Vector__XXX
 SG_ NM_Waehlhebel_NM_aktiv_Tmin  : 26|1@1+ (1.000000,0.000000) [0.000000|1.000000] "" Vector__XXX
 SG_ NM_Waehlhebel_CAB_V10  : 40|24@1+ (1.000000,0.000000) [0.000000|16777215.000000] "" ICAS1_Gateway

BO_ 2621440533 OBDC_Airbag_01_Req_FD: 64 ICAS1_Gateway
 SG_ OBDC_Airbag_01_Req_FD_Data  : 0|512@1+ (1.000000,0.000000) [0.000000|13407807929942597099574024998205846127479365820592393377723561443721764030073546976801874298166903427690031858186486050853753882811946569946433649006084096.000000] "" Airbag

BO_ 2621571605 OBDC_Airbag_01_Resp_FD: 64 Airbag
 SG_ OBDC_Airbag_01_Resp_FD_Data  : 0|512@1+ (1.000000,0.000000) [0.000000|13407807929942597099574024998205846127479365820592393377723561443721764030073546976801874298166903427690031858186486050853753882811946569946433649006084096.000000] "" ICAS1_Gateway

BO_ 2621440636 OBDC_EMotor_01_Req_FD: 64 ICAS1_Gateway
 SG_ OBDC_EMotor_01_Req_FD_Data  : 0|512@1+ (1.000000,0.000000) [0.000000|13407807929942597099574024998205846127479365820592393377723561443721764030073546976801874298166903427690031858186486050853753882811946569946433649006084096.000000] "" LE1

BO_ 2621571708 OBDC_EMotor_01_Resp_FD: 64 LE1
 SG_ OBDC_EMotor_01_Resp_FD_Data  : 0|512@1+ (1.000000,0.000000) [0.000000|13407807929942597099574024998205846127479365820592393377723561443721764030073546976801874298166903427690031858186486050853753882811946569946433649006084096.000000] "" ICAS1_Gateway

BO_ 2621440696 OBDC_EMotor_02_Req_FD: 64 ICAS1_Gateway
 SG_ OBDC_EMotor_02_Req_FD_Data  : 0|512@1+ (1.000000,0.000000) [0.000000|13407807929942597099574024998205846127479365820592393377723561443721764030073546976801874298166903427690031858186486050853753882811946569946433649006084096.000000] "" LE2

BO_ 2621571768 OBDC_EMotor_02_Resp_FD: 64 LE2
 SG_ OBDC_EMotor_02_Resp_FD_Data  : 0|512@1+ (1.000000,0.000000) [0.000000|13407807929942597099574024998205846127479365820592393377723561443721764030073546976801874298166903427690031858186486050853753882811946569946433649006084096.000000] "" ICAS1_Gateway

BO_ 2621506048 OBDC_Funktionaler_Req_All_FD: 64 ICAS1_Gateway
 SG_ OBDC_Funktion_Req_All_FD_Data  : 0|512@1+ (1.000000,0.000000) [0.000000|13407807929942597099574024998205846127479365820592393377723561443721764030073546976801874298166903427690031858186486050853753882811946569946433649006084096.000000] "" Airbag LE1 LE2 Motor_BEV

BO_ 2621440630 OBDC_MO_01_Req_FD: 64 ICAS1_Gateway
 SG_ OBDC_MO_01_Req_FD_Data  : 0|512@1+ (1.000000,0.000000) [0.000000|13407807929942597099574024998205846127479365820592393377723561443721764030073546976801874298166903427690031858186486050853753882811946569946433649006084096.000000] "" Motor_BEV

BO_ 2621571702 OBDC_MO_01_Resp_FD: 64 Motor_BEV
 SG_ OBDC_MO_01_Resp_FD_Data  : 0|512@1+ (1.000000,0.000000) [0.000000|13407807929942597099574024998205846127479365820592393377723561443721764030073546976801874298166903427690031858186486050853753882811946569946433649006084096.000000] "" ICAS1_Gateway

BO_ 2564502513 OBDx_allOBD_Req: 8 ICAS1_Gateway
 SG_ OBDx_allOBD_Req_Data  : 0|64@1+ (1.000000,0.000000) [0.000000|18446744073709551616.000000] "" LE1 LE2 Motor_BEV

BO_ 2564425457 OBDx_LE1_Req: 8 ICAS1_Gateway
 SG_ OBDx_LE1_Req_Data  : 0|64@1+ (1.000000,0.000000) [0.000000|18446744073709551616.000000] "" LE1

BO_ 2564485382 OBDx_LE1_Resp: 8 LE1
 SG_ OBDx_LE1_Resp_Data  : 0|64@1+ (1.000000,0.000000) [0.000000|18446744073709551616.000000] "" ICAS1_Gateway

BO_ 2564425713 OBDx_LE2_Req: 8 ICAS1_Gateway
 SG_ OBDx_LE2_Req_Data  : 0|64@1+ (1.000000,0.000000) [0.000000|18446744073709551616.000000] "" LE2

BO_ 2564485383 OBDx_LE2_Resp: 8 LE2
 SG_ OBDx_LE2_Resp_Data  : 0|64@1+ (1.000000,0.000000) [0.000000|18446744073709551616.000000] "" ICAS1_Gateway

BO_ 2564424177 OBDx_MO_01_Req: 8 ICAS1_Gateway
 SG_ OBDx_MO_01_Req_Data  : 0|64@1+ (1.000000,0.000000) [0.000000|18446744073709551616.000000] "" Motor_BEV

BO_ 2564485377 OBDx_MO_01_Resp: 8 Motor_BEV
 SG_ OBDx_MO_01_Resp_Data  : 0|64@1+ (1.000000,0.000000) [0.000000|18446744073709551616.000000] "" ICAS1_Gateway

BO_ 627 OCC_01: 24 ICAS1_Gateway
 SG_ OCC_01_CRC  : 0|8@1+ (1.000000,0.000000) [0.000000|255.000000] "" Vector__XXX
 SG_ OCC_01_BZ  : 8|4@1+ (1.000000,0.000000) [0.000000|15.000000] "" Vector__XXX
 SG_ OCC_Stecker_Status  : 12|2@1+ (1.000000,0.000000) [0.000000|3.000000] "" Vector__XXX
 SG_ OCC_Status_Spgfreiheit  : 14|2@1+ (1.000000,0.000000) [0.000000|3.000000] "" Motor_BEV
 SG_ OCC_DC_IstStrom  : 16|11@1+ (0.100000,0.000000) [0.000000|204.500000] "Unit_Amper" Vector__XXX
 SG_ OCC_CC_Latchstatus_DC_GBT  : 27|3@1+ (1.000000,0.000000) [0.000000|7.000000] "" Vector__XXX
 SG_ OCC_Status_EoHVL  : 30|2@1+ (1.000000,0.000000) [0.000000|3.000000] "" Motor_BEV
 SG_ OCC_I_istAC_Netz_L1  : 32|9@1+ (0.100000,0.000000) [0.000000|50.800000] "Unit_Amper" Vector__XXX
 SG_ OCC_PP_Latchstatus_A  : 41|3@1+ (1.000000,0.000000) [0.000000|7.000000] "" Vector__XXX
 SG_ OCC_PP_Latchstatus_B  : 44|3@1+ (1.000000,0.000000) [0.000000|7.000000] "" Vector__XXX
 SG_ OCC_I_istAC_Netz_L2  : 47|9@1+ (0.100000,0.000000) [0.000000|50.800000] "Unit_Amper" Vector__XXX
 SG_ OCC_I_istAC_Netz_L3  : 56|9@1+ (0.100000,0.000000) [0.000000|50.800000] "Unit_Amper" Vector__XXX
 SG_ OCC_IstModus  : 65|3@1+ (1.000000,0.000000) [0.000000|7.000000] "" Motor_BEV
 SG_ OCC_CP_Status_A  : 68|2@1+ (1.000000,0.000000) [0.000000|3.000000] "" Vector__XXX
 SG_ OCC_CP_Status_B  : 70|2@1+ (1.000000,0.000000) [0.000000|3.000000] "" Vector__XXX
 SG_ OCC_IstSpannung_HV  : 72|10@1+ (1.000000,0.000000) [0.000000|1021.000000] "Unit_Volt" Vector__XXX
 SG_ OCC_PP_Status_A  : 82|2@1+ (1.000000,0.000000) [0.000000|3.000000] "" Vector__XXX
 SG_ OCC_PP_Status_B  : 84|2@1+ (1.000000,0.000000) [0.000000|3.000000] "" Vector__XXX
 SG_ OCC_CC_Status_DC_GBT  : 86|2@1+ (1.000000,0.000000) [0.000000|3.000000] "" Vector__XXX
 SG_ OCC_CC_Fehlerstatus_DC_GBT  : 88|4@1+ (1.000000,0.000000) [0.000000|15.000000] "" Vector__XXX
 SG_ OCC_Temp_Sensor_Fehlerstatus_DC  : 92|4@1+ (1.000000,0.000000) [0.000000|15.000000] "" Vector__XXX
 SG_ OCC_Temp_Sensor_Fehlerstatus_AC  : 96|3@1+ (1.000000,0.000000) [0.000000|7.000000] "" Vector__XXX
 SG_ OCC_Temp_Sensor_Status  : 99|3@1+ (1.000000,0.000000) [0.000000|7.000000] "" Vector__XXX

BU_:  Airbag BAP_Tester ICAS1_Gateway ICAS1_KommunikationsServer LE1 LE2 Motor_BEV Schaltbetaetigung

BO_ 190 Motor_56: 48 Motor_BEV
 SG_ Motor_56_CRC  : 0|8@1+ (1.000000,0.000000) [0.000000|255.000000] "" ICAS1_Gateway LE1 LE2
 SG_ Motor_56_BZ  : 8|4@1+ (1.000000,0.000000) [0.000000|15.000000] "" ICAS1_Gateway LE1 LE2
 SG_ MO_EM1_MinDrehzahl  : 12|14@1+ (2.000000,-10000.000000) [-10000.000000|22764.000000] "Unit_MinutInver" ICAS1_Gateway LE1
 SG_ MO_EM1_MaxDrehzahl  : 26|14@1+ (2.000000,-10000.000000) [-10000.000000|22764.000000] "Unit_MinutInver" ICAS1_Gateway LE1
 SG_ MO_EM1_DynLimit_AR  : 40|8@1+ (1.000000,0.000000) [0.000000|254.000000] "Unit_NewtoMeter" ICAS1_Gateway LE1
 SG_ MO_EM1_Periode_AR  : 48|8@1+ (0.001953,0.000000) [0.000000|0.496094] "Unit_Secon" ICAS1_Gateway LE1
 SG_ MO_EM1_SollMoment  : 56|12@1+ (0.500000,-1023.000000) [-1023.000000|1023.500000] "Unit_NewtoMeter" ICAS1_Gateway LE1
 SG_ MO_EM1_Sollmodus  : 68|4@1+ (1.000000,0.000000) [0.000000|15.000000] "" ICAS1_Gateway LE1
 SG_ MO_EM1_Min_Leistung  : 72|14@1+ (100.000000,-819000.000000) [-819000.000000|819100.000000] "Unit_Watt" ICAS1_Gateway LE1
 SG_ MO_EM1_Max_Leistung  : 86|14@1+ (100.000000,-819000.000000) [-819000.000000|819100.000000] "Unit_Watt" ICAS1_Gateway LE1
 SG_ MO_EM1_Min_Strom_Lim  : 100|13@1+ (0.500000,-2047.000000) [-2047.000000|2047.500000] "Unit_Amper" ICAS1_Gateway LE1
 SG_ MO_EM1_Max_Strom_Lim  : 113|13@1+ (0.500000,-2047.000000) [-2047.000000|2047.500000] "Unit_Amper" ICAS1_Gateway LE1
 SG_ MO_EM1_AR_Anf  : 126|3@1+ (1.000000,0.000000) [0.000000|7.000000] "" ICAS1_Gateway LE1
 SG_ MO_EM1_Kp_AR  : 129|9@1+ (0.003906,0.000000) [0.000000|1.992188] "Unit_NewtoMeterPerRPM" ICAS1_Gateway LE1
 SG_ MO_EM1_SollSpannung  : 138|12@1+ (0.500000,0.000000) [0.000000|2047.000000] "Unit_Volt" ICAS1_Gateway LE1
 SG_ MO_EM2_MinDrehzahl  : 156|14@1+ (2.000000,-10000.000000) [-10000.000000|22764.000000] "Unit_MinutInver" ICAS1_Gateway LE2
 SG_ MO_EM2_MaxDrehzahl  : 170|14@1+ (2.000000,-10000.000000) [-10000.000000|22764.000000] "Unit_MinutInver" ICAS1_Gateway LE2
 SG_ MO_EM2_DynLimit_AR  : 184|8@1+ (1.000000,0.000000) [0.000000|254.000000] "Unit_NewtoMeter" ICAS1_Gateway LE2
 SG_ MO_EM2_Periode_AR  : 192|8@1+ (0.001953,0.000000) [0.000000|0.496094] "Unit_Secon" ICAS1_Gateway LE2
 SG_ MO_EM2_SollMoment  : 200|12@1+ (0.500000,-1023.000000) [-1023.000000|1023.500000] "Unit_NewtoMeter" ICAS1_Gateway LE2
 SG_ MO_EM2_Sollmodus  : 212|4@1+ (1.000000,0.000000) [0.000000|15.000000] "" ICAS1_Gateway LE2
 SG_ MO_EM2_Min_Leistung  : 216|14@1+ (100.000000,-819000.000000) [-819000.000000|819100.000000] "Unit_Watt" ICAS1_Gateway LE2
 SG_ MO_EM2_Max_Leistung  : 230|14@1+ (100.000000,-819000.000000) [-819000.000000|819100.000000] "Unit_Watt" ICAS1_Gateway LE2
 SG_ MO_EM2_Min_Strom_Lim  : 244|13@1+ (0.500000,-2047.000000) [-2047.000000|2047.500000] "Unit_Amper" ICAS1_Gateway LE2
 SG_ MO_EM2_Max_Strom_Lim  : 257|13@1+ (0.500000,-2047.000000) [-2047.000000|2047.500000] "Unit_Amper" ICAS1_Gateway LE2
 SG_ MO_EM2_AR_Anf  : 270|3@1+ (1.000000,0.000000) [0.000000|7.000000] "" ICAS1_Gateway LE2
 SG_ MO_EM2_SollSpannung  : 282|12@1+ (0.500000,0.000000) [0.000000|2047.000000] "Unit_Volt" ICAS1_Gateway LE2
 SG_ MO_DC_Max_Strom_HV  : 296|8@1+ (0.200000,0.000000) [0.000000|50.800000] "Unit_Amper" ICAS1_Gateway
 SG_ MO_DC_SollSpannung_HV  : 304|8@1+ (2.000000,0.000000) [0.000000|508.000000] "Unit_Volt" ICAS1_Gateway
 SG_ MO_EM1_Max_Moment  : 312|12@1+ (0.500000,-1023.000000) [-1023.000000|1023.500000] "Unit_NewtoMeter" ICAS1_Gateway LE1
 SG_ MO_EM1_Min_Moment  : 324|12@1+ (0.500000,-1023.000000) [-1023.000000|1023.500000] "Unit_NewtoMeter" ICAS1_Gateway LE1
 SG_ MO_EM2_Max_Moment  : 336|12@1+ (0.500000,-1023.000000) [-1023.000000|1023.500000] "Unit_NewtoMeter" ICAS1_Gateway LE2
 SG_ MO_EM2_Min_Moment  : 348|12@1+ (0.500000,-1023.000000) [-1023.000000|1023.500000] "Unit_NewtoMeter" ICAS1_Gateway LE2

BO_ 2463978666 Motor_57: 32 Motor_BEV
 SG_ MO_EM1_Min_Spannung_Lim  : 12|10@1+ (1.000000,0.000000) [0.000000|1021.000000] "Unit_Volt" ICAS1_Gateway LE1
 SG_ MO_EM1_Max_Spannung_Lim  : 22|10@1+ (1.000000,0.000000) [0.000000|1021.000000] "Unit_Volt" ICAS1_Gateway LE1
 SG_ MO_EM1_Min_Leistung_Gesamt  : 32|13@1+ (200.000000,-819000.000000) [-819000.000000|818800.000000] "Unit_Watt" ICAS1_Gateway LE1
 SG_ MO_EM1_Max_Leistung_Gesamt  : 45|13@1+ (200.000000,-819000.000000) [-819000.000000|818800.000000] "Unit_Watt" ICAS1_Gateway LE1
 SG_ MO_EM2_Min_Leistung_Gesamt  : 58|13@1+ (200.000000,-819000.000000) [-819000.000000|818800.000000] "Unit_Watt" ICAS1_Gateway LE2
 SG_ MO_EM2_Max_Leistung_Gesamt  : 71|13@1+ (200.000000,-819000.000000) [-819000.000000|818800.000000] "Unit_Watt" ICAS1_Gateway LE2
 SG_ MO_EM2_Min_Spannung_Lim  : 84|10@1+ (1.000000,0.000000) [0.000000|1021.000000] "Unit_Volt" ICAS1_Gateway LE2
 SG_ MO_EM2_Max_Spannung_Lim  : 94|10@1+ (1.000000,0.000000) [0.000000|1021.000000] "Unit_Volt" ICAS1_Gateway LE2
 SG_ MO_EM1_Generator_Leistung  : 104|8@1+ (100.000000,0.000000) [0.000000|25300.000000] "Unit_Watt" ICAS1_Gateway LE1
 SG_ MO_Verbrauch_EM_Ges  : 120|15@1+ (10.000000,0.000000) [0.000000|327670.000000] "Unit_WattSecond" ICAS1_Gateway ICAS1_KommunikationsServer
 SG_ MO_Verbrauch_EM_Ges_Ueberlauf  : 135|1@1+ (1.000000,0.000000) [0.000000|1.000000] "" ICAS1_Gateway ICAS1_KommunikationsServer
 SG_ MO_Rekuperation_Ges_EM  : 136|15@1+ (10.000000,0.000000) [0.000000|327670.000000] "Unit_WattSecond" ICAS1_Gateway ICAS1_KommunikationsServer
 SG_ MO_Rekuperation_EM_Ges_Ueberlauf  : 151|1@1+ (1.000000,0.000000) [0.000000|1.000000] "" ICAS1_Gateway ICAS1_KommunikationsServer
 SG_ MO_Drehzahl_EM  : 152|13@1+ (8.000000,-32768.000000) [-32768.000000|32744.000000] "Unit_RevPerMinute" ICAS1_Gateway
 SG_ MO_Uebersetzung_EM  : 165|10@1+ (0.031250,0.000000) [0.031250|31.906250] "" ICAS1_Gateway
 SG_ MO_Drehzahl_EM_sek  : 175|13@1+ (8.000000,-32768.000000) [-32768.000000|32744.000000] "Unit_RevPerMinute" ICAS1_Gateway
 SG_ MO_Uebersetzung_EM_sek  : 188|10@1+ (0.031250,0.000000) [0.031250|31.906250] "" ICAS1_Gateway

BO_ 1601 Motor_Code_01: 8 Motor_BEV
 SG_ Motor_Code_01_CRC  : 0|8@1+ (1.000000,0.000000) [0.000000|255.000000] "" ICAS1_Gateway
 SG_ Motor_Code_01_BZ  : 8|4@1+ (1.000000,0.000000) [0.000000|15.000000] "" ICAS1_Gateway
 SG_ MO_Faktor_Momente_02  : 12|2@1+ (1.000000,0.000000) [1.000000|3.000000] "Unit_NewtoMeter" ICAS1_Gateway
 SG_ MO_Hybridfahrzeug  : 14|2@1+ (1.000000,0.000000) [0.000000|3.000000] "" ICAS1_Gateway
 SG_ MO_Code  : 16|8@1+ (1.000000,0.000000) [0.000000|255.000000] "" ICAS1_Gateway
 SG_ MO_Getriebe_Code  : 24|6@1+ (1.000000,0.000000) [0.000000|63.000000] "" ICAS1_Gateway
 SG_ MO_StartStopp_Codiert  : 30|1@1+ (1.000000,0.000000) [0.000000|1.000000] "" ICAS1_Gateway
 SG_ MO_Anzeige_StSt_gueltig  : 31|1@1+ (1.000000,0.000000) [0.000000|1.000000] "" ICAS1_Gateway
 SG_ MO_Anzahl_Zyl  : 32|4@1+ (1.000000,0.000000) [0.000000|15.000000] "" ICAS1_Gateway
 SG_ MO_Kraftstoffart  : 36|4@1+ (1.000000,0.000000) [0.000000|15.000000] "" ICAS1_Gateway ICAS1_KommunikationsServer
 SG_ MO_Hubraum  : 40|7@1+ (0.100000,0.000000) [0.000000|12.700000] "Unit_Liter" ICAS1_Gateway
 SG_ MO_Ansaugsystem  : 47|1@1+ (1.000000,0.000000) [0.000000|1.000000] "" ICAS1_Gateway
 SG_ MO_Leistung  : 48|9@1+ (1.000000,0.000000) [0.000000|511.000000] "Unit_KiloWatt" ICAS1_Gateway
 SG_ MO_OBD_Typ  : 57|2@1+ (1.000000,0.000000) [0.000000|3.000000] "" ICAS1_Gateway
 SG_ MO_DPF_verbaut  : 59|1@1+ (1.000000,0.000000) [0.000000|1.000000] "" ICAS1_Gateway
 SG_ TSK_Codierung  : 60|3@1+ (1.000000,0.000000) [0.000000|7.000000] "" ICAS1_Gateway

BO_ 1155 Motor_Hybrid_06: 8 Motor_BEV
 SG_ Mo_Powermeter_Grenze  : 0|12@1+ (1.000000,0.000000) [0.000000|4092.000000] "" ICAS1_KommunikationsServer
 SG_ MO_Text_Aktivierung_Antrieb  : 12|4@1+ (1.000000,0.000000) [0.000000|15.000000] "" ICAS1_KommunikationsServer
 SG_ MO_Powermeter_Inszenierung_aktiv  : 17|1@1+ (1.000000,0.000000) [0.000000|1.000000] "" Vector__XXX
 SG_ MO_Powermeter_Charge_Grenze  : 18|10@1+ (1.000000,0.000000) [0.000000|1021.000000] "Unit_None" ICAS1_KommunikationsServer
 SG_ MO_Powermeter_Grenze_strategisch  : 28|12@1+ (1.000000,0.000000) [0.000000|4093.000000] "Unit_None" ICAS1_KommunikationsServer
 SG_ MO_Powermeter_untere_E_Grenze  : 40|12@1+ (1.000000,0.000000) [0.000000|4093.000000] "Unit_None" Vector__XXX
 SG_ MO_Powermeter_obere_E_Grenze  : 52|12@1+ (1.000000,0.000000) [0.000000|4093.000000] "Unit_None" Vector__XXX

BO_ 2527679686 MRR_ASM_01: 8 ICAS1_Gateway
 SG_ MRR_HR_ASM_Ereignis  : 0|8@1+ (1.000000,0.000000) [1.000000|254.000000] "" Airbag
 SG_ MRR_HR_ASM_Zeitstempel  : 8|8@1+ (0.080000,0.000000) [0.000000|20.320000] "Unit_Secon" Airbag
 SG_ MRR_HR_ASM_Data_1  : 16|8@1+ (1.000000,0.000000) [0.000000|255.000000] "" Airbag
 SG_ MRR_HR_ASM_Data_2  : 24|8@1+ (1.000000,0.000000) [0.000000|255.000000] "" Airbag
 SG_ MRR_HR_ASM_Data_3  : 32|8@1+ (1.000000,0.000000) [0.000000|255.000000] "" Airbag
 SG_ MRR_HR_ASM_Data_4  : 40|8@1+ (1.000000,0.000000) [0.000000|255.000000] "" Airbag
 SG_ MRR_HR_ASM_Data_5  : 48|8@1+ (1.000000,0.000000) [0.000000|255.000000] "" Airbag
 SG_ MRR_HR_ASM_Data_6  : 56|8@1+ (1.000000,0.000000) [0.000000|255.000000] "" Airbag

BO_ 22 MSG3_WFS_Anfrage: 8 LE2
 SG_ WFS_MSG3_RND  : 0|32@1+ (1.000000,0.000000) [0.000000|4294967295.000000] "" ICAS1_Gateway
 SG_ WFS_MSG3_CRC  : 32|32@1+ (1.000000,0.000000) [0.000000|4294967295.000000] "" ICAS1_Gateway

BO_ 24 MSG4_WFS_Anfrage: 8 LE1
 SG_ WFS_MSG4_RND  : 0|32@1+ (1.000000,0.000000) [0.000000|4294967295.000000] "" ICAS1_Gateway
 SG_ WFS_MSG4_CRC  : 32|32@1+ (1.000000,0.000000) [0.000000|4294967295.000000] "" ICAS1_Gateway

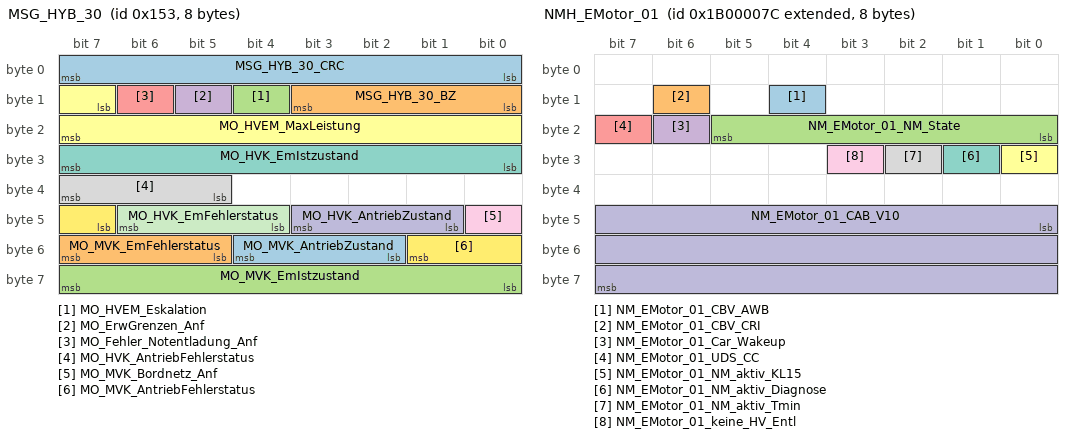
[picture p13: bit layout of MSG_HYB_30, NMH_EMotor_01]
BO_ 339 MSG_HYB_30: 8 Motor_BEV
 SG_ MSG_HYB_30_CRC  : 0|8@1+ (1.000000,0.000000) [0.000000|255.000000] "" Vector__XXX
 SG_ MSG_HYB_30_BZ  : 8|4@1+ (1.000000,0.000000) [0.000000|15.000000] "" Vector__XXX
 SG_ MO_HVEM_Eskalation  : 12|1@1+ (1.000000,0.000000) [0.000000|1.000000] "" ICAS1_Gateway
 SG_ MO_ErwGrenzen_Anf  : 13|1@1+ (1.000000,0.000000) [0.000000|1.000000] "" LE1 LE2
 SG_ MO_Fehler_Notentladung_Anf  : 14|1@1+ (1.000000,0.000000) [0.000000|1.000000] "" Vector__XXX
 SG_ MO_HVEM_MaxLeistung  : 15|9@1+ (50.000000,0.000000) [0.000000|25450.000000] "Unit_Watt" ICAS1_Gateway
 SG_ MO_HVK_EmIstzustand  : 24|8@1+ (1.000000,0.000000) [0.000000|255.000000] "" Vector__XXX
 SG_ MO_HVK_AntriebFehlerstatus  : 37|3@1+ (1.000000,0.000000) [0.000000|7.000000] "" Vector__XXX
 SG_ MO_MVK_Bordnetz_Anf  : 40|1@1+ (1.000000,0.000000) [0.000000|1.000000] "" Vector__XXX
 SG_ MO_HVK_AntriebZustand  : 41|3@1+ (1.000000,0.000000) [0.000000|7.000000] "" Vector__XXX
 SG_ MO_HVK_EmFehlerstatus  : 44|3@1+ (1.000000,0.000000) [0.000000|7.000000] "" Vector__XXX
 SG_ MO_MVK_AntriebFehlerstatus  : 47|3@1+ (1.000000,0.000000) [0.000000|7.000000] "" Vector__XXX
 SG_ MO_MVK_AntriebZustand  : 50|3@1+ (1.000000,0.000000) [0.000000|7.000000] "" Vector__XXX
 SG_ MO_MVK_EmFehlerstatus  : 53|3@1+ (1.000000,0.000000) [0.000000|7.000000] "" Vector__XXX
 SG_ MO_MVK_EmIstzustand  : 56|8@1+ (1.000000,0.000000) [0.000000|255.000000] "" Vector__XXX

BO_ 2600468501 NMH_Airbag_01: 8 Airbag
 SG_ NM_Airbag_01_CBV_AWB  : 12|1@1+ (1.000000,0.000000) [0.000000|1.000000] "" ICAS1_Gateway
 SG_ NM_Airbag_01_CBV_CRI  : 14|1@1+ (1.000000,0.000000) [0.000000|1.000000] "" ICAS1_Gateway
 SG_ NM_Airbag_01_NM_State  : 16|6@1+ (1.000000,0.000000) [0.000000|63.000000] "" LE1 LE2 Motor_BEV Schaltbetaetigung
 SG_ NM_Airbag_01_Car_Wakeup  : 22|1@1+ (1.000000,0.000000) [0.000000|1.000000] "" ICAS1_Gateway
 SG_ NM_Airbag_01_UDS_CC  : 23|1@1+ (1.000000,0.000000) [0.000000|1.000000] "" Vector__XXX
 SG_ NM_Airbag_01_NM_aktiv_KL15  : 24|1@1+ (1.000000,0.000000) [0.000000|1.000000] "" Vector__XXX
 SG_ NM_Airbag_01_NM_aktiv_Diagnose  : 25|1@1+ (1.000000,0.000000) [0.000000|1.000000] "" Vector__XXX
 SG_ NM_Airbag_01_NM_aktiv_Tmin  : 26|1@1+ (1.000000,0.000000) [0.000000|1.000000] "" Vector__XXX
 SG_ NM_Airbag_01_CAB_V10  : 40|24@1+ (1.000000,0.000000) [0.000000|16777215.000000] "" ICAS1_Gateway

BO_ 2600468604 NMH_EMotor_01: 8 LE1
 SG_ NM_EMotor_01_CBV_AWB  : 12|1@1+ (1.000000,0.000000) [0.000000|1.000000] "" ICAS1_Gateway
 SG_ NM_EMotor_01_CBV_CRI  : 14|1@1+ (1.000000,0.000000) [0.000000|1.000000] "" ICAS1_Gateway
 SG_ NM_EMotor_01_NM_State  : 16|6@1+ (1.000000,0.000000) [0.000000|63.000000] "" Airbag LE2 Motor_BEV Schaltbetaetigung
 SG_ NM_EMotor_01_Car_Wakeup  : 22|1@1+ (1.000000,0.000000) [0.000000|1.000000] "" ICAS1_Gateway
 SG_ NM_EMotor_01_UDS_CC  : 23|1@1+ (1.000000,0.000000) [0.000000|1.000000] "" Vector__XXX
 SG_ NM_EMotor_01_NM_aktiv_KL15  : 24|1@1+ (1.000000,0.000000) [0.000000|1.000000] "" Vector__XXX
 SG_ NM_EMotor_01_NM_aktiv_Diagnose  : 25|1@1+ (1.000000,0.000000) [0.000000|1.000000] "" Vector__XXX
 SG_ NM_EMotor_01_NM_aktiv_Tmin  : 26|1@1+ (1.000000,0.000000) [0.000000|1.000000] "" Vector__XXX
 SG_ NM_EMotor_01_keine_HV_Entl  : 27|1@1+ (1.000000,0.000000) [0.000000|1.000000] "" Vector__XXX
 SG_ NM_EMotor_01_CAB_V10  : 40|24@1+ (1.000000,0.000000) [0.000000|16777215.000000] "" ICAS1_Gateway

BO_ 2600468496 NMH_Gateway: 8 ICAS1_Gateway
 SG_ NM_Gateway_CBV_AWB  : 12|1@1+ (1.000000,0.000000) [0.000000|1.000000] "" Vector__XXX
 SG_ NM_Gateway_CBV_CRI  : 14|1@1+ (1.000000,0.000000) [0.000000|1.000000] "" Vector__XXX
 SG_ NM_Gateway_NM_State  : 16|6@1+ (1.000000,0.000000) [0.000000|63.000000] "" Airbag LE1 LE2 Motor_BEV Schaltbetaetigung
 SG_ NM_Gateway_Car_Wakeup  : 22|1@1+ (1.000000,0.000000) [0.000000|1.000000] "" Vector__XXX
 SG_ NM_Gateway_UDS_CC  : 23|1@1+ (1.000000,0.000000) [0.000000|1.000000] "" Vector__XXX
 SG_ NM_Gateway_NM_aktiv_KL15  : 24|1@1+ (1.000000,0.000000) [0.000000|1.000000] "" Vector__XXX
 SG_ NM_Gateway_NM_aktiv_Diagnose  : 25|1@1+ (1.000000,0.000000) [0.000000|1.000000] "" Vector__XXX
 SG_ NM_Gateway_NM_aktiv_Tmin  : 26|1@1+ (1.000000,0.000000) [0.000000|1.000000] "" Vector__XXX
 SG_ NM_Gateway_CAB_V10  : 40|24@1+ (1.000000,0.000000) [0.000000|16777215.000000] "" Vector__XXX

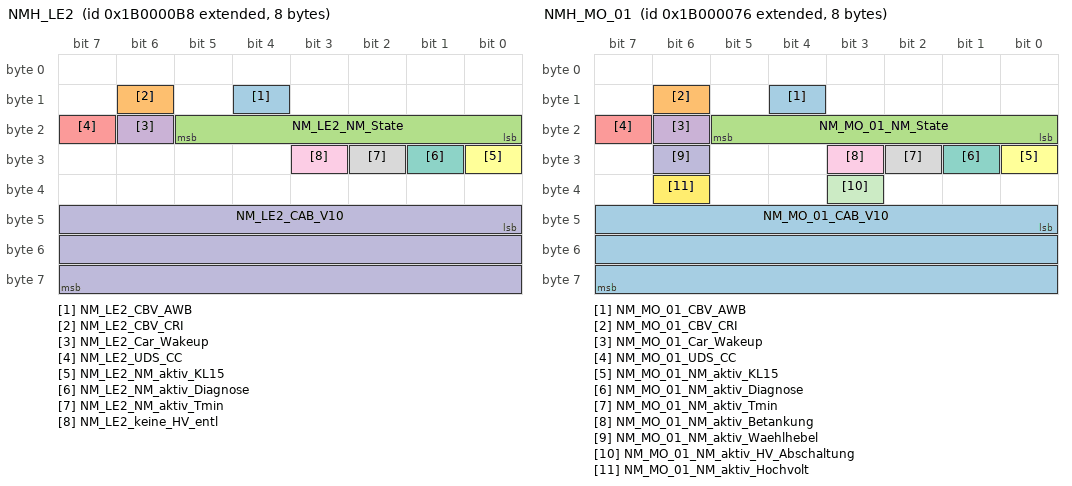
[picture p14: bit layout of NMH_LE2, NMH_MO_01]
BO_ 2600468664 NMH_LE2: 8 LE2
 SG_ NM_LE2_CBV_AWB  : 12|1@1+ (1.000000,0.000000) [0.000000|1.000000] "" ICAS1_Gateway
 SG_ NM_LE2_CBV_CRI  : 14|1@1+ (1.000000,0.000000) [0.000000|1.000000] "" ICAS1_Gateway
 SG_ NM_LE2_NM_State  : 16|6@1+ (1.000000,0.000000) [0.000000|63.000000] "" Airbag LE1 Motor_BEV Schaltbetaetigung
 SG_ NM_LE2_Car_Wakeup  : 22|1@1+ (1.000000,0.000000) [0.000000|1.000000] "" ICAS1_Gateway
 SG_ NM_LE2_UDS_CC  : 23|1@1+ (1.000000,0.000000) [0.000000|1.000000] "" Vector__XXX
 SG_ NM_LE2_NM_aktiv_KL15  : 24|1@1+ (1.000000,0.000000) [0.000000|1.000000] "" Vector__XXX
 SG_ NM_LE2_NM_aktiv_Diagnose  : 25|1@1+ (1.000000,0.000000) [0.000000|1.000000] "" Vector__XXX
 SG_ NM_LE2_NM_aktiv_Tmin  : 26|1@1+ (1.000000,0.000000) [0.000000|1.000000] "" Vector__XXX
 SG_ NM_LE2_keine_HV_entl  : 27|1@1+ (1.000000,0.000000) [0.000000|1.000000] "" Vector__XXX
 SG_ NM_LE2_CAB_V10  : 40|24@1+ (1.000000,0.000000) [0.000000|16777215.000000] "" ICAS1_Gateway

BO_ 2600468598 NMH_MO_01: 8 Motor_BEV
 SG_ NM_MO_01_CBV_AWB  : 12|1@1+ (1.000000,0.000000) [0.000000|1.000000] "" ICAS1_Gateway
 SG_ NM_MO_01_CBV_CRI  : 14|1@1+ (1.000000,0.000000) [0.000000|1.000000] "" ICAS1_Gateway
 SG_ NM_MO_01_NM_State  : 16|6@1+ (1.000000,0.000000) [0.000000|63.000000] "" Airbag LE1 LE2 Schaltbetaetigung
 SG_ NM_MO_01_Car_Wakeup  : 22|1@1+ (1.000000,0.000000) [0.000000|1.000000] "" ICAS1_Gateway
 SG_ NM_MO_01_UDS_CC  : 23|1@1+ (1.000000,0.000000) [0.000000|1.000000] "" Vector__XXX
 SG_ NM_MO_01_NM_aktiv_KL15  : 24|1@1+ (1.000000,0.000000) [0.000000|1.000000] "" Vector__XXX
 SG_ NM_MO_01_NM_aktiv_Diagnose  : 25|1@1+ (1.000000,0.000000) [0.000000|1.000000] "" Vector__XXX
 SG_ NM_MO_01_NM_aktiv_Tmin  : 26|1@1+ (1.000000,0.000000) [0.000000|1.000000] "" Vector__XXX
 SG_ NM_MO_01_NM_aktiv_Betankung  : 27|1@1+ (1.000000,0.000000) [0.000000|1.000000] "" Vector__XXX
 SG_ NM_MO_01_NM_aktiv_Waehlhebel  : 30|1@1+ (1.000000,0.000000) [0.000000|1.000000] "" Vector__XXX
 SG_ NM_MO_01_NM_aktiv_HV_Abschaltung  : 35|1@1+ (1.000000,0.000000) [0.000000|1.000000] "" Vector__XXX
 SG_ NM_MO_01_NM_aktiv_Hochvolt  : 38|1@1+ (1.000000,0.000000) [0.000000|1.000000] "" Vector__XXX
 SG_ NM_MO_01_CAB_V10  : 40|24@1+ (1.000000,0.000000) [0.000000|16777215.000000] "" ICAS1_Gateway

BO_ 2600468733 NMH_Waehlhebel: 8 Schaltbetaetigung
 SG_ NM_Waehlhebel_CBV_AWB  : 12|1@1+ (1.000000,0.000000) [0.000000|1.000000] "" ICAS1_Gateway
 SG_ NM_Waehlhebel_CBV_CRI  : 14|1@1+ (1.000000,0.000000) [0.000000|1.000000] "" ICAS1_Gateway
 SG_ NM_Waehlhebel_NM_State  : 16|6@1+ (1.000000,0.000000) [0.000000|63.000000] "" Airbag LE1 LE2 Motor_BEV
 SG_ NM_Waehlhebel_Car_Wakeup  : 22|1@1+ (1.000000,0.000000) [0.000000|1.000000] "" ICAS1_Gateway
 SG_ NM_Waehlhebel_UDS_CC  : 23|1@1+ (1.000000,0.000000) [0.000000|1.000000] "" Vector__XXX
 SG_ NM_Waehlhebel_NM_aktiv_KL15  : 24|1@1+ (1.000000,0.000000) [0.000000|1.000000] "" Vector__XXX
 SG_ NM_Waehlhebel_NM_aktiv_Diagnose  : 25|1@1+ (1.000000,0.000000) [0.000000|1.000000] "" Vector__XXX
 SG_ NM_Waehlhebel_NM_aktiv_Tmin  : 26|1@1+ (1.000000,0.000000) [0.000000|1.000000] "" Vector__XXX
 SG_ NM_Waehlhebel_CAB_V10  : 40|24@1+ (1.000000,0.000000) [0.000000|16777215.000000] "" ICAS1_Gateway

BO_ 2621440533 OBDC_Airbag_01_Req_FD: 64 ICAS1_Gateway
 SG_ OBDC_Airbag_01_Req_FD_Data  : 0|512@1+ (1.000000,0.000000) [0.000000|13407807929942597099574024998205846127479365820592393377723561443721764030073546976801874298166903427690031858186486050853753882811946569946433649006084096.000000] "" Airbag

BO_ 2621571605 OBDC_Airbag_01_Resp_FD: 64 Airbag
 SG_ OBDC_Airbag_01_Resp_FD_Data  : 0|512@1+ (1.000000,0.000000) [0.000000|13407807929942597099574024998205846127479365820592393377723561443721764030073546976801874298166903427690031858186486050853753882811946569946433649006084096.000000] "" ICAS1_Gateway

BO_ 2621440636 OBDC_EMotor_01_Req_FD: 64 ICAS1_Gateway
 SG_ OBDC_EMotor_01_Req_FD_Data  : 0|512@1+ (1.000000,0.000000) [0.000000|13407807929942597099574024998205846127479365820592393377723561443721764030073546976801874298166903427690031858186486050853753882811946569946433649006084096.000000] "" LE1

BO_ 2621571708 OBDC_EMotor_01_Resp_FD: 64 LE1
 SG_ OBDC_EMotor_01_Resp_FD_Data  : 0|512@1+ (1.000000,0.000000) [0.000000|13407807929942597099574024998205846127479365820592393377723561443721764030073546976801874298166903427690031858186486050853753882811946569946433649006084096.000000] "" ICAS1_Gateway

BO_ 2621440696 OBDC_EMotor_02_Req_FD: 64 ICAS1_Gateway
 SG_ OBDC_EMotor_02_Req_FD_Data  : 0|512@1+ (1.000000,0.000000) [0.000000|13407807929942597099574024998205846127479365820592393377723561443721764030073546976801874298166903427690031858186486050853753882811946569946433649006084096.000000] "" LE2

BO_ 2621571768 OBDC_EMotor_02_Resp_FD: 64 LE2
 SG_ OBDC_EMotor_02_Resp_FD_Data  : 0|512@1+ (1.000000,0.000000) [0.000000|13407807929942597099574024998205846127479365820592393377723561443721764030073546976801874298166903427690031858186486050853753882811946569946433649006084096.000000] "" ICAS1_Gateway

BO_ 2621506048 OBDC_Funktionaler_Req_All_FD: 64 ICAS1_Gateway
 SG_ OBDC_Funktion_Req_All_FD_Data  : 0|512@1+ (1.000000,0.000000) [0.000000|13407807929942597099574024998205846127479365820592393377723561443721764030073546976801874298166903427690031858186486050853753882811946569946433649006084096.000000] "" Airbag LE1 LE2 Motor_BEV

BO_ 2621440630 OBDC_MO_01_Req_FD: 64 ICAS1_Gateway
 SG_ OBDC_MO_01_Req_FD_Data  : 0|512@1+ (1.000000,0.000000) [0.000000|13407807929942597099574024998205846127479365820592393377723561443721764030073546976801874298166903427690031858186486050853753882811946569946433649006084096.000000] "" Motor_BEV

BO_ 2621571702 OBDC_MO_01_Resp_FD: 64 Motor_BEV
 SG_ OBDC_MO_01_Resp_FD_Data  : 0|512@1+ (1.000000,0.000000) [0.000000|13407807929942597099574024998205846127479365820592393377723561443721764030073546976801874298166903427690031858186486050853753882811946569946433649006084096.000000] "" ICAS1_Gateway

BO_ 2564502513 OBDx_allOBD_Req: 8 ICAS1_Gateway
 SG_ OBDx_allOBD_Req_Data  : 0|64@1+ (1.000000,0.000000) [0.000000|18446744073709551616.000000] "" LE1 LE2 Motor_BEV

BO_ 2564425457 OBDx_LE1_Req: 8 ICAS1_Gateway
 SG_ OBDx_LE1_Req_Data  : 0|64@1+ (1.000000,0.000000) [0.000000|18446744073709551616.000000] "" LE1

BO_ 2564485382 OBDx_LE1_Resp: 8 LE1
 SG_ OBDx_LE1_Resp_Data  : 0|64@1+ (1.000000,0.000000) [0.000000|18446744073709551616.000000] "" ICAS1_Gateway

BO_ 2564425713 OBDx_LE2_Req: 8 ICAS1_Gateway
 SG_ OBDx_LE2_Req_Data  : 0|64@1+ (1.000000,0.000000) [0.000000|18446744073709551616.000000] "" LE2

BO_ 2564485383 OBDx_LE2_Resp: 8 LE2
 SG_ OBDx_LE2_Resp_Data  : 0|64@1+ (1.000000,0.000000) [0.000000|18446744073709551616.000000] "" ICAS1_Gateway

BO_ 2564424177 OBDx_MO_01_Req: 8 ICAS1_Gateway
 SG_ OBDx_MO_01_Req_Data  : 0|64@1+ (1.000000,0.000000) [0.000000|18446744073709551616.000000] "" Motor_BEV

BO_ 2564485377 OBDx_MO_01_Resp: 8 Motor_BEV
 SG_ OBDx_MO_01_Resp_Data  : 0|64@1+ (1.000000,0.000000) [0.000000|18446744073709551616.000000] "" ICAS1_Gateway

BO_ 627 OCC_01: 24 ICAS1_Gateway
 SG_ OCC_01_CRC  : 0|8@1+ (1.000000,0.000000) [0.000000|255.000000] "" Vector__XXX
 SG_ OCC_01_BZ  : 8|4@1+ (1.000000,0.000000) [0.000000|15.000000] "" Vector__XXX
 SG_ OCC_Stecker_Status  : 12|2@1+ (1.000000,0.000000) [0.000000|3.000000] "" Vector__XXX
 SG_ OCC_Status_Spgfreiheit  : 14|2@1+ (1.000000,0.000000) [0.000000|3.000000] "" Motor_BEV
 SG_ OCC_DC_IstStrom  : 16|11@1+ (0.100000,0.000000) [0.000000|204.500000] "Unit_Amper" Vector__XXX
 SG_ OCC_CC_Latchstatus_DC_GBT  : 27|3@1+ (1.000000,0.000000) [0.000000|7.000000] "" Vector__XXX
 SG_ OCC_Status_EoHVL  : 30|2@1+ (1.000000,0.000000) [0.000000|3.000000] "" Motor_BEV
 SG_ OCC_I_istAC_Netz_L1  : 32|9@1+ (0.100000,0.000000) [0.000000|50.800000] "Unit_Amper" Vector__XXX
 SG_ OCC_PP_Latchstatus_A  : 41|3@1+ (1.000000,0.000000) [0.000000|7.000000] "" Vector__XXX
 SG_ OCC_PP_Latchstatus_B  : 44|3@1+ (1.000000,0.000000) [0.000000|7.000000] "" Vector__XXX
 SG_ OCC_I_istAC_Netz_L2  : 47|9@1+ (0.100000,0.000000) [0.000000|50.800000] "Unit_Amper" Vector__XXX
 SG_ OCC_I_istAC_Netz_L3  : 56|9@1+ (0.100000,0.000000) [0.000000|50.800000] "Unit_Amper" Vector__XXX
 SG_ OCC_IstModus  : 65|3@1+ (1.000000,0.000000) [0.000000|7.000000] "" Motor_BEV
 SG_ OCC_CP_Status_A  : 68|2@1+ (1.000000,0.000000) [0.000000|3.000000] "" Vector__XXX
 SG_ OCC_CP_Status_B  : 70|2@1+ (1.000000,0.000000) [0.000000|3.000000] "" Vector__XXX
 SG_ OCC_IstSpannung_HV  : 72|10@1+ (1.000000,0.000000) [0.000000|1021.000000] "Unit_Volt" Vector__XXX
 SG_ OCC_PP_Status_A  : 82|2@1+ (1.000000,0.000000) [0.000000|3.000000] "" Vector__XXX
 SG_ OCC_PP_Status_B  : 84|2@1+ (1.000000,0.000000) [0.000000|3.000000] "" Vector__XXX
 SG_ OCC_CC_Status_DC_GBT  : 86|2@1+ (1.000000,0.000000) [0.000000|3.000000] "" Vector__XXX
 SG_ OCC_CC_Fehlerstatus_DC_GBT  : 88|4@1+ (1.000000,0.000000) [0.000000|15.000000] "" Vector__XXX
 SG_ OCC_Temp_Sensor_Fehlerstatus_DC  : 92|4@1+ (1.000000,0.000000) [0.000000|15.000000] "" Vector__XXX
 SG_ OCC_Temp_Sensor_Fehlerstatus_AC  : 96|3@1+ (1.000000,0.000000) [0.000000|7.000000] "" Vector__XXX
 SG_ OCC_Temp_Sensor_Status  : 99|3@1+ (1.000000,0.000000) [0.000000|7.000000] "" Vector__XXX

BU_:  Airbag BAP_Tester ICAS1_Gateway ICAS1_KommunikationsServer LE1 LE2 Motor_BEV Schaltbetaetigung

BO_ 190 Motor_56: 48 Motor_BEV
 SG_ Motor_56_CRC  : 0|8@1+ (1.000000,0.000000) [0.000000|255.000000] "" ICAS1_Gateway LE1 LE2
 SG_ Motor_56_BZ  : 8|4@1+ (1.000000,0.000000) [0.000000|15.000000] "" ICAS1_Gateway LE1 LE2
 SG_ MO_EM1_MinDrehzahl  : 12|14@1+ (2.000000,-10000.000000) [-10000.000000|22764.000000] "Unit_MinutInver" ICAS1_Gateway LE1
 SG_ MO_EM1_MaxDrehzahl  : 26|14@1+ (2.000000,-10000.000000) [-10000.000000|22764.000000] "Unit_MinutInver" ICAS1_Gateway LE1
 SG_ MO_EM1_DynLimit_AR  : 40|8@1+ (1.000000,0.000000) [0.000000|254.000000] "Unit_NewtoMeter" ICAS1_Gateway LE1
 SG_ MO_EM1_Periode_AR  : 48|8@1+ (0.001953,0.000000) [0.000000|0.496094] "Unit_Secon" ICAS1_Gateway LE1
 SG_ MO_EM1_SollMoment  : 56|12@1+ (0.500000,-1023.000000) [-1023.000000|1023.500000] "Unit_NewtoMeter" ICAS1_Gateway LE1
 SG_ MO_EM1_Sollmodus  : 68|4@1+ (1.000000,0.000000) [0.000000|15.000000] "" ICAS1_Gateway LE1
 SG_ MO_EM1_Min_Leistung  : 72|14@1+ (100.000000,-819000.000000) [-819000.000000|819100.000000] "Unit_Watt" ICAS1_Gateway LE1
 SG_ MO_EM1_Max_Leistung  : 86|14@1+ (100.000000,-819000.000000) [-819000.000000|819100.000000] "Unit_Watt" ICAS1_Gateway LE1
 SG_ MO_EM1_Min_Strom_Lim  : 100|13@1+ (0.500000,-2047.000000) [-2047.000000|2047.500000] "Unit_Amper" ICAS1_Gateway LE1
 SG_ MO_EM1_Max_Strom_Lim  : 113|13@1+ (0.500000,-2047.000000) [-2047.000000|2047.500000] "Unit_Amper" ICAS1_Gateway LE1
 SG_ MO_EM1_AR_Anf  : 126|3@1+ (1.000000,0.000000) [0.000000|7.000000] "" ICAS1_Gateway LE1
 SG_ MO_EM1_Kp_AR  : 129|9@1+ (0.003906,0.000000) [0.000000|1.992188] "Unit_NewtoMeterPerRPM" ICAS1_Gateway LE1
 SG_ MO_EM1_SollSpannung  : 138|12@1+ (0.500000,0.000000) [0.000000|2047.000000] "Unit_Volt" ICAS1_Gateway LE1
 SG_ MO_EM2_MinDrehzahl  : 156|14@1+ (2.000000,-10000.000000) [-10000.000000|22764.000000] "Unit_MinutInver" ICAS1_Gateway LE2
 SG_ MO_EM2_MaxDrehzahl  : 170|14@1+ (2.000000,-10000.000000) [-10000.000000|22764.000000] "Unit_MinutInver" ICAS1_Gateway LE2
 SG_ MO_EM2_DynLimit_AR  : 184|8@1+ (1.000000,0.000000) [0.000000|254.000000] "Unit_NewtoMeter" ICAS1_Gateway LE2
 SG_ MO_EM2_Periode_AR  : 192|8@1+ (0.001953,0.000000) [0.000000|0.496094] "Unit_Secon" ICAS1_Gateway LE2
 SG_ MO_EM2_SollMoment  : 200|12@1+ (0.500000,-1023.000000) [-1023.000000|1023.500000] "Unit_NewtoMeter" ICAS1_Gateway LE2
 SG_ MO_EM2_Sollmodus  : 212|4@1+ (1.000000,0.000000) [0.000000|15.000000] "" ICAS1_Gateway LE2
 SG_ MO_EM2_Min_Leistung  : 216|14@1+ (100.000000,-819000.000000) [-819000.000000|819100.000000] "Unit_Watt" ICAS1_Gateway LE2
 SG_ MO_EM2_Max_Leistung  : 230|14@1+ (100.000000,-819000.000000) [-819000.000000|819100.000000] "Unit_Watt" ICAS1_Gateway LE2
 SG_ MO_EM2_Min_Strom_Lim  : 244|13@1+ (0.500000,-2047.000000) [-2047.000000|2047.500000] "Unit_Amper" ICAS1_Gateway LE2
 SG_ MO_EM2_Max_Strom_Lim  : 257|13@1+ (0.500000,-2047.000000) [-2047.000000|2047.500000] "Unit_Amper" ICAS1_Gateway LE2
 SG_ MO_EM2_AR_Anf  : 270|3@1+ (1.000000,0.000000) [0.000000|7.000000] "" ICAS1_Gateway LE2
 SG_ MO_EM2_SollSpannung  : 282|12@1+ (0.500000,0.000000) [0.000000|2047.000000] "Unit_Volt" ICAS1_Gateway LE2
 SG_ MO_DC_Max_Strom_HV  : 296|8@1+ (0.200000,0.000000) [0.000000|50.800000] "Unit_Amper" ICAS1_Gateway
 SG_ MO_DC_SollSpannung_HV  : 304|8@1+ (2.000000,0.000000) [0.000000|508.000000] "Unit_Volt" ICAS1_Gateway
 SG_ MO_EM1_Max_Moment  : 312|12@1+ (0.500000,-1023.000000) [-1023.000000|1023.500000] "Unit_NewtoMeter" ICAS1_Gateway LE1
 SG_ MO_EM1_Min_Moment  : 324|12@1+ (0.500000,-1023.000000) [-1023.000000|1023.500000] "Unit_NewtoMeter" ICAS1_Gateway LE1
 SG_ MO_EM2_Max_Moment  : 336|12@1+ (0.500000,-1023.000000) [-1023.000000|1023.500000] "Unit_NewtoMeter" ICAS1_Gateway LE2
 SG_ MO_EM2_Min_Moment  : 348|12@1+ (0.500000,-1023.000000) [-1023.000000|1023.500000] "Unit_NewtoMeter" ICAS1_Gateway LE2

BO_ 2463978666 Motor_57: 32 Motor_BEV
 SG_ MO_EM1_Min_Spannung_Lim  : 12|10@1+ (1.000000,0.000000) [0.000000|1021.000000] "Unit_Volt" ICAS1_Gateway LE1
 SG_ MO_EM1_Max_Spannung_Lim  : 22|10@1+ (1.000000,0.000000) [0.000000|1021.000000] "Unit_Volt" ICAS1_Gateway LE1
 SG_ MO_EM1_Min_Leistung_Gesamt  : 32|13@1+ (200.000000,-819000.000000) [-819000.000000|818800.000000] "Unit_Watt" ICAS1_Gateway LE1
 SG_ MO_EM1_Max_Leistung_Gesamt  : 45|13@1+ (200.000000,-819000.000000) [-819000.000000|818800.000000] "Unit_Watt" ICAS1_Gateway LE1
 SG_ MO_EM2_Min_Leistung_Gesamt  : 58|13@1+ (200.000000,-819000.000000) [-819000.000000|818800.000000] "Unit_Watt" ICAS1_Gateway LE2
 SG_ MO_EM2_Max_Leistung_Gesamt  : 71|13@1+ (200.000000,-819000.000000) [-819000.000000|818800.000000] "Unit_Watt" ICAS1_Gateway LE2
 SG_ MO_EM2_Min_Spannung_Lim  : 84|10@1+ (1.000000,0.000000) [0.000000|1021.000000] "Unit_Volt" ICAS1_Gateway LE2
 SG_ MO_EM2_Max_Spannung_Lim  : 94|10@1+ (1.000000,0.000000) [0.000000|1021.000000] "Unit_Volt" ICAS1_Gateway LE2
 SG_ MO_EM1_Generator_Leistung  : 104|8@1+ (100.000000,0.000000) [0.000000|25300.000000] "Unit_Watt" ICAS1_Gateway LE1
 SG_ MO_Verbrauch_EM_Ges  : 120|15@1+ (10.000000,0.000000) [0.000000|327670.000000] "Unit_WattSecond" ICAS1_Gateway ICAS1_KommunikationsServer
 SG_ MO_Verbrauch_EM_Ges_Ueberlauf  : 135|1@1+ (1.000000,0.000000) [0.000000|1.000000] "" ICAS1_Gateway ICAS1_KommunikationsServer
 SG_ MO_Rekuperation_Ges_EM  : 136|15@1+ (10.000000,0.000000) [0.000000|327670.000000] "Unit_WattSecond" ICAS1_Gateway ICAS1_KommunikationsServer
 SG_ MO_Rekuperation_EM_Ges_Ueberlauf  : 151|1@1+ (1.000000,0.000000) [0.000000|1.000000] "" ICAS1_Gateway ICAS1_KommunikationsServer
 SG_ MO_Drehzahl_EM  : 152|13@1+ (8.000000,-32768.000000) [-32768.000000|32744.000000] "Unit_RevPerMinute" ICAS1_Gateway
 SG_ MO_Uebersetzung_EM  : 165|10@1+ (0.031250,0.000000) [0.031250|31.906250] "" ICAS1_Gateway
 SG_ MO_Drehzahl_EM_sek  : 175|13@1+ (8.000000,-32768.000000) [-32768.000000|32744.000000] "Unit_RevPerMinute" ICAS1_Gateway
 SG_ MO_Uebersetzung_EM_sek  : 188|10@1+ (0.031250,0.000000) [0.031250|31.906250] "" ICAS1_Gateway

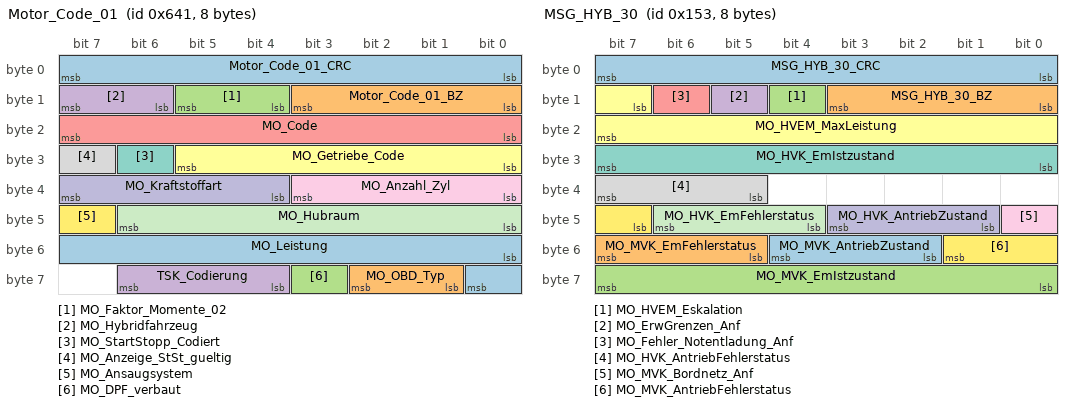
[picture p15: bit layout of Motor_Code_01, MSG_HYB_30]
BO_ 1601 Motor_Code_01: 8 Motor_BEV
 SG_ Motor_Code_01_CRC  : 0|8@1+ (1.000000,0.000000) [0.000000|255.000000] "" ICAS1_Gateway
 SG_ Motor_Code_01_BZ  : 8|4@1+ (1.000000,0.000000) [0.000000|15.000000] "" ICAS1_Gateway
 SG_ MO_Faktor_Momente_02  : 12|2@1+ (1.000000,0.000000) [1.000000|3.000000] "Unit_NewtoMeter" ICAS1_Gateway
 SG_ MO_Hybridfahrzeug  : 14|2@1+ (1.000000,0.000000) [0.000000|3.000000] "" ICAS1_Gateway
 SG_ MO_Code  : 16|8@1+ (1.000000,0.000000) [0.000000|255.000000] "" ICAS1_Gateway
 SG_ MO_Getriebe_Code  : 24|6@1+ (1.000000,0.000000) [0.000000|63.000000] "" ICAS1_Gateway
 SG_ MO_StartStopp_Codiert  : 30|1@1+ (1.000000,0.000000) [0.000000|1.000000] "" ICAS1_Gateway
 SG_ MO_Anzeige_StSt_gueltig  : 31|1@1+ (1.000000,0.000000) [0.000000|1.000000] "" ICAS1_Gateway
 SG_ MO_Anzahl_Zyl  : 32|4@1+ (1.000000,0.000000) [0.000000|15.000000] "" ICAS1_Gateway
 SG_ MO_Kraftstoffart  : 36|4@1+ (1.000000,0.000000) [0.000000|15.000000] "" ICAS1_Gateway ICAS1_KommunikationsServer
 SG_ MO_Hubraum  : 40|7@1+ (0.100000,0.000000) [0.000000|12.700000] "Unit_Liter" ICAS1_Gateway
 SG_ MO_Ansaugsystem  : 47|1@1+ (1.000000,0.000000) [0.000000|1.000000] "" ICAS1_Gateway
 SG_ MO_Leistung  : 48|9@1+ (1.000000,0.000000) [0.000000|511.000000] "Unit_KiloWatt" ICAS1_Gateway
 SG_ MO_OBD_Typ  : 57|2@1+ (1.000000,0.000000) [0.000000|3.000000] "" ICAS1_Gateway
 SG_ MO_DPF_verbaut  : 59|1@1+ (1.000000,0.000000) [0.000000|1.000000] "" ICAS1_Gateway
 SG_ TSK_Codierung  : 60|3@1+ (1.000000,0.000000) [0.000000|7.000000] "" ICAS1_Gateway

BO_ 1155 Motor_Hybrid_06: 8 Motor_BEV
 SG_ Mo_Powermeter_Grenze  : 0|12@1+ (1.000000,0.000000) [0.000000|4092.000000] "" ICAS1_KommunikationsServer
 SG_ MO_Text_Aktivierung_Antrieb  : 12|4@1+ (1.000000,0.000000) [0.000000|15.000000] "" ICAS1_KommunikationsServer
 SG_ MO_Powermeter_Inszenierung_aktiv  : 17|1@1+ (1.000000,0.000000) [0.000000|1.000000] "" Vector__XXX
 SG_ MO_Powermeter_Charge_Grenze  : 18|10@1+ (1.000000,0.000000) [0.000000|1021.000000] "Unit_None" ICAS1_KommunikationsServer
 SG_ MO_Powermeter_Grenze_strategisch  : 28|12@1+ (1.000000,0.000000) [0.000000|4093.000000] "Unit_None" ICAS1_KommunikationsServer
 SG_ MO_Powermeter_untere_E_Grenze  : 40|12@1+ (1.000000,0.000000) [0.000000|4093.000000] "Unit_None" Vector__XXX
 SG_ MO_Powermeter_obere_E_Grenze  : 52|12@1+ (1.000000,0.000000) [0.000000|4093.000000] "Unit_None" Vector__XXX

BO_ 2527679686 MRR_ASM_01: 8 ICAS1_Gateway
 SG_ MRR_HR_ASM_Ereignis  : 0|8@1+ (1.000000,0.000000) [1.000000|254.000000] "" Airbag
 SG_ MRR_HR_ASM_Zeitstempel  : 8|8@1+ (0.080000,0.000000) [0.000000|20.320000] "Unit_Secon" Airbag
 SG_ MRR_HR_ASM_Data_1  : 16|8@1+ (1.000000,0.000000) [0.000000|255.000000] "" Airbag
 SG_ MRR_HR_ASM_Data_2  : 24|8@1+ (1.000000,0.000000) [0.000000|255.000000] "" Airbag
 SG_ MRR_HR_ASM_Data_3  : 32|8@1+ (1.000000,0.000000) [0.000000|255.000000] "" Airbag
 SG_ MRR_HR_ASM_Data_4  : 40|8@1+ (1.000000,0.000000) [0.000000|255.000000] "" Airbag
 SG_ MRR_HR_ASM_Data_5  : 48|8@1+ (1.000000,0.000000) [0.000000|255.000000] "" Airbag
 SG_ MRR_HR_ASM_Data_6  : 56|8@1+ (1.000000,0.000000) [0.000000|255.000000] "" Airbag

BO_ 22 MSG3_WFS_Anfrage: 8 LE2
 SG_ WFS_MSG3_RND  : 0|32@1+ (1.000000,0.000000) [0.000000|4294967295.000000] "" ICAS1_Gateway
 SG_ WFS_MSG3_CRC  : 32|32@1+ (1.000000,0.000000) [0.000000|4294967295.000000] "" ICAS1_Gateway

BO_ 24 MSG4_WFS_Anfrage: 8 LE1
 SG_ WFS_MSG4_RND  : 0|32@1+ (1.000000,0.000000) [0.000000|4294967295.000000] "" ICAS1_Gateway
 SG_ WFS_MSG4_CRC  : 32|32@1+ (1.000000,0.000000) [0.000000|4294967295.000000] "" ICAS1_Gateway

BO_ 339 MSG_HYB_30: 8 Motor_BEV
 SG_ MSG_HYB_30_CRC  : 0|8@1+ (1.000000,0.000000) [0.000000|255.000000] "" Vector__XXX
 SG_ MSG_HYB_30_BZ  : 8|4@1+ (1.000000,0.000000) [0.000000|15.000000] "" Vector__XXX
 SG_ MO_HVEM_Eskalation  : 12|1@1+ (1.000000,0.000000) [0.000000|1.000000] "" ICAS1_Gateway
 SG_ MO_ErwGrenzen_Anf  : 13|1@1+ (1.000000,0.000000) [0.000000|1.000000] "" LE1 LE2
 SG_ MO_Fehler_Notentladung_Anf  : 14|1@1+ (1.000000,0.000000) [0.000000|1.000000] "" Vector__XXX
 SG_ MO_HVEM_MaxLeistung  : 15|9@1+ (50.000000,0.000000) [0.000000|25450.000000] "Unit_Watt" ICAS1_Gateway
 SG_ MO_HVK_EmIstzustand  : 24|8@1+ (1.000000,0.000000) [0.000000|255.000000] "" Vector__XXX
 SG_ MO_HVK_AntriebFehlerstatus  : 37|3@1+ (1.000000,0.000000) [0.000000|7.000000] "" Vector__XXX
 SG_ MO_MVK_Bordnetz_Anf  : 40|1@1+ (1.000000,0.000000) [0.000000|1.000000] "" Vector__XXX
 SG_ MO_HVK_AntriebZustand  : 41|3@1+ (1.000000,0.000000) [0.000000|7.000000] "" Vector__XXX
 SG_ MO_HVK_EmFehlerstatus  : 44|3@1+ (1.000000,0.000000) [0.000000|7.000000] "" Vector__XXX
 SG_ MO_MVK_AntriebFehlerstatus  : 47|3@1+ (1.000000,0.000000) [0.000000|7.000000] "" Vector__XXX
 SG_ MO_MVK_AntriebZustand  : 50|3@1+ (1.000000,0.000000) [0.000000|7.000000] "" Vector__XXX
 SG_ MO_MVK_EmFehlerstatus  : 53|3@1+ (1.000000,0.000000) [0.000000|7.000000] "" Vector__XXX
 SG_ MO_MVK_EmIstzustand  : 56|8@1+ (1.000000,0.000000) [0.000000|255.000000] "" Vector__XXX

BO_ 2600468501 NMH_Airbag_01: 8 Airbag
 SG_ NM_Airbag_01_CBV_AWB  : 12|1@1+ (1.000000,0.000000) [0.000000|1.000000] "" ICAS1_Gateway
 SG_ NM_Airbag_01_CBV_CRI  : 14|1@1+ (1.000000,0.000000) [0.000000|1.000000] "" ICAS1_Gateway
 SG_ NM_Airbag_01_NM_State  : 16|6@1+ (1.000000,0.000000) [0.000000|63.000000] "" LE1 LE2 Motor_BEV Schaltbetaetigung
 SG_ NM_Airbag_01_Car_Wakeup  : 22|1@1+ (1.000000,0.000000) [0.000000|1.000000] "" ICAS1_Gateway
 SG_ NM_Airbag_01_UDS_CC  : 23|1@1+ (1.000000,0.000000) [0.000000|1.000000] "" Vector__XXX
 SG_ NM_Airbag_01_NM_aktiv_KL15  : 24|1@1+ (1.000000,0.000000) [0.000000|1.000000] "" Vector__XXX
 SG_ NM_Airbag_01_NM_aktiv_Diagnose  : 25|1@1+ (1.000000,0.000000) [0.000000|1.000000] "" Vector__XXX
 SG_ NM_Airbag_01_NM_aktiv_Tmin  : 26|1@1+ (1.000000,0.000000) [0.000000|1.000000] "" Vector__XXX
 SG_ NM_Airbag_01_CAB_V10  : 40|24@1+ (1.000000,0.000000) [0.000000|16777215.000000] "" ICAS1_Gateway

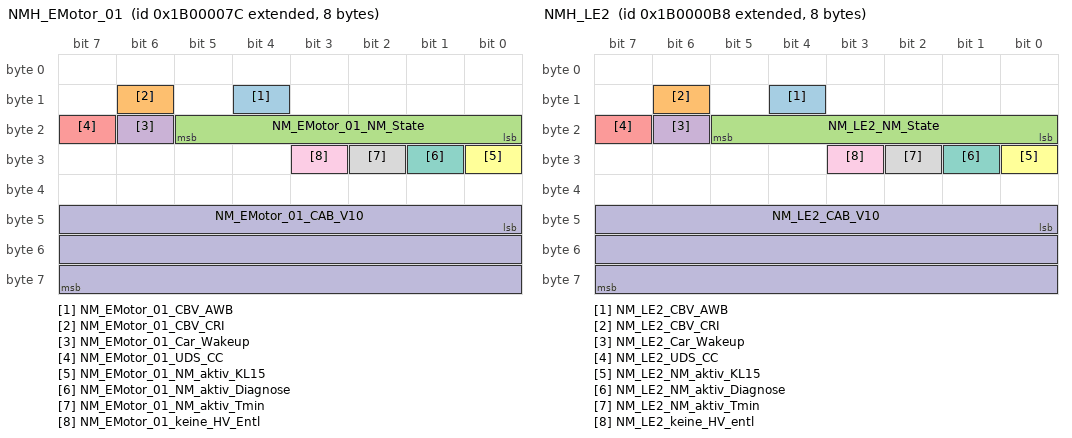
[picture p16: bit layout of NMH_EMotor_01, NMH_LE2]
BO_ 2600468604 NMH_EMotor_01: 8 LE1
 SG_ NM_EMotor_01_CBV_AWB  : 12|1@1+ (1.000000,0.000000) [0.000000|1.000000] "" ICAS1_Gateway
 SG_ NM_EMotor_01_CBV_CRI  : 14|1@1+ (1.000000,0.000000) [0.000000|1.000000] "" ICAS1_Gateway
 SG_ NM_EMotor_01_NM_State  : 16|6@1+ (1.000000,0.000000) [0.000000|63.000000] "" Airbag LE2 Motor_BEV Schaltbetaetigung
 SG_ NM_EMotor_01_Car_Wakeup  : 22|1@1+ (1.000000,0.000000) [0.000000|1.000000] "" ICAS1_Gateway
 SG_ NM_EMotor_01_UDS_CC  : 23|1@1+ (1.000000,0.000000) [0.000000|1.000000] "" Vector__XXX
 SG_ NM_EMotor_01_NM_aktiv_KL15  : 24|1@1+ (1.000000,0.000000) [0.000000|1.000000] "" Vector__XXX
 SG_ NM_EMotor_01_NM_aktiv_Diagnose  : 25|1@1+ (1.000000,0.000000) [0.000000|1.000000] "" Vector__XXX
 SG_ NM_EMotor_01_NM_aktiv_Tmin  : 26|1@1+ (1.000000,0.000000) [0.000000|1.000000] "" Vector__XXX
 SG_ NM_EMotor_01_keine_HV_Entl  : 27|1@1+ (1.000000,0.000000) [0.000000|1.000000] "" Vector__XXX
 SG_ NM_EMotor_01_CAB_V10  : 40|24@1+ (1.000000,0.000000) [0.000000|16777215.000000] "" ICAS1_Gateway

BO_ 2600468496 NMH_Gateway: 8 ICAS1_Gateway
 SG_ NM_Gateway_CBV_AWB  : 12|1@1+ (1.000000,0.000000) [0.000000|1.000000] "" Vector__XXX
 SG_ NM_Gateway_CBV_CRI  : 14|1@1+ (1.000000,0.000000) [0.000000|1.000000] "" Vector__XXX
 SG_ NM_Gateway_NM_State  : 16|6@1+ (1.000000,0.000000) [0.000000|63.000000] "" Airbag LE1 LE2 Motor_BEV Schaltbetaetigung
 SG_ NM_Gateway_Car_Wakeup  : 22|1@1+ (1.000000,0.000000) [0.000000|1.000000] "" Vector__XXX
 SG_ NM_Gateway_UDS_CC  : 23|1@1+ (1.000000,0.000000) [0.000000|1.000000] "" Vector__XXX
 SG_ NM_Gateway_NM_aktiv_KL15  : 24|1@1+ (1.000000,0.000000) [0.000000|1.000000] "" Vector__XXX
 SG_ NM_Gateway_NM_aktiv_Diagnose  : 25|1@1+ (1.000000,0.000000) [0.000000|1.000000] "" Vector__XXX
 SG_ NM_Gateway_NM_aktiv_Tmin  : 26|1@1+ (1.000000,0.000000) [0.000000|1.000000] "" Vector__XXX
 SG_ NM_Gateway_CAB_V10  : 40|24@1+ (1.000000,0.000000) [0.000000|16777215.000000] "" Vector__XXX

BO_ 2600468664 NMH_LE2: 8 LE2
 SG_ NM_LE2_CBV_AWB  : 12|1@1+ (1.000000,0.000000) [0.000000|1.000000] "" ICAS1_Gateway
 SG_ NM_LE2_CBV_CRI  : 14|1@1+ (1.000000,0.000000) [0.000000|1.000000] "" ICAS1_Gateway
 SG_ NM_LE2_NM_State  : 16|6@1+ (1.000000,0.000000) [0.000000|63.000000] "" Airbag LE1 Motor_BEV Schaltbetaetigung
 SG_ NM_LE2_Car_Wakeup  : 22|1@1+ (1.000000,0.000000) [0.000000|1.000000] "" ICAS1_Gateway
 SG_ NM_LE2_UDS_CC  : 23|1@1+ (1.000000,0.000000) [0.000000|1.000000] "" Vector__XXX
 SG_ NM_LE2_NM_aktiv_KL15  : 24|1@1+ (1.000000,0.000000) [0.000000|1.000000] "" Vector__XXX
 SG_ NM_LE2_NM_aktiv_Diagnose  : 25|1@1+ (1.000000,0.000000) [0.000000|1.000000] "" Vector__XXX
 SG_ NM_LE2_NM_aktiv_Tmin  : 26|1@1+ (1.000000,0.000000) [0.000000|1.000000] "" Vector__XXX
 SG_ NM_LE2_keine_HV_entl  : 27|1@1+ (1.000000,0.000000) [0.000000|1.000000] "" Vector__XXX
 SG_ NM_LE2_CAB_V10  : 40|24@1+ (1.000000,0.000000) [0.000000|16777215.000000] "" ICAS1_Gateway

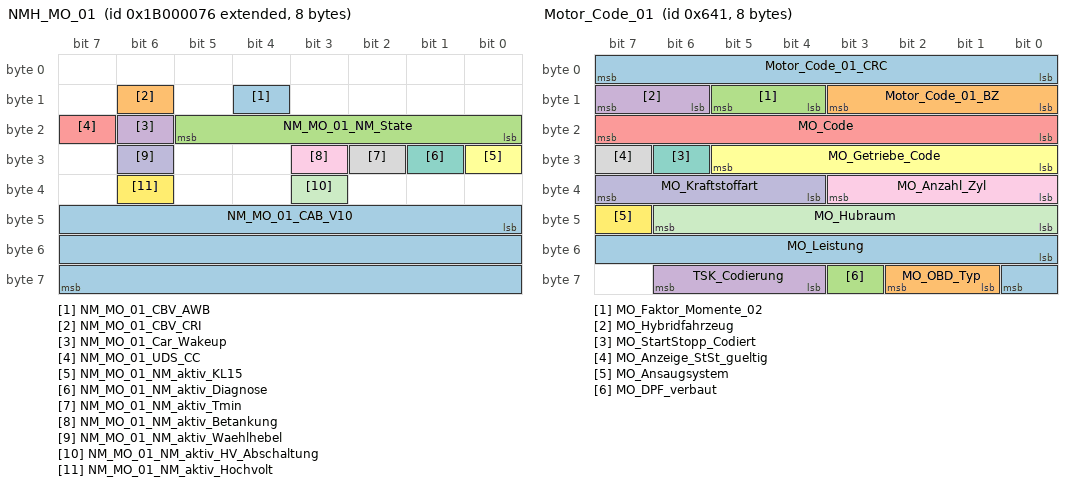
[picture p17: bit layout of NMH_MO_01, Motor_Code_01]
BO_ 2600468598 NMH_MO_01: 8 Motor_BEV
 SG_ NM_MO_01_CBV_AWB  : 12|1@1+ (1.000000,0.000000) [0.000000|1.000000] "" ICAS1_Gateway
 SG_ NM_MO_01_CBV_CRI  : 14|1@1+ (1.000000,0.000000) [0.000000|1.000000] "" ICAS1_Gateway
 SG_ NM_MO_01_NM_State  : 16|6@1+ (1.000000,0.000000) [0.000000|63.000000] "" Airbag LE1 LE2 Schaltbetaetigung
 SG_ NM_MO_01_Car_Wakeup  : 22|1@1+ (1.000000,0.000000) [0.000000|1.000000] "" ICAS1_Gateway
 SG_ NM_MO_01_UDS_CC  : 23|1@1+ (1.000000,0.000000) [0.000000|1.000000] "" Vector__XXX
 SG_ NM_MO_01_NM_aktiv_KL15  : 24|1@1+ (1.000000,0.000000) [0.000000|1.000000] "" Vector__XXX
 SG_ NM_MO_01_NM_aktiv_Diagnose  : 25|1@1+ (1.000000,0.000000) [0.000000|1.000000] "" Vector__XXX
 SG_ NM_MO_01_NM_aktiv_Tmin  : 26|1@1+ (1.000000,0.000000) [0.000000|1.000000] "" Vector__XXX
 SG_ NM_MO_01_NM_aktiv_Betankung  : 27|1@1+ (1.000000,0.000000) [0.000000|1.000000] "" Vector__XXX
 SG_ NM_MO_01_NM_aktiv_Waehlhebel  : 30|1@1+ (1.000000,0.000000) [0.000000|1.000000] "" Vector__XXX
 SG_ NM_MO_01_NM_aktiv_HV_Abschaltung  : 35|1@1+ (1.000000,0.000000) [0.000000|1.000000] "" Vector__XXX
 SG_ NM_MO_01_NM_aktiv_Hochvolt  : 38|1@1+ (1.000000,0.000000) [0.000000|1.000000] "" Vector__XXX
 SG_ NM_MO_01_CAB_V10  : 40|24@1+ (1.000000,0.000000) [0.000000|16777215.000000] "" ICAS1_Gateway

BO_ 2600468733 NMH_Waehlhebel: 8 Schaltbetaetigung
 SG_ NM_Waehlhebel_CBV_AWB  : 12|1@1+ (1.000000,0.000000) [0.000000|1.000000] "" ICAS1_Gateway
 SG_ NM_Waehlhebel_CBV_CRI  : 14|1@1+ (1.000000,0.000000) [0.000000|1.000000] "" ICAS1_Gateway
 SG_ NM_Waehlhebel_NM_State  : 16|6@1+ (1.000000,0.000000) [0.000000|63.000000] "" Airbag LE1 LE2 Motor_BEV
 SG_ NM_Waehlhebel_Car_Wakeup  : 22|1@1+ (1.000000,0.000000) [0.000000|1.000000] "" ICAS1_Gateway
 SG_ NM_Waehlhebel_UDS_CC  : 23|1@1+ (1.000000,0.000000) [0.000000|1.000000] "" Vector__XXX
 SG_ NM_Waehlhebel_NM_aktiv_KL15  : 24|1@1+ (1.000000,0.000000) [0.000000|1.000000] "" Vector__XXX
 SG_ NM_Waehlhebel_NM_aktiv_Diagnose  : 25|1@1+ (1.000000,0.000000) [0.000000|1.000000] "" Vector__XXX
 SG_ NM_Waehlhebel_NM_aktiv_Tmin  : 26|1@1+ (1.000000,0.000000) [0.000000|1.000000] "" Vector__XXX
 SG_ NM_Waehlhebel_CAB_V10  : 40|24@1+ (1.000000,0.000000) [0.000000|16777215.000000] "" ICAS1_Gateway

BO_ 2621440533 OBDC_Airbag_01_Req_FD: 64 ICAS1_Gateway
 SG_ OBDC_Airbag_01_Req_FD_Data  : 0|512@1+ (1.000000,0.000000) [0.000000|13407807929942597099574024998205846127479365820592393377723561443721764030073546976801874298166903427690031858186486050853753882811946569946433649006084096.000000] "" Airbag

BO_ 2621571605 OBDC_Airbag_01_Resp_FD: 64 Airbag
 SG_ OBDC_Airbag_01_Resp_FD_Data  : 0|512@1+ (1.000000,0.000000) [0.000000|13407807929942597099574024998205846127479365820592393377723561443721764030073546976801874298166903427690031858186486050853753882811946569946433649006084096.000000] "" ICAS1_Gateway

BO_ 2621440636 OBDC_EMotor_01_Req_FD: 64 ICAS1_Gateway
 SG_ OBDC_EMotor_01_Req_FD_Data  : 0|512@1+ (1.000000,0.000000) [0.000000|13407807929942597099574024998205846127479365820592393377723561443721764030073546976801874298166903427690031858186486050853753882811946569946433649006084096.000000] "" LE1

BO_ 2621571708 OBDC_EMotor_01_Resp_FD: 64 LE1
 SG_ OBDC_EMotor_01_Resp_FD_Data  : 0|512@1+ (1.000000,0.000000) [0.000000|13407807929942597099574024998205846127479365820592393377723561443721764030073546976801874298166903427690031858186486050853753882811946569946433649006084096.000000] "" ICAS1_Gateway

BO_ 2621440696 OBDC_EMotor_02_Req_FD: 64 ICAS1_Gateway
 SG_ OBDC_EMotor_02_Req_FD_Data  : 0|512@1+ (1.000000,0.000000) [0.000000|13407807929942597099574024998205846127479365820592393377723561443721764030073546976801874298166903427690031858186486050853753882811946569946433649006084096.000000] "" LE2

BO_ 2621571768 OBDC_EMotor_02_Resp_FD: 64 LE2
 SG_ OBDC_EMotor_02_Resp_FD_Data  : 0|512@1+ (1.000000,0.000000) [0.000000|13407807929942597099574024998205846127479365820592393377723561443721764030073546976801874298166903427690031858186486050853753882811946569946433649006084096.000000] "" ICAS1_Gateway

BO_ 2621506048 OBDC_Funktionaler_Req_All_FD: 64 ICAS1_Gateway
 SG_ OBDC_Funktion_Req_All_FD_Data  : 0|512@1+ (1.000000,0.000000) [0.000000|13407807929942597099574024998205846127479365820592393377723561443721764030073546976801874298166903427690031858186486050853753882811946569946433649006084096.000000] "" Airbag LE1 LE2 Motor_BEV

BO_ 2621440630 OBDC_MO_01_Req_FD: 64 ICAS1_Gateway
 SG_ OBDC_MO_01_Req_FD_Data  : 0|512@1+ (1.000000,0.000000) [0.000000|13407807929942597099574024998205846127479365820592393377723561443721764030073546976801874298166903427690031858186486050853753882811946569946433649006084096.000000] "" Motor_BEV

BO_ 2621571702 OBDC_MO_01_Resp_FD: 64 Motor_BEV
 SG_ OBDC_MO_01_Resp_FD_Data  : 0|512@1+ (1.000000,0.000000) [0.000000|13407807929942597099574024998205846127479365820592393377723561443721764030073546976801874298166903427690031858186486050853753882811946569946433649006084096.000000] "" ICAS1_Gateway

BO_ 2564502513 OBDx_allOBD_Req: 8 ICAS1_Gateway
 SG_ OBDx_allOBD_Req_Data  : 0|64@1+ (1.000000,0.000000) [0.000000|18446744073709551616.000000] "" LE1 LE2 Motor_BEV

BO_ 2564425457 OBDx_LE1_Req: 8 ICAS1_Gateway
 SG_ OBDx_LE1_Req_Data  : 0|64@1+ (1.000000,0.000000) [0.000000|18446744073709551616.000000] "" LE1

BO_ 2564485382 OBDx_LE1_Resp: 8 LE1
 SG_ OBDx_LE1_Resp_Data  : 0|64@1+ (1.000000,0.000000) [0.000000|18446744073709551616.000000] "" ICAS1_Gateway

BO_ 2564425713 OBDx_LE2_Req: 8 ICAS1_Gateway
 SG_ OBDx_LE2_Req_Data  : 0|64@1+ (1.000000,0.000000) [0.000000|18446744073709551616.000000] "" LE2

BO_ 2564485383 OBDx_LE2_Resp: 8 LE2
 SG_ OBDx_LE2_Resp_Data  : 0|64@1+ (1.000000,0.000000) [0.000000|18446744073709551616.000000] "" ICAS1_Gateway

BO_ 2564424177 OBDx_MO_01_Req: 8 ICAS1_Gateway
 SG_ OBDx_MO_01_Req_Data  : 0|64@1+ (1.000000,0.000000) [0.000000|18446744073709551616.000000] "" Motor_BEV

BO_ 2564485377 OBDx_MO_01_Resp: 8 Motor_BEV
 SG_ OBDx_MO_01_Resp_Data  : 0|64@1+ (1.000000,0.000000) [0.000000|18446744073709551616.000000] "" ICAS1_Gateway

BO_ 627 OCC_01: 24 ICAS1_Gateway
 SG_ OCC_01_CRC  : 0|8@1+ (1.000000,0.000000) [0.000000|255.000000] "" Vector__XXX
 SG_ OCC_01_BZ  : 8|4@1+ (1.000000,0.000000) [0.000000|15.000000] "" Vector__XXX
 SG_ OCC_Stecker_Status  : 12|2@1+ (1.000000,0.000000) [0.000000|3.000000] "" Vector__XXX
 SG_ OCC_Status_Spgfreiheit  : 14|2@1+ (1.000000,0.000000) [0.000000|3.000000] "" Motor_BEV
 SG_ OCC_DC_IstStrom  : 16|11@1+ (0.100000,0.000000) [0.000000|204.500000] "Unit_Amper" Vector__XXX
 SG_ OCC_CC_Latchstatus_DC_GBT  : 27|3@1+ (1.000000,0.000000) [0.000000|7.000000] "" Vector__XXX
 SG_ OCC_Status_EoHVL  : 30|2@1+ (1.000000,0.000000) [0.000000|3.000000] "" Motor_BEV
 SG_ OCC_I_istAC_Netz_L1  : 32|9@1+ (0.100000,0.000000) [0.000000|50.800000] "Unit_Amper" Vector__XXX
 SG_ OCC_PP_Latchstatus_A  : 41|3@1+ (1.000000,0.000000) [0.000000|7.000000] "" Vector__XXX
 SG_ OCC_PP_Latchstatus_B  : 44|3@1+ (1.000000,0.000000) [0.000000|7.000000] "" Vector__XXX
 SG_ OCC_I_istAC_Netz_L2  : 47|9@1+ (0.100000,0.000000) [0.000000|50.800000] "Unit_Amper" Vector__XXX
 SG_ OCC_I_istAC_Netz_L3  : 56|9@1+ (0.100000,0.000000) [0.000000|50.800000] "Unit_Amper" Vector__XXX
 SG_ OCC_IstModus  : 65|3@1+ (1.000000,0.000000) [0.000000|7.000000] "" Motor_BEV
 SG_ OCC_CP_Status_A  : 68|2@1+ (1.000000,0.000000) [0.000000|3.000000] "" Vector__XXX
 SG_ OCC_CP_Status_B  : 70|2@1+ (1.000000,0.000000) [0.000000|3.000000] "" Vector__XXX
 SG_ OCC_IstSpannung_HV  : 72|10@1+ (1.000000,0.000000) [0.000000|1021.000000] "Unit_Volt" Vector__XXX
 SG_ OCC_PP_Status_A  : 82|2@1+ (1.000000,0.000000) [0.000000|3.000000] "" Vector__XXX
 SG_ OCC_PP_Status_B  : 84|2@1+ (1.000000,0.000000) [0.000000|3.000000] "" Vector__XXX
 SG_ OCC_CC_Status_DC_GBT  : 86|2@1+ (1.000000,0.000000) [0.000000|3.000000] "" Vector__XXX
 SG_ OCC_CC_Fehlerstatus_DC_GBT  : 88|4@1+ (1.000000,0.000000) [0.000000|15.000000] "" Vector__XXX
 SG_ OCC_Temp_Sensor_Fehlerstatus_DC  : 92|4@1+ (1.000000,0.000000) [0.000000|15.000000] "" Vector__XXX
 SG_ OCC_Temp_Sensor_Fehlerstatus_AC  : 96|3@1+ (1.000000,0.000000) [0.000000|7.000000] "" Vector__XXX
 SG_ OCC_Temp_Sensor_Status  : 99|3@1+ (1.000000,0.000000) [0.000000|7.000000] "" Vector__XXX

BU_:  Airbag BAP_Tester ICAS1_Gateway ICAS1_KommunikationsServer LE1 LE2 Motor_BEV Schaltbetaetigung

BO_ 190 Motor_56: 48 Motor_BEV
 SG_ Motor_56_CRC  : 0|8@1+ (1.000000,0.000000) [0.000000|255.000000] "" ICAS1_Gateway LE1 LE2
 SG_ Motor_56_BZ  : 8|4@1+ (1.000000,0.000000) [0.000000|15.000000] "" ICAS1_Gateway LE1 LE2
 SG_ MO_EM1_MinDrehzahl  : 12|14@1+ (2.000000,-10000.000000) [-10000.000000|22764.000000] "Unit_MinutInver" ICAS1_Gateway LE1
 SG_ MO_EM1_MaxDrehzahl  : 26|14@1+ (2.000000,-10000.000000) [-10000.000000|22764.000000] "Unit_MinutInver" ICAS1_Gateway LE1
 SG_ MO_EM1_DynLimit_AR  : 40|8@1+ (1.000000,0.000000) [0.000000|254.000000] "Unit_NewtoMeter" ICAS1_Gateway LE1
 SG_ MO_EM1_Periode_AR  : 48|8@1+ (0.001953,0.000000) [0.000000|0.496094] "Unit_Secon" ICAS1_Gateway LE1
 SG_ MO_EM1_SollMoment  : 56|12@1+ (0.500000,-1023.000000) [-1023.000000|1023.500000] "Unit_NewtoMeter" ICAS1_Gateway LE1
 SG_ MO_EM1_Sollmodus  : 68|4@1+ (1.000000,0.000000) [0.000000|15.000000] "" ICAS1_Gateway LE1
 SG_ MO_EM1_Min_Leistung  : 72|14@1+ (100.000000,-819000.000000) [-819000.000000|819100.000000] "Unit_Watt" ICAS1_Gateway LE1
 SG_ MO_EM1_Max_Leistung  : 86|14@1+ (100.000000,-819000.000000) [-819000.000000|819100.000000] "Unit_Watt" ICAS1_Gateway LE1
 SG_ MO_EM1_Min_Strom_Lim  : 100|13@1+ (0.500000,-2047.000000) [-2047.000000|2047.500000] "Unit_Amper" ICAS1_Gateway LE1
 SG_ MO_EM1_Max_Strom_Lim  : 113|13@1+ (0.500000,-2047.000000) [-2047.000000|2047.500000] "Unit_Amper" ICAS1_Gateway LE1
 SG_ MO_EM1_AR_Anf  : 126|3@1+ (1.000000,0.000000) [0.000000|7.000000] "" ICAS1_Gateway LE1
 SG_ MO_EM1_Kp_AR  : 129|9@1+ (0.003906,0.000000) [0.000000|1.992188] "Unit_NewtoMeterPerRPM" ICAS1_Gateway LE1
 SG_ MO_EM1_SollSpannung  : 138|12@1+ (0.500000,0.000000) [0.000000|2047.000000] "Unit_Volt" ICAS1_Gateway LE1
 SG_ MO_EM2_MinDrehzahl  : 156|14@1+ (2.000000,-10000.000000) [-10000.000000|22764.000000] "Unit_MinutInver" ICAS1_Gateway LE2
 SG_ MO_EM2_MaxDrehzahl  : 170|14@1+ (2.000000,-10000.000000) [-10000.000000|22764.000000] "Unit_MinutInver" ICAS1_Gateway LE2
 SG_ MO_EM2_DynLimit_AR  : 184|8@1+ (1.000000,0.000000) [0.000000|254.000000] "Unit_NewtoMeter" ICAS1_Gateway LE2
 SG_ MO_EM2_Periode_AR  : 192|8@1+ (0.001953,0.000000) [0.000000|0.496094] "Unit_Secon" ICAS1_Gateway LE2
 SG_ MO_EM2_SollMoment  : 200|12@1+ (0.500000,-1023.000000) [-1023.000000|1023.500000] "Unit_NewtoMeter" ICAS1_Gateway LE2
 SG_ MO_EM2_Sollmodus  : 212|4@1+ (1.000000,0.000000) [0.000000|15.000000] "" ICAS1_Gateway LE2
 SG_ MO_EM2_Min_Leistung  : 216|14@1+ (100.000000,-819000.000000) [-819000.000000|819100.000000] "Unit_Watt" ICAS1_Gateway LE2
 SG_ MO_EM2_Max_Leistung  : 230|14@1+ (100.000000,-819000.000000) [-819000.000000|819100.000000] "Unit_Watt" ICAS1_Gateway LE2
 SG_ MO_EM2_Min_Strom_Lim  : 244|13@1+ (0.500000,-2047.000000) [-2047.000000|2047.500000] "Unit_Amper" ICAS1_Gateway LE2
 SG_ MO_EM2_Max_Strom_Lim  : 257|13@1+ (0.500000,-2047.000000) [-2047.000000|2047.500000] "Unit_Amper" ICAS1_Gateway LE2
 SG_ MO_EM2_AR_Anf  : 270|3@1+ (1.000000,0.000000) [0.000000|7.000000] "" ICAS1_Gateway LE2
 SG_ MO_EM2_SollSpannung  : 282|12@1+ (0.500000,0.000000) [0.000000|2047.000000] "Unit_Volt" ICAS1_Gateway LE2
 SG_ MO_DC_Max_Strom_HV  : 296|8@1+ (0.200000,0.000000) [0.000000|50.800000] "Unit_Amper" ICAS1_Gateway
 SG_ MO_DC_SollSpannung_HV  : 304|8@1+ (2.000000,0.000000) [0.000000|508.000000] "Unit_Volt" ICAS1_Gateway
 SG_ MO_EM1_Max_Moment  : 312|12@1+ (0.500000,-1023.000000) [-1023.000000|1023.500000] "Unit_NewtoMeter" ICAS1_Gateway LE1
 SG_ MO_EM1_Min_Moment  : 324|12@1+ (0.500000,-1023.000000) [-1023.000000|1023.500000] "Unit_NewtoMeter" ICAS1_Gateway LE1
 SG_ MO_EM2_Max_Moment  : 336|12@1+ (0.500000,-1023.000000) [-1023.000000|1023.500000] "Unit_NewtoMeter" ICAS1_Gateway LE2
 SG_ MO_EM2_Min_Moment  : 348|12@1+ (0.500000,-1023.000000) [-1023.000000|1023.500000] "Unit_NewtoMeter" ICAS1_Gateway LE2

BO_ 2463978666 Motor_57: 32 Motor_BEV
 SG_ MO_EM1_Min_Spannung_Lim  : 12|10@1+ (1.000000,0.000000) [0.000000|1021.000000] "Unit_Volt" ICAS1_Gateway LE1
 SG_ MO_EM1_Max_Spannung_Lim  : 22|10@1+ (1.000000,0.000000) [0.000000|1021.000000] "Unit_Volt" ICAS1_Gateway LE1
 SG_ MO_EM1_Min_Leistung_Gesamt  : 32|13@1+ (200.000000,-819000.000000) [-819000.000000|818800.000000] "Unit_Watt" ICAS1_Gateway LE1
 SG_ MO_EM1_Max_Leistung_Gesamt  : 45|13@1+ (200.000000,-819000.000000) [-819000.000000|818800.000000] "Unit_Watt" ICAS1_Gateway LE1
 SG_ MO_EM2_Min_Leistung_Gesamt  : 58|13@1+ (200.000000,-819000.000000) [-819000.000000|818800.000000] "Unit_Watt" ICAS1_Gateway LE2
 SG_ MO_EM2_Max_Leistung_Gesamt  : 71|13@1+ (200.000000,-819000.000000) [-819000.000000|818800.000000] "Unit_Watt" ICAS1_Gateway LE2
 SG_ MO_EM2_Min_Spannung_Lim  : 84|10@1+ (1.000000,0.000000) [0.000000|1021.000000] "Unit_Volt" ICAS1_Gateway LE2
 SG_ MO_EM2_Max_Spannung_Lim  : 94|10@1+ (1.000000,0.000000) [0.000000|1021.000000] "Unit_Volt" ICAS1_Gateway LE2
 SG_ MO_EM1_Generator_Leistung  : 104|8@1+ (100.000000,0.000000) [0.000000|25300.000000] "Unit_Watt" ICAS1_Gateway LE1
 SG_ MO_Verbrauch_EM_Ges  : 120|15@1+ (10.000000,0.000000) [0.000000|327670.000000] "Unit_WattSecond" ICAS1_Gateway ICAS1_KommunikationsServer
 SG_ MO_Verbrauch_EM_Ges_Ueberlauf  : 135|1@1+ (1.000000,0.000000) [0.000000|1.000000] "" ICAS1_Gateway ICAS1_KommunikationsServer
 SG_ MO_Rekuperation_Ges_EM  : 136|15@1+ (10.000000,0.000000) [0.000000|327670.000000] "Unit_WattSecond" ICAS1_Gateway ICAS1_KommunikationsServer
 SG_ MO_Rekuperation_EM_Ges_Ueberlauf  : 151|1@1+ (1.000000,0.000000) [0.000000|1.000000] "" ICAS1_Gateway ICAS1_KommunikationsServer
 SG_ MO_Drehzahl_EM  : 152|13@1+ (8.000000,-32768.000000) [-32768.000000|32744.000000] "Unit_RevPerMinute" ICAS1_Gateway
 SG_ MO_Uebersetzung_EM  : 165|10@1+ (0.031250,0.000000) [0.031250|31.906250] "" ICAS1_Gateway
 SG_ MO_Drehzahl_EM_sek  : 175|13@1+ (8.000000,-32768.000000) [-32768.000000|32744.000000] "Unit_RevPerMinute" ICAS1_Gateway
 SG_ MO_Uebersetzung_EM_sek  : 188|10@1+ (0.031250,0.000000) [0.031250|31.906250] "" ICAS1_Gateway

BO_ 1601 Motor_Code_01: 8 Motor_BEV
 SG_ Motor_Code_01_CRC  : 0|8@1+ (1.000000,0.000000) [0.000000|255.000000] "" ICAS1_Gateway
 SG_ Motor_Code_01_BZ  : 8|4@1+ (1.000000,0.000000) [0.000000|15.000000] "" ICAS1_Gateway
 SG_ MO_Faktor_Momente_02  : 12|2@1+ (1.000000,0.000000) [1.000000|3.000000] "Unit_NewtoMeter" ICAS1_Gateway
 SG_ MO_Hybridfahrzeug  : 14|2@1+ (1.000000,0.000000) [0.000000|3.000000] "" ICAS1_Gateway
 SG_ MO_Code  : 16|8@1+ (1.000000,0.000000) [0.000000|255.000000] "" ICAS1_Gateway
 SG_ MO_Getriebe_Code  : 24|6@1+ (1.000000,0.000000) [0.000000|63.000000] "" ICAS1_Gateway
 SG_ MO_StartStopp_Codiert  : 30|1@1+ (1.000000,0.000000) [0.000000|1.000000] "" ICAS1_Gateway
 SG_ MO_Anzeige_StSt_gueltig  : 31|1@1+ (1.000000,0.000000) [0.000000|1.000000] "" ICAS1_Gateway
 SG_ MO_Anzahl_Zyl  : 32|4@1+ (1.000000,0.000000) [0.000000|15.000000] "" ICAS1_Gateway
 SG_ MO_Kraftstoffart  : 36|4@1+ (1.000000,0.000000) [0.000000|15.000000] "" ICAS1_Gateway ICAS1_KommunikationsServer
 SG_ MO_Hubraum  : 40|7@1+ (0.100000,0.000000) [0.000000|12.700000] "Unit_Liter" ICAS1_Gateway
 SG_ MO_Ansaugsystem  : 47|1@1+ (1.000000,0.000000) [0.000000|1.000000] "" ICAS1_Gateway
 SG_ MO_Leistung  : 48|9@1+ (1.000000,0.000000) [0.000000|511.000000] "Unit_KiloWatt" ICAS1_Gateway
 SG_ MO_OBD_Typ  : 57|2@1+ (1.000000,0.000000) [0.000000|3.000000] "" ICAS1_Gateway
 SG_ MO_DPF_verbaut  : 59|1@1+ (1.000000,0.000000) [0.000000|1.000000] "" ICAS1_Gateway
 SG_ TSK_Codierung  : 60|3@1+ (1.000000,0.000000) [0.000000|7.000000] "" ICAS1_Gateway

BO_ 1155 Motor_Hybrid_06: 8 Motor_BEV
 SG_ Mo_Powermeter_Grenze  : 0|12@1+ (1.000000,0.000000) [0.000000|4092.000000] "" ICAS1_KommunikationsServer
 SG_ MO_Text_Aktivierung_Antrieb  : 12|4@1+ (1.000000,0.000000) [0.000000|15.000000] "" ICAS1_KommunikationsServer
 SG_ MO_Powermeter_Inszenierung_aktiv  : 17|1@1+ (1.000000,0.000000) [0.000000|1.000000] "" Vector__XXX
 SG_ MO_Powermeter_Charge_Grenze  : 18|10@1+ (1.000000,0.000000) [0.000000|1021.000000] "Unit_None" ICAS1_KommunikationsServer
 SG_ MO_Powermeter_Grenze_strategisch  : 28|12@1+ (1.000000,0.000000) [0.000000|4093.000000] "Unit_None" ICAS1_KommunikationsServer
 SG_ MO_Powermeter_untere_E_Grenze  : 40|12@1+ (1.000000,0.000000) [0.000000|4093.000000] "Unit_None" Vector__XXX
 SG_ MO_Powermeter_obere_E_Grenze  : 52|12@1+ (1.000000,0.000000) [0.000000|4093.000000] "Unit_None" Vector__XXX

BO_ 2527679686 MRR_ASM_01: 8 ICAS1_Gateway
 SG_ MRR_HR_ASM_Ereignis  : 0|8@1+ (1.000000,0.000000) [1.000000|254.000000] "" Airbag
 SG_ MRR_HR_ASM_Zeitstempel  : 8|8@1+ (0.080000,0.000000) [0.000000|20.320000] "Unit_Secon" Airbag
 SG_ MRR_HR_ASM_Data_1  : 16|8@1+ (1.000000,0.000000) [0.000000|255.000000] "" Airbag
 SG_ MRR_HR_ASM_Data_2  : 24|8@1+ (1.000000,0.000000) [0.000000|255.000000] "" Airbag
 SG_ MRR_HR_ASM_Data_3  : 32|8@1+ (1.000000,0.000000) [0.000000|255.000000] "" Airbag
 SG_ MRR_HR_ASM_Data_4  : 40|8@1+ (1.000000,0.000000) [0.000000|255.000000] "" Airbag
 SG_ MRR_HR_ASM_Data_5  : 48|8@1+ (1.000000,0.000000) [0.000000|255.000000] "" Airbag
 SG_ MRR_HR_ASM_Data_6  : 56|8@1+ (1.000000,0.000000) [0.000000|255.000000] "" Airbag

BO_ 22 MSG3_WFS_Anfrage: 8 LE2
 SG_ WFS_MSG3_RND  : 0|32@1+ (1.000000,0.000000) [0.000000|4294967295.000000] "" ICAS1_Gateway
 SG_ WFS_MSG3_CRC  : 32|32@1+ (1.000000,0.000000) [0.000000|4294967295.000000] "" ICAS1_Gateway

BO_ 24 MSG4_WFS_Anfrage: 8 LE1
 SG_ WFS_MSG4_RND  : 0|32@1+ (1.000000,0.000000) [0.000000|4294967295.000000] "" ICAS1_Gateway
 SG_ WFS_MSG4_CRC  : 32|32@1+ (1.000000,0.000000) [0.000000|4294967295.000000] "" ICAS1_Gateway

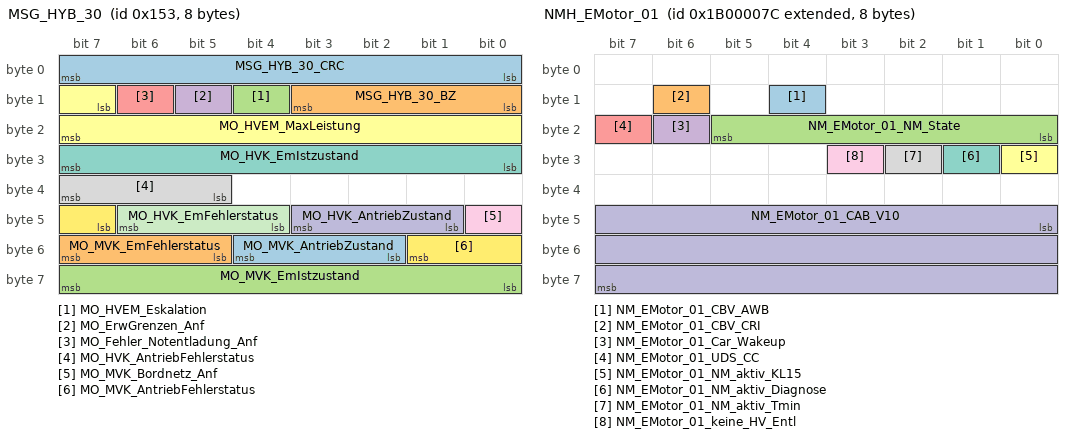
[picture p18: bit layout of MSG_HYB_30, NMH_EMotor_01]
BO_ 339 MSG_HYB_30: 8 Motor_BEV
 SG_ MSG_HYB_30_CRC  : 0|8@1+ (1.000000,0.000000) [0.000000|255.000000] "" Vector__XXX
 SG_ MSG_HYB_30_BZ  : 8|4@1+ (1.000000,0.000000) [0.000000|15.000000] "" Vector__XXX
 SG_ MO_HVEM_Eskalation  : 12|1@1+ (1.000000,0.000000) [0.000000|1.000000] "" ICAS1_Gateway
 SG_ MO_ErwGrenzen_Anf  : 13|1@1+ (1.000000,0.000000) [0.000000|1.000000] "" LE1 LE2
 SG_ MO_Fehler_Notentladung_Anf  : 14|1@1+ (1.000000,0.000000) [0.000000|1.000000] "" Vector__XXX
 SG_ MO_HVEM_MaxLeistung  : 15|9@1+ (50.000000,0.000000) [0.000000|25450.000000] "Unit_Watt" ICAS1_Gateway
 SG_ MO_HVK_EmIstzustand  : 24|8@1+ (1.000000,0.000000) [0.000000|255.000000] "" Vector__XXX
 SG_ MO_HVK_AntriebFehlerstatus  : 37|3@1+ (1.000000,0.000000) [0.000000|7.000000] "" Vector__XXX
 SG_ MO_MVK_Bordnetz_Anf  : 40|1@1+ (1.000000,0.000000) [0.000000|1.000000] "" Vector__XXX
 SG_ MO_HVK_AntriebZustand  : 41|3@1+ (1.000000,0.000000) [0.000000|7.000000] "" Vector__XXX
 SG_ MO_HVK_EmFehlerstatus  : 44|3@1+ (1.000000,0.000000) [0.000000|7.000000] "" Vector__XXX
 SG_ MO_MVK_AntriebFehlerstatus  : 47|3@1+ (1.000000,0.000000) [0.000000|7.000000] "" Vector__XXX
 SG_ MO_MVK_AntriebZustand  : 50|3@1+ (1.000000,0.000000) [0.000000|7.000000] "" Vector__XXX
 SG_ MO_MVK_EmFehlerstatus  : 53|3@1+ (1.000000,0.000000) [0.000000|7.000000] "" Vector__XXX
 SG_ MO_MVK_EmIstzustand  : 56|8@1+ (1.000000,0.000000) [0.000000|255.000000] "" Vector__XXX

BO_ 2600468501 NMH_Airbag_01: 8 Airbag
 SG_ NM_Airbag_01_CBV_AWB  : 12|1@1+ (1.000000,0.000000) [0.000000|1.000000] "" ICAS1_Gateway
 SG_ NM_Airbag_01_CBV_CRI  : 14|1@1+ (1.000000,0.000000) [0.000000|1.000000] "" ICAS1_Gateway
 SG_ NM_Airbag_01_NM_State  : 16|6@1+ (1.000000,0.000000) [0.000000|63.000000] "" LE1 LE2 Motor_BEV Schaltbetaetigung
 SG_ NM_Airbag_01_Car_Wakeup  : 22|1@1+ (1.000000,0.000000) [0.000000|1.000000] "" ICAS1_Gateway
 SG_ NM_Airbag_01_UDS_CC  : 23|1@1+ (1.000000,0.000000) [0.000000|1.000000] "" Vector__XXX
 SG_ NM_Airbag_01_NM_aktiv_KL15  : 24|1@1+ (1.000000,0.000000) [0.000000|1.000000] "" Vector__XXX
 SG_ NM_Airbag_01_NM_aktiv_Diagnose  : 25|1@1+ (1.000000,0.000000) [0.000000|1.000000] "" Vector__XXX
 SG_ NM_Airbag_01_NM_aktiv_Tmin  : 26|1@1+ (1.000000,0.000000) [0.000000|1.000000] "" Vector__XXX
 SG_ NM_Airbag_01_CAB_V10  : 40|24@1+ (1.000000,0.000000) [0.000000|16777215.000000] "" ICAS1_Gateway

BO_ 2600468604 NMH_EMotor_01: 8 LE1
 SG_ NM_EMotor_01_CBV_AWB  : 12|1@1+ (1.000000,0.000000) [0.000000|1.000000] "" ICAS1_Gateway
 SG_ NM_EMotor_01_CBV_CRI  : 14|1@1+ (1.000000,0.000000) [0.000000|1.000000] "" ICAS1_Gateway
 SG_ NM_EMotor_01_NM_State  : 16|6@1+ (1.000000,0.000000) [0.000000|63.000000] "" Airbag LE2 Motor_BEV Schaltbetaetigung
 SG_ NM_EMotor_01_Car_Wakeup  : 22|1@1+ (1.000000,0.000000) [0.000000|1.000000] "" ICAS1_Gateway
 SG_ NM_EMotor_01_UDS_CC  : 23|1@1+ (1.000000,0.000000) [0.000000|1.000000] "" Vector__XXX
 SG_ NM_EMotor_01_NM_aktiv_KL15  : 24|1@1+ (1.000000,0.000000) [0.000000|1.000000] "" Vector__XXX
 SG_ NM_EMotor_01_NM_aktiv_Diagnose  : 25|1@1+ (1.000000,0.000000) [0.000000|1.000000] "" Vector__XXX
 SG_ NM_EMotor_01_NM_aktiv_Tmin  : 26|1@1+ (1.000000,0.000000) [0.000000|1.000000] "" Vector__XXX
 SG_ NM_EMotor_01_keine_HV_Entl  : 27|1@1+ (1.000000,0.000000) [0.000000|1.000000] "" Vector__XXX
 SG_ NM_EMotor_01_CAB_V10  : 40|24@1+ (1.000000,0.000000) [0.000000|16777215.000000] "" ICAS1_Gateway

BO_ 2600468496 NMH_Gateway: 8 ICAS1_Gateway
 SG_ NM_Gateway_CBV_AWB  : 12|1@1+ (1.000000,0.000000) [0.000000|1.000000] "" Vector__XXX
 SG_ NM_Gateway_CBV_CRI  : 14|1@1+ (1.000000,0.000000) [0.000000|1.000000] "" Vector__XXX
 SG_ NM_Gateway_NM_State  : 16|6@1+ (1.000000,0.000000) [0.000000|63.000000] "" Airbag LE1 LE2 Motor_BEV Schaltbetaetigung
 SG_ NM_Gateway_Car_Wakeup  : 22|1@1+ (1.000000,0.000000) [0.000000|1.000000] "" Vector__XXX
 SG_ NM_Gateway_UDS_CC  : 23|1@1+ (1.000000,0.000000) [0.000000|1.000000] "" Vector__XXX
 SG_ NM_Gateway_NM_aktiv_KL15  : 24|1@1+ (1.000000,0.000000) [0.000000|1.000000] "" Vector__XXX
 SG_ NM_Gateway_NM_aktiv_Diagnose  : 25|1@1+ (1.000000,0.000000) [0.000000|1.000000] "" Vector__XXX
 SG_ NM_Gateway_NM_aktiv_Tmin  : 26|1@1+ (1.000000,0.000000) [0.000000|1.000000] "" Vector__XXX
 SG_ NM_Gateway_CAB_V10  : 40|24@1+ (1.000000,0.000000) [0.000000|16777215.000000] "" Vector__XXX

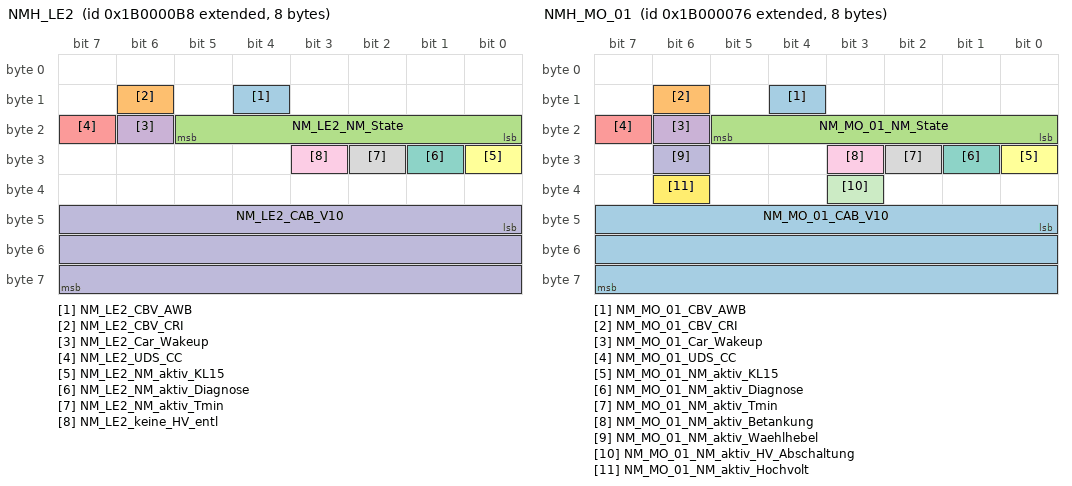
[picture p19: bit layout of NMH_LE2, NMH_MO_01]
BO_ 2600468664 NMH_LE2: 8 LE2
 SG_ NM_LE2_CBV_AWB  : 12|1@1+ (1.000000,0.000000) [0.000000|1.000000] "" ICAS1_Gateway
 SG_ NM_LE2_CBV_CRI  : 14|1@1+ (1.000000,0.000000) [0.000000|1.000000] "" ICAS1_Gateway
 SG_ NM_LE2_NM_State  : 16|6@1+ (1.000000,0.000000) [0.000000|63.000000] "" Airbag LE1 Motor_BEV Schaltbetaetigung
 SG_ NM_LE2_Car_Wakeup  : 22|1@1+ (1.000000,0.000000) [0.000000|1.000000] "" ICAS1_Gateway
 SG_ NM_LE2_UDS_CC  : 23|1@1+ (1.000000,0.000000) [0.000000|1.000000] "" Vector__XXX
 SG_ NM_LE2_NM_aktiv_KL15  : 24|1@1+ (1.000000,0.000000) [0.000000|1.000000] "" Vector__XXX
 SG_ NM_LE2_NM_aktiv_Diagnose  : 25|1@1+ (1.000000,0.000000) [0.000000|1.000000] "" Vector__XXX
 SG_ NM_LE2_NM_aktiv_Tmin  : 26|1@1+ (1.000000,0.000000) [0.000000|1.000000] "" Vector__XXX
 SG_ NM_LE2_keine_HV_entl  : 27|1@1+ (1.000000,0.000000) [0.000000|1.000000] "" Vector__XXX
 SG_ NM_LE2_CAB_V10  : 40|24@1+ (1.000000,0.000000) [0.000000|16777215.000000] "" ICAS1_Gateway

BO_ 2600468598 NMH_MO_01: 8 Motor_BEV
 SG_ NM_MO_01_CBV_AWB  : 12|1@1+ (1.000000,0.000000) [0.000000|1.000000] "" ICAS1_Gateway
 SG_ NM_MO_01_CBV_CRI  : 14|1@1+ (1.000000,0.000000) [0.000000|1.000000] "" ICAS1_Gateway
 SG_ NM_MO_01_NM_State  : 16|6@1+ (1.000000,0.000000) [0.000000|63.000000] "" Airbag LE1 LE2 Schaltbetaetigung
 SG_ NM_MO_01_Car_Wakeup  : 22|1@1+ (1.000000,0.000000) [0.000000|1.000000] "" ICAS1_Gateway
 SG_ NM_MO_01_UDS_CC  : 23|1@1+ (1.000000,0.000000) [0.000000|1.000000] "" Vector__XXX
 SG_ NM_MO_01_NM_aktiv_KL15  : 24|1@1+ (1.000000,0.000000) [0.000000|1.000000] "" Vector__XXX
 SG_ NM_MO_01_NM_aktiv_Diagnose  : 25|1@1+ (1.000000,0.000000) [0.000000|1.000000] "" Vector__XXX
 SG_ NM_MO_01_NM_aktiv_Tmin  : 26|1@1+ (1.000000,0.000000) [0.000000|1.000000] "" Vector__XXX
 SG_ NM_MO_01_NM_aktiv_Betankung  : 27|1@1+ (1.000000,0.000000) [0.000000|1.000000] "" Vector__XXX
 SG_ NM_MO_01_NM_aktiv_Waehlhebel  : 30|1@1+ (1.000000,0.000000) [0.000000|1.000000] "" Vector__XXX
 SG_ NM_MO_01_NM_aktiv_HV_Abschaltung  : 35|1@1+ (1.000000,0.000000) [0.000000|1.000000] "" Vector__XXX
 SG_ NM_MO_01_NM_aktiv_Hochvolt  : 38|1@1+ (1.000000,0.000000) [0.000000|1.000000] "" Vector__XXX
 SG_ NM_MO_01_CAB_V10  : 40|24@1+ (1.000000,0.000000) [0.000000|16777215.000000] "" ICAS1_Gateway

BO_ 2600468733 NMH_Waehlhebel: 8 Schaltbetaetigung
 SG_ NM_Waehlhebel_CBV_AWB  : 12|1@1+ (1.000000,0.000000) [0.000000|1.000000] "" ICAS1_Gateway
 SG_ NM_Waehlhebel_CBV_CRI  : 14|1@1+ (1.000000,0.000000) [0.000000|1.000000] "" ICAS1_Gateway
 SG_ NM_Waehlhebel_NM_State  : 16|6@1+ (1.000000,0.000000) [0.000000|63.000000] "" Airbag LE1 LE2 Motor_BEV
 SG_ NM_Waehlhebel_Car_Wakeup  : 22|1@1+ (1.000000,0.000000) [0.000000|1.000000] "" ICAS1_Gateway
 SG_ NM_Waehlhebel_UDS_CC  : 23|1@1+ (1.000000,0.000000) [0.000000|1.000000] "" Vector__XXX
 SG_ NM_Waehlhebel_NM_aktiv_KL15  : 24|1@1+ (1.000000,0.000000) [0.000000|1.000000] "" Vector__XXX
 SG_ NM_Waehlhebel_NM_aktiv_Diagnose  : 25|1@1+ (1.000000,0.000000) [0.000000|1.000000] "" Vector__XXX
 SG_ NM_Waehlhebel_NM_aktiv_Tmin  : 26|1@1+ (1.000000,0.000000) [0.000000|1.000000] "" Vector__XXX
 SG_ NM_Waehlhebel_CAB_V10  : 40|24@1+ (1.000000,0.000000) [0.000000|16777215.000000] "" ICAS1_Gateway

BO_ 2621440533 OBDC_Airbag_01_Req_FD: 64 ICAS1_Gateway
 SG_ OBDC_Airbag_01_Req_FD_Data  : 0|512@1+ (1.000000,0.000000) [0.000000|13407807929942597099574024998205846127479365820592393377723561443721764030073546976801874298166903427690031858186486050853753882811946569946433649006084096.000000] "" Airbag

BO_ 2621571605 OBDC_Airbag_01_Resp_FD: 64 Airbag
 SG_ OBDC_Airbag_01_Resp_FD_Data  : 0|512@1+ (1.000000,0.000000) [0.000000|13407807929942597099574024998205846127479365820592393377723561443721764030073546976801874298166903427690031858186486050853753882811946569946433649006084096.000000] "" ICAS1_Gateway

BO_ 2621440636 OBDC_EMotor_01_Req_FD: 64 ICAS1_Gateway
 SG_ OBDC_EMotor_01_Req_FD_Data  : 0|512@1+ (1.000000,0.000000) [0.000000|13407807929942597099574024998205846127479365820592393377723561443721764030073546976801874298166903427690031858186486050853753882811946569946433649006084096.000000] "" LE1

BO_ 2621571708 OBDC_EMotor_01_Resp_FD: 64 LE1
 SG_ OBDC_EMotor_01_Resp_FD_Data  : 0|512@1+ (1.000000,0.000000) [0.000000|13407807929942597099574024998205846127479365820592393377723561443721764030073546976801874298166903427690031858186486050853753882811946569946433649006084096.000000] "" ICAS1_Gateway

BO_ 2621440696 OBDC_EMotor_02_Req_FD: 64 ICAS1_Gateway
 SG_ OBDC_EMotor_02_Req_FD_Data  : 0|512@1+ (1.000000,0.000000) [0.000000|13407807929942597099574024998205846127479365820592393377723561443721764030073546976801874298166903427690031858186486050853753882811946569946433649006084096.000000] "" LE2

BO_ 2621571768 OBDC_EMotor_02_Resp_FD: 64 LE2
 SG_ OBDC_EMotor_02_Resp_FD_Data  : 0|512@1+ (1.000000,0.000000) [0.000000|13407807929942597099574024998205846127479365820592393377723561443721764030073546976801874298166903427690031858186486050853753882811946569946433649006084096.000000] "" ICAS1_Gateway

BO_ 2621506048 OBDC_Funktionaler_Req_All_FD: 64 ICAS1_Gateway
 SG_ OBDC_Funktion_Req_All_FD_Data  : 0|512@1+ (1.000000,0.000000) [0.000000|13407807929942597099574024998205846127479365820592393377723561443721764030073546976801874298166903427690031858186486050853753882811946569946433649006084096.000000] "" Airbag LE1 LE2 Motor_BEV

BO_ 2621440630 OBDC_MO_01_Req_FD: 64 ICAS1_Gateway
 SG_ OBDC_MO_01_Req_FD_Data  : 0|512@1+ (1.000000,0.000000) [0.000000|13407807929942597099574024998205846127479365820592393377723561443721764030073546976801874298166903427690031858186486050853753882811946569946433649006084096.000000] "" Motor_BEV

BO_ 2621571702 OBDC_MO_01_Resp_FD: 64 Motor_BEV
 SG_ OBDC_MO_01_Resp_FD_Data  : 0|512@1+ (1.000000,0.000000) [0.000000|13407807929942597099574024998205846127479365820592393377723561443721764030073546976801874298166903427690031858186486050853753882811946569946433649006084096.000000] "" ICAS1_Gateway

BO_ 2564502513 OBDx_allOBD_Req: 8 ICAS1_Gateway
 SG_ OBDx_allOBD_Req_Data  : 0|64@1+ (1.000000,0.000000) [0.000000|18446744073709551616.000000] "" LE1 LE2 Motor_BEV

BO_ 2564425457 OBDx_LE1_Req: 8 ICAS1_Gateway
 SG_ OBDx_LE1_Req_Data  : 0|64@1+ (1.000000,0.000000) [0.000000|18446744073709551616.000000] "" LE1

BO_ 2564485382 OBDx_LE1_Resp: 8 LE1
 SG_ OBDx_LE1_Resp_Data  : 0|64@1+ (1.000000,0.000000) [0.000000|18446744073709551616.000000] "" ICAS1_Gateway

BO_ 2564425713 OBDx_LE2_Req: 8 ICAS1_Gateway
 SG_ OBDx_LE2_Req_Data  : 0|64@1+ (1.000000,0.000000) [0.000000|18446744073709551616.000000] "" LE2

BO_ 2564485383 OBDx_LE2_Resp: 8 LE2
 SG_ OBDx_LE2_Resp_Data  : 0|64@1+ (1.000000,0.000000) [0.000000|18446744073709551616.000000] "" ICAS1_Gateway

BO_ 2564424177 OBDx_MO_01_Req: 8 ICAS1_Gateway
 SG_ OBDx_MO_01_Req_Data  : 0|64@1+ (1.000000,0.000000) [0.000000|18446744073709551616.000000] "" Motor_BEV

BO_ 2564485377 OBDx_MO_01_Resp: 8 Motor_BEV
 SG_ OBDx_MO_01_Resp_Data  : 0|64@1+ (1.000000,0.000000) [0.000000|18446744073709551616.000000] "" ICAS1_Gateway

BO_ 627 OCC_01: 24 ICAS1_Gateway
 SG_ OCC_01_CRC  : 0|8@1+ (1.000000,0.000000) [0.000000|255.000000] "" Vector__XXX
 SG_ OCC_01_BZ  : 8|4@1+ (1.000000,0.000000) [0.000000|15.000000] "" Vector__XXX
 SG_ OCC_Stecker_Status  : 12|2@1+ (1.000000,0.000000) [0.000000|3.000000] "" Vector__XXX
 SG_ OCC_Status_Spgfreiheit  : 14|2@1+ (1.000000,0.000000) [0.000000|3.000000] "" Motor_BEV
 SG_ OCC_DC_IstStrom  : 16|11@1+ (0.100000,0.000000) [0.000000|204.500000] "Unit_Amper" Vector__XXX
 SG_ OCC_CC_Latchstatus_DC_GBT  : 27|3@1+ (1.000000,0.000000) [0.000000|7.000000] "" Vector__XXX
 SG_ OCC_Status_EoHVL  : 30|2@1+ (1.000000,0.000000) [0.000000|3.000000] "" Motor_BEV
 SG_ OCC_I_istAC_Netz_L1  : 32|9@1+ (0.100000,0.000000) [0.000000|50.800000] "Unit_Amper" Vector__XXX
 SG_ OCC_PP_Latchstatus_A  : 41|3@1+ (1.000000,0.000000) [0.000000|7.000000] "" Vector__XXX
 SG_ OCC_PP_Latchstatus_B  : 44|3@1+ (1.000000,0.000000) [0.000000|7.000000] "" Vector__XXX
 SG_ OCC_I_istAC_Netz_L2  : 47|9@1+ (0.100000,0.000000) [0.000000|50.800000] "Unit_Amper" Vector__XXX
 SG_ OCC_I_istAC_Netz_L3  : 56|9@1+ (0.100000,0.000000) [0.000000|50.800000] "Unit_Amper" Vector__XXX
 SG_ OCC_IstModus  : 65|3@1+ (1.000000,0.000000) [0.000000|7.000000] "" Motor_BEV
 SG_ OCC_CP_Status_A  : 68|2@1+ (1.000000,0.000000) [0.000000|3.000000] "" Vector__XXX
 SG_ OCC_CP_Status_B  : 70|2@1+ (1.000000,0.000000) [0.000000|3.000000] "" Vector__XXX
 SG_ OCC_IstSpannung_HV  : 72|10@1+ (1.000000,0.000000) [0.000000|1021.000000] "Unit_Volt" Vector__XXX
 SG_ OCC_PP_Status_A  : 82|2@1+ (1.000000,0.000000) [0.000000|3.000000] "" Vector__XXX
 SG_ OCC_PP_Status_B  : 84|2@1+ (1.000000,0.000000) [0.000000|3.000000] "" Vector__XXX
 SG_ OCC_CC_Status_DC_GBT  : 86|2@1+ (1.000000,0.000000) [0.000000|3.000000] "" Vector__XXX
 SG_ OCC_CC_Fehlerstatus_DC_GBT  : 88|4@1+ (1.000000,0.000000) [0.000000|15.000000] "" Vector__XXX
 SG_ OCC_Temp_Sensor_Fehlerstatus_DC  : 92|4@1+ (1.000000,0.000000) [0.000000|15.000000] "" Vector__XXX
 SG_ OCC_Temp_Sensor_Fehlerstatus_AC  : 96|3@1+ (1.000000,0.000000) [0.000000|7.000000] "" Vector__XXX
 SG_ OCC_Temp_Sensor_Status  : 99|3@1+ (1.000000,0.000000) [0.000000|7.000000] "" Vector__XXX
